VERSION "12.2.7"

NS_ :

BS_:

BU_: ACM ADAS_Body APM ASU_Gateway BCM BCM_BPM CCU_F CCU_R DUMMY_BCM_BPM ETG LDM_L LDM_R OCS_P PSM_D SRR_RR_M SHVU_F SHVU_R TRM USS_F USS_R XGW_Body

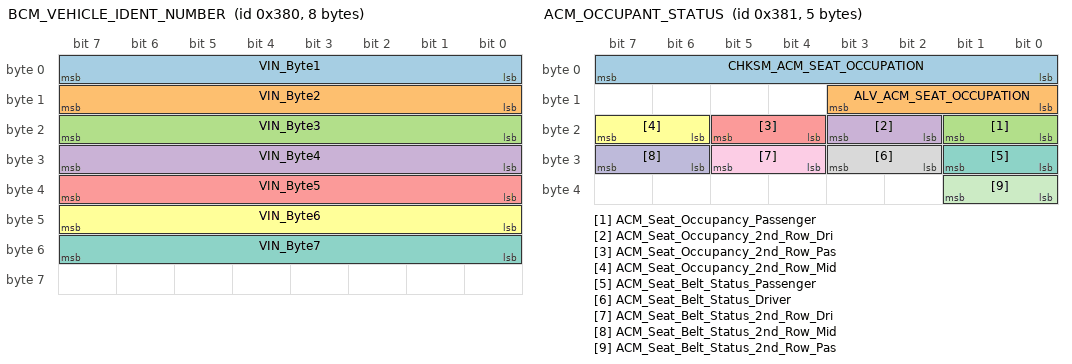
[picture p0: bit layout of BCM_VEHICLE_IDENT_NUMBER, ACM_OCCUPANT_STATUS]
BO_ 896 BCM_VEHICLE_IDENT_NUMBER: 8 BCM
 SG_ VIN_Byte1 : 7|8@0+ (1,0) [0|255] ""  ACM,APM,ASU_Gateway,BCM_BPM,CCU_F,CCU_R,ETG,LDM_L,LDM_R,OCS_P,PSM_D,SHVU_F,SHVU_R,TRM,XGW_Body
 SG_ VIN_Byte2 : 15|8@0+ (1,0) [0|255] ""  ACM,APM,ASU_Gateway,BCM_BPM,CCU_F,CCU_R,ETG,LDM_L,LDM_R,OCS_P,PSM_D,SHVU_F,SHVU_R,TRM,XGW_Body
 SG_ VIN_Byte3 : 23|8@0+ (1,0) [0|255] ""  ACM,APM,ASU_Gateway,BCM_BPM,CCU_F,CCU_R,ETG,LDM_L,LDM_R,OCS_P,PSM_D,SHVU_F,SHVU_R,TRM,XGW_Body
 SG_ VIN_Byte4 : 31|8@0+ (1,0) [0|255] ""  ACM,APM,ASU_Gateway,BCM_BPM,CCU_F,CCU_R,ETG,LDM_L,LDM_R,OCS_P,PSM_D,SHVU_F,SHVU_R,TRM,XGW_Body
 SG_ VIN_Byte5 : 39|8@0+ (1,0) [0|255] ""  ACM,APM,ASU_Gateway,BCM_BPM,CCU_F,CCU_R,ETG,LDM_L,LDM_R,OCS_P,PSM_D,SHVU_F,SHVU_R,TRM,XGW_Body
 SG_ VIN_Byte6 : 47|8@0+ (1,0) [0|255] ""  ACM,APM,ASU_Gateway,BCM_BPM,CCU_F,CCU_R,ETG,LDM_L,LDM_R,OCS_P,PSM_D,SHVU_F,SHVU_R,TRM,XGW_Body
 SG_ VIN_Byte7 : 55|8@0+ (1,0) [0|255] ""  ACM,APM,ASU_Gateway,BCM_BPM,CCU_F,CCU_R,ETG,LDM_L,LDM_R,OCS_P,PSM_D,SHVU_F,SHVU_R,TRM,XGW_Body

BO_ 897 ACM_OCCUPANT_STATUS: 5 ACM
 SG_ CHKSM_ACM_SEAT_OCCUPATION : 7|8@0+ (1,0) [0|255] ""  XGW_Body,CCU_F
 SG_ ALV_ACM_SEAT_OCCUPATION : 11|4@0+ (1,0) [0|14] ""  XGW_Body,CCU_F
 SG_ ACM_Seat_Occupancy_Passenger : 17|2@0+ (1,0) [0|3] ""  BCM,XGW_Body,CCU_F
 SG_ ACM_Seat_Occupancy_2nd_Row_Dri : 19|2@0+ (1,0) [0|3] ""  BCM,XGW_Body,CCU_F
 SG_ ACM_Seat_Occupancy_2nd_Row_Pas : 21|2@0+ (1,0) [0|3] "-"  BCM,XGW_Body,CCU_F
 SG_ ACM_Seat_Occupancy_2nd_Row_Mid : 23|2@0+ (1,0) [0|3] "-"  BCM,XGW_Body,CCU_F
 SG_ ACM_Seat_Belt_Status_Passenger : 25|2@0+ (1,0) [0|3] ""  XGW_Body,CCU_F
 SG_ ACM_Seat_Belt_Status_Driver : 27|2@0+ (1,0) [0|3] ""  BCM,XGW_Body,CCU_F
 SG_ ACM_Seat_Belt_Status_2nd_Row_Dri : 29|2@0+ (1,0) [0|3] "-"  XGW_Body,CCU_F
 SG_ ACM_Seat_Belt_Status_2nd_Row_Mid : 31|2@0+ (1,0) [0|3] ""  XGW_Body,CCU_F
 SG_ ACM_Seat_Belt_Status_2nd_Row_Pas : 33|2@0+ (1,0) [0|3] "-"  XGW_Body,CCU_F

BO_ 905 VCU_Sts3: 8 XGW_Body
 SG_ VCU_IMMO_Sts : 35|2@0+ (1,0) [0|3] ""  BCM
 SG_ SECCAN_VCU_IMMO_Sts : 63|8@0+ (1,0) [0|255] ""  BCM

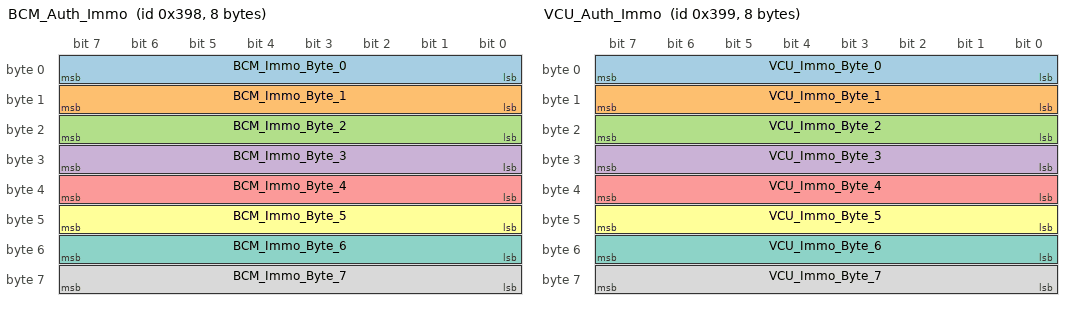
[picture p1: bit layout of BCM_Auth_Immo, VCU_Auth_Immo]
BO_ 920 BCM_Auth_Immo: 8 BCM
 SG_ BCM_Immo_Byte_0 : 7|8@0+ (1,0) [0|255] ""  XGW_Body
 SG_ BCM_Immo_Byte_1 : 15|8@0+ (1,0) [0|255] ""  XGW_Body
 SG_ BCM_Immo_Byte_2 : 23|8@0+ (1,0) [0|255] ""  XGW_Body
 SG_ BCM_Immo_Byte_3 : 31|8@0+ (1,0) [0|255] ""  XGW_Body
 SG_ BCM_Immo_Byte_4 : 39|8@0+ (1,0) [0|255] ""  XGW_Body
 SG_ BCM_Immo_Byte_5 : 47|8@0+ (1,0) [0|255] ""  XGW_Body
 SG_ BCM_Immo_Byte_6 : 55|8@0+ (1,0) [0|255] ""  XGW_Body
 SG_ BCM_Immo_Byte_7 : 63|8@0+ (1,0) [0|255] ""  XGW_Body

BO_ 921 VCU_Auth_Immo: 8 XGW_Body
 SG_ VCU_Immo_Byte_0 : 7|8@0+ (1,0) [0|255] ""  BCM
 SG_ VCU_Immo_Byte_1 : 15|8@0+ (1,0) [0|255] ""  BCM
 SG_ VCU_Immo_Byte_2 : 23|8@0+ (1,0) [0|255] ""  BCM
 SG_ VCU_Immo_Byte_3 : 31|8@0+ (1,0) [0|255] ""  BCM
 SG_ VCU_Immo_Byte_4 : 39|8@0+ (1,0) [0|255] ""  BCM
 SG_ VCU_Immo_Byte_5 : 47|8@0+ (1,0) [0|255] ""  BCM
 SG_ VCU_Immo_Byte_6 : 55|8@0+ (1,0) [0|255] ""  BCM
 SG_ VCU_Immo_Byte_7 : 63|8@0+ (1,0) [0|255] ""  BCM

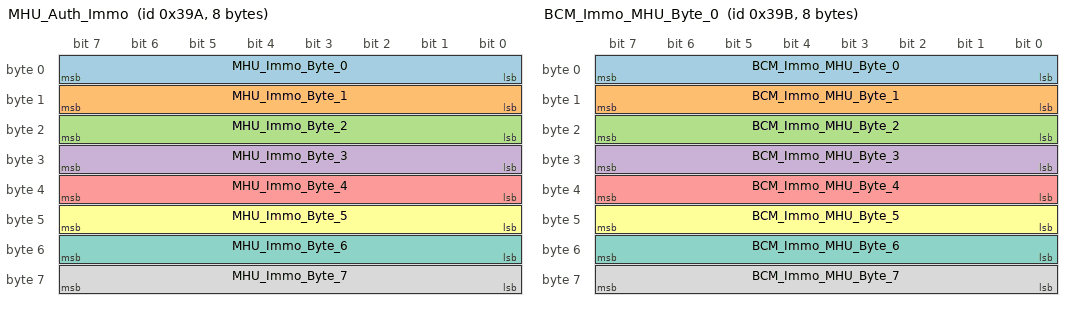
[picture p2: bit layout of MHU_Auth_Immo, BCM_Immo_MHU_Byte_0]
BO_ 922 MHU_Auth_Immo: 8 XGW_Body
 SG_ MHU_Immo_Byte_0 : 7|8@0+ (1,0) [0|255] "-"  BCM
 SG_ MHU_Immo_Byte_1 : 15|8@0+ (1,0) [0|255] "-"  BCM
 SG_ MHU_Immo_Byte_2 : 23|8@0+ (1,0) [0|255] ""  BCM
 SG_ MHU_Immo_Byte_3 : 31|8@0+ (1,0) [0|255] ""  BCM
 SG_ MHU_Immo_Byte_4 : 39|8@0+ (1,0) [0|255] ""  BCM
 SG_ MHU_Immo_Byte_5 : 47|8@0+ (1,0) [0|255] ""  BCM
 SG_ MHU_Immo_Byte_6 : 55|8@0+ (1,0) [0|255] ""  BCM
 SG_ MHU_Immo_Byte_7 : 63|8@0+ (1,0) [0|255] "-"  BCM

BO_ 923 BCM_Immo_MHU_Byte_0: 8 BCM
 SG_ BCM_Immo_MHU_Byte_0 : 7|8@0+ (1,0) [0|255] "-"  XGW_Body
 SG_ BCM_Immo_MHU_Byte_1 : 15|8@0+ (1,0) [0|255] "-"  XGW_Body
 SG_ BCM_Immo_MHU_Byte_2 : 23|8@0+ (1,0) [0|255] "-"  XGW_Body
 SG_ BCM_Immo_MHU_Byte_3 : 31|8@0+ (1,0) [0|255] "-"  XGW_Body
 SG_ BCM_Immo_MHU_Byte_4 : 39|8@0+ (1,0) [0|255] "-"  XGW_Body
 SG_ BCM_Immo_MHU_Byte_5 : 47|8@0+ (1,0) [0|255] ""  XGW_Body
 SG_ BCM_Immo_MHU_Byte_6 : 55|8@0+ (1,0) [0|255] "-"  XGW_Body
 SG_ BCM_Immo_MHU_Byte_7 : 63|8@0+ (1,0) [0|255] "-"  XGW_Body

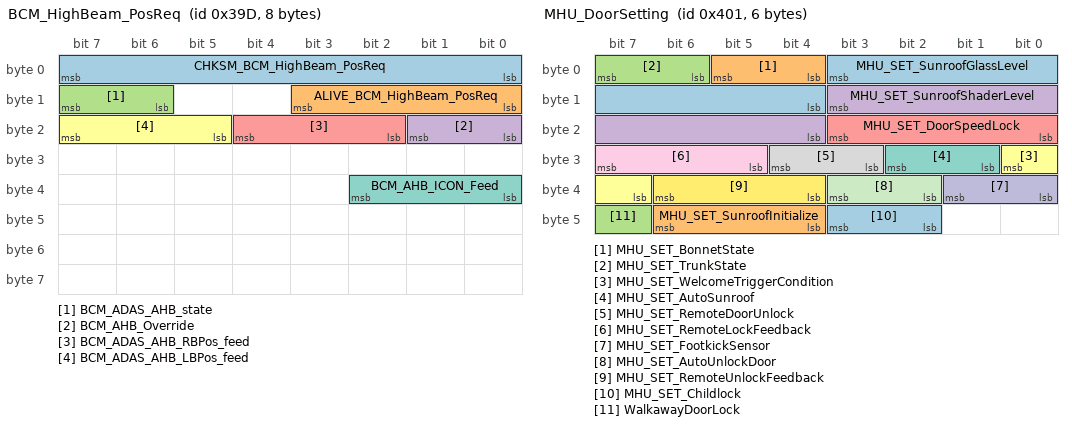
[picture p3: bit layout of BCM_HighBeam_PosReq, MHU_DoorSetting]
BO_ 925 BCM_HighBeam_PosReq: 8 BCM
 SG_ CHKSM_BCM_HighBeam_PosReq : 7|8@0+ (1,0) [0|255] ""  XGW_Body
 SG_ ALIVE_BCM_HighBeam_PosReq : 11|4@0+ (1,0) [0|14] ""  XGW_Body
 SG_ BCM_ADAS_AHB_state : 15|2@0+ (1,0) [0|3] ""  XGW_Body
 SG_ BCM_AHB_Override : 17|2@0+ (1,0) [0|3] ""  LDM_L,LDM_R,XGW_Body
 SG_ BCM_ADAS_AHB_RBPos_feed : 20|3@0+ (1,0) [0|7] ""  XGW_Body
 SG_ BCM_ADAS_AHB_LBPos_feed : 23|3@0+ (1,0) [0|7] ""  XGW_Body
 SG_ BCM_AHB_ICON_Feed : 34|3@0+ (1,0) [0|7] ""  XGW_Body

BO_ 993 VCU_HMI_Info: 8 XGW_Body
 SG_ CRC_VCU_HMI_Info : 7|8@0+ (1,0) [0|255] ""  ACM
 SG_ ALIV_VCU_HMI_Info : 11|4@0+ (1,0) [0|14] ""  ACM
 SG_ VCU_CruiseCtrlSts : 31|3@0+ (1,0) [0|7] ""  ACM

BO_ 1015 MFS_Control_Button: 8 XGW_Body
 SG_ CHSKM_MFS_Control_Button : 7|8@0+ (1,0) [0|255] ""  BCM
 SG_ ALV_MFS_Control_Button : 11|4@0+ (1,0) [0|14] ""  BCM
 SG_ MFS_VoiceRecognitionOn_Off : 15|3@0+ (1,0) [0|4] "Bit"  BCM
 SG_ MFS_ISAControl : 17|2@0+ (1,0) [0|3] "Bit"  BCM
 SG_ MFS_CruiseSpeedIncrease : 20|3@0+ (1,0) [0|4] "Bit"  BCM
 SG_ MFS_TelephoneCall_EndCall : 23|3@0+ (1,0) [0|4] "Bit"  BCM
 SG_ MFS_LKAControl : 25|2@0+ (1,0) [0|3] "Bit"  BCM
 SG_ MFS_CruiseGapIncrease : 28|3@0+ (1,0) [0|4] "Bit"  BCM
 SG_ MFS_CruiseOn_Off : 31|3@0+ (1,0) [0|4] "Bit"  BCM
 SG_ MFS_CruiseGapDecrease : 34|3@0+ (1,0) [0|4] "Bit"  BCM
 SG_ MFS_CAN_RESControl : 36|2@0+ (1,0) [0|3] "-"  BCM
 SG_ MFS_CruiseSpeedDecrease : 39|3@0+ (1,0) [0|4] "Bit"  BCM
 SG_ MFS_M2Control : 41|2@0+ (1,0) [0|3] "Bit"  BCM
 SG_ MFS_SourseControl : 44|3@0+ (1,0) [0|4] "Bit"  BCM
 SG_ MFS_UpControl : 47|3@0+ (1,0) [0|4] "Bit"  BCM
 SG_ MFS_DownControl : 52|3@0+ (1,0) [0|4] "Bit"  BCM
 SG_ MFS_LeftControl : 55|3@0+ (1,0) [0|4] "Bit"  BCM
 SG_ MFS_Failure : 57|1@0+ (1,0) [0|1] "Bit"  BCM
 SG_ MFS_RightControl : 60|3@0+ (1,0) [0|4] "Bit"  BCM
 SG_ MFS_OK_Control : 63|3@0+ (1,0) [0|4] "Bit"  BCM

BO_ 1025 MHU_DoorSetting: 6 XGW_Body
 SG_ MHU_SET_SunroofGlassLevel : 3|8@0+ (1,0) [0|255] "%"  BCM
 SG_ MHU_SET_BonnetState : 5|2@0+ (1,0) [0|3] "-"  BCM
 SG_ MHU_SET_TrunkState : 7|2@0+ (1,0) [0|3] "-"  BCM
 SG_ MHU_SET_SunroofShaderLevel : 11|8@0+ (1,0) [0|255] "%"  BCM
 SG_ MHU_SET_DoorSpeedLock : 19|4@0+ (1,0) [0|7] ""  BCM
 SG_ MHU_SET_WelcomeTriggerCondition : 24|2@0+ (1,0) [0|3] ""  BCM
 SG_ MHU_SET_AutoSunroof : 26|2@0+ (1,0) [0|3] ""  BCM
 SG_ MHU_SET_RemoteDoorUnlock : 28|2@0+ (1,0) [0|3] "-"  BCM
 SG_ MHU_SET_RemoteLockFeedback : 31|3@0+ (1,0) [0|7] "-"  BCM
 SG_ MHU_SET_FootkickSensor : 33|2@0+ (1,0) [0|3] "-"  BCM
 SG_ MHU_SET_AutoUnlockDoor : 35|2@0+ (1,0) [0|3] ""  BCM
 SG_ MHU_SET_RemoteUnlockFeedback : 38|3@0+ (1,0) [0|7] ""  BCM
 SG_ MHU_SET_Childlock : 43|2@0+ (1,0) [0|3] ""  BCM
 SG_ MHU_SET_SunroofInitialize : 46|3@0+ (1,0) [0|7] ""  BCM
 SG_ WalkawayDoorLock : 47|1@0+ (1,0) [0|1] "" BCM

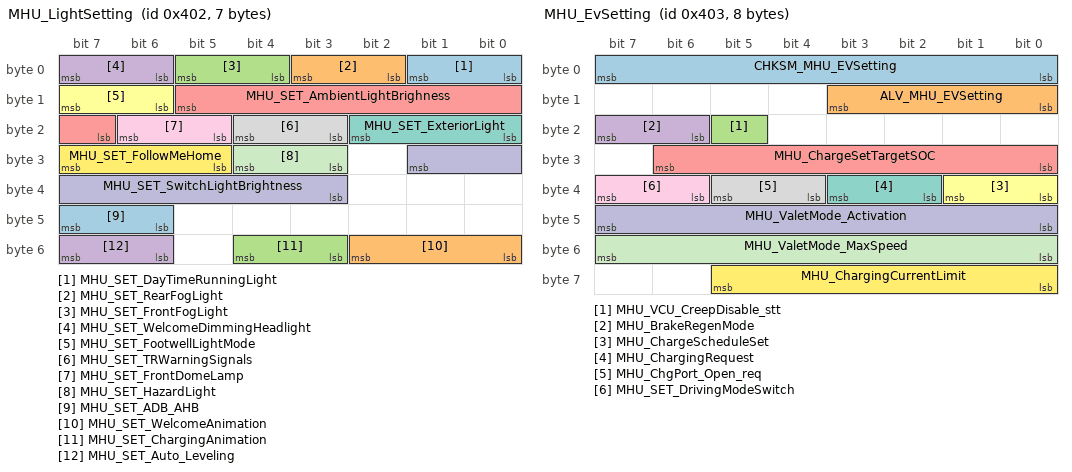
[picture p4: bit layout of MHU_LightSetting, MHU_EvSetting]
BO_ 1026 MHU_LightSetting: 7 XGW_Body
 SG_ MHU_SET_DayTimeRunningLight : 1|2@0+ (1,0) [0|3] "-"  BCM,LDM_L,LDM_R
 SG_ MHU_SET_RearFogLight : 3|2@0+ (1,0) [0|3] ""  BCM,LDM_L,LDM_R
 SG_ MHU_SET_FrontFogLight : 5|2@0+ (1,0) [0|3] ""  BCM,LDM_L,LDM_R
 SG_ MHU_SET_WelcomeDimmingHeadlight : 7|2@0+ (1,0) [0|3] ""  BCM,LDM_L,LDM_R
 SG_ MHU_SET_AmbientLightBrighness : 13|7@0+ (1,0) [0|100] "%"  BCM,LDM_L,LDM_R
 SG_ MHU_SET_FootwellLightMode : 15|2@0+ (1,0) [0|3] "-"  BCM,LDM_L,LDM_R
 SG_ MHU_SET_ExteriorLight : 18|3@0+ (1,0) [0|7] ""  BCM,LDM_L,LDM_R
 SG_ MHU_SET_TRWarningSignals : 20|2@0+ (1,0) [0|3] ""  BCM
 SG_ MHU_SET_FrontDomeLamp : 22|2@0+ (1,0) [0|3] ""  BCM,LDM_L,LDM_R
 SG_ MHU_SET_SwitchLightBrightness : 25|7@0+ (1,0) [0|100] "%"  BCM,LDM_L,LDM_R
 SG_ MHU_SET_HazardLight : 28|2@0+ (1,0) [0|3] ""  BCM
 SG_ MHU_SET_FollowMeHome : 31|3@0+ (1,0) [0|7] ""  BCM,LDM_L,LDM_R
 SG_ MHU_SET_ADB_AHB : 47|2@0+ (1,0) [0|3] ""  BCM,LDM_L
 SG_ MHU_SET_WelcomeAnimation : 50|3@0+ (1,0) [0|5] ""  BCM
 SG_ MHU_SET_ChargingAnimation : 52|2@0+ (1,0) [0|3] ""  BCM
 SG_ MHU_SET_Auto_Leveling : 55|2@0+ (1,0) [0|3] "-"  BCM,LDM_L

BO_ 1027 MHU_EvSetting: 8 XGW_Body
 SG_ CHKSM_MHU_EVSetting : 7|8@0+ (1,0) [0|255] ""  BCM
 SG_ ALV_MHU_EVSetting : 11|4@0+ (1,0) [0|14] ""  BCM
 SG_ MHU_VCU_CreepDisable_stt : 21|1@0+ (1,0) [0|1] ""  BCM
 SG_ MHU_BrakeRegenMode : 23|2@0+ (1,0) [0|3] "" Vector__XXX
 SG_ MHU_ChargeSetTargetSOC : 30|7@0+ (1,0) [10|100] "%" Vector__XXX
 SG_ MHU_ChargeScheduleSet : 33|2@0+ (1,0) [0|3] "" Vector__XXX
 SG_ MHU_ChargingRequest : 35|2@0+ (1,0) [0|3] "-"  BCM
 SG_ MHU_ChgPort_Open_req : 37|2@0+ (1,0) [0|3] "-"  BCM
 SG_ MHU_SET_DrivingModeSwitch : 39|2@0+ (1,0) [0|3] "-"  BCM
 SG_ MHU_ValetMode_Activation : 47|8@0+ (1,0) [0|255] "" Vector__XXX
 SG_ MHU_ValetMode_MaxSpeed : 55|8@0+ (1,0) [0|255] "km/h" Vector__XXX
 SG_ MHU_ChargingCurrentLimit : 61|6@0+ (1,0) [0|62] "A"  BCM

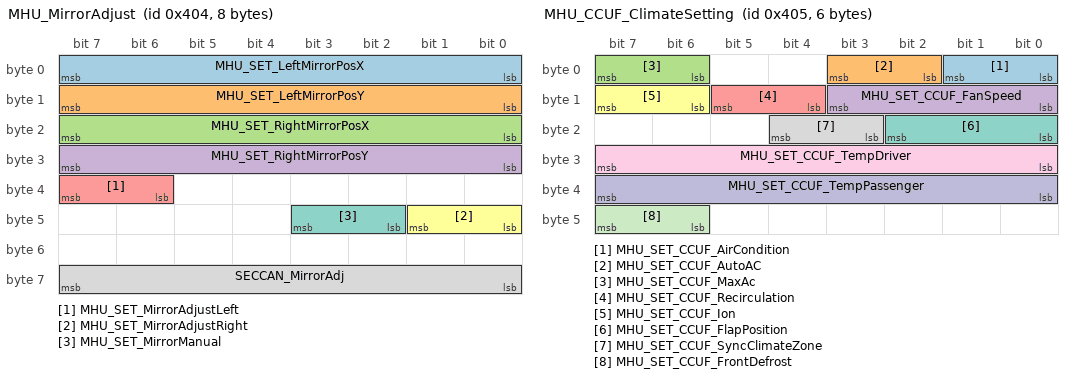
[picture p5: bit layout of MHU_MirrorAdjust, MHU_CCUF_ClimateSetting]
BO_ 1028 MHU_MirrorAdjust: 8 XGW_Body
 SG_ MHU_SET_LeftMirrorPosX : 7|8@0+ (1,-15) [-15|15] "deg"  BCM
 SG_ MHU_SET_LeftMirrorPosY : 15|8@0+ (1,-15) [-15|15] "deg"  BCM
 SG_ MHU_SET_RightMirrorPosX : 23|8@0+ (1,-15) [-15|15] "deg"  BCM
 SG_ MHU_SET_RightMirrorPosY : 31|8@0+ (1,-15) [-15|15] "deg"  BCM
 SG_ MHU_SET_MirrorAdjustLeft : 39|2@0+ (1,0) [0|3] "-"  BCM
 SG_ MHU_SET_MirrorAdjustRight : 41|2@0+ (1,0) [0|3] "-"  BCM
 SG_ MHU_SET_MirrorManual : 43|2@0+ (1,0) [0|3] ""  BCM
 SG_ SECCAN_MirrorAdj : 63|8@0+ (1,0) [0|255] ""  BCM

BO_ 1029 MHU_CCUF_ClimateSetting: 6 XGW_Body
 SG_ MHU_SET_CCUF_AirCondition : 1|2@0+ (1,0) [0|3] ""  CCU_F
 SG_ MHU_SET_CCUF_AutoAC : 3|2@0+ (1,0) [0|3] ""  CCU_F
 SG_ MHU_SET_CCUF_MaxAc : 7|2@0+ (1,0) [0|3] ""  CCU_F
 SG_ MHU_SET_CCUF_FanSpeed : 11|4@0+ (1,0) [0|7] "-"  CCU_F
 SG_ MHU_SET_CCUF_Recirculation : 13|2@0+ (1,0) [0|3] ""  CCU_F
 SG_ MHU_SET_CCUF_Ion : 15|2@0+ (1,0) [0|3] "-"  CCU_F
 SG_ MHU_SET_CCUF_FlapPosition : 18|3@0+ (1,0) [0|7] "-"  CCU_F
 SG_ MHU_SET_CCUF_SyncClimateZone : 20|2@0+ (1,0) [0|3] "-"  CCU_F
 SG_ MHU_SET_CCUF_TempDriver : 31|8@0+ (0.5,0) [16|32] "Degree C"  CCU_F
 SG_ MHU_SET_CCUF_TempPassenger : 39|8@0+ (0.5,0) [16|32] "Degree C"  CCU_F
 SG_ MHU_SET_CCUF_FrontDefrost : 47|2@0+ (1,0) [0|3] ""  CCU_F

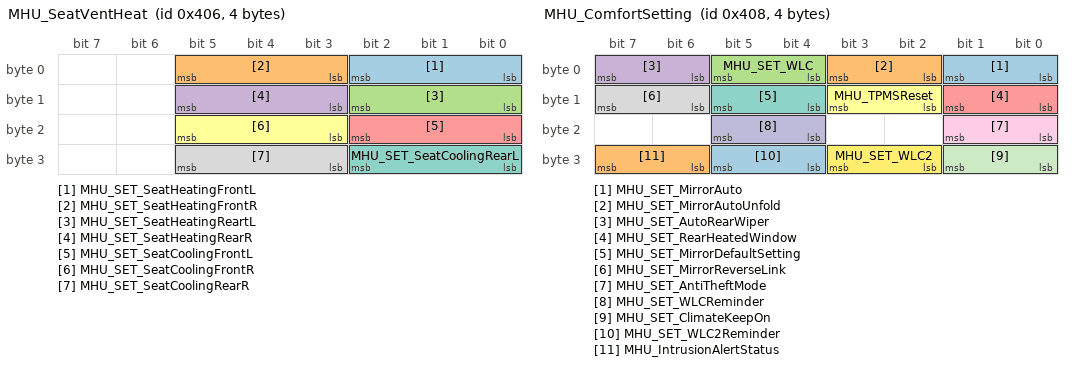
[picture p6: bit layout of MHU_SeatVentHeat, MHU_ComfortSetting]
BO_ 1030 MHU_SeatVentHeat: 4 XGW_Body
 SG_ MHU_SET_SeatHeatingFrontL : 2|3@0+ (1,0) [0|7] "-"  SHVU_F
 SG_ MHU_SET_SeatHeatingFrontR : 5|3@0+ (1,0) [0|7] "-"  SHVU_F
 SG_ MHU_SET_SeatHeatingReartL : 10|3@0+ (1,0) [0|7] "-"  SHVU_R
 SG_ MHU_SET_SeatHeatingRearR : 13|3@0+ (1,0) [0|7] "-"  SHVU_R
 SG_ MHU_SET_SeatCoolingFrontL : 18|3@0+ (1,0) [0|7] "-"  SHVU_F
 SG_ MHU_SET_SeatCoolingFrontR : 21|3@0+ (1,0) [0|7] ""  SHVU_F
 SG_ MHU_SET_SeatCoolingRearL : 26|3@0+ (1,0) [0|7] ""  SHVU_R
 SG_ MHU_SET_SeatCoolingRearR : 29|3@0+ (1,0) [0|7] "-"  SHVU_R

BO_ 1032 MHU_ComfortSetting: 4 XGW_Body
 SG_ MHU_SET_MirrorAuto : 1|2@0+ (1,0) [0|3] ""  BCM
 SG_ MHU_SET_MirrorAutoUnfold : 3|2@0+ (1,0) [0|3] ""  BCM
 SG_ MHU_SET_WLC : 5|2@0+ (1,0) [0|3] "-"  BCM
 SG_ MHU_SET_AutoRearWiper : 7|2@0+ (1,0) [0|3] "-"  BCM
 SG_ MHU_SET_RearHeatedWindow : 9|2@0+ (1,0) [0|3] ""  BCM
 SG_ MHU_TPMSReset : 11|2@0+ (1,0) [0|3] ""  BCM
 SG_ MHU_SET_MirrorDefaultSetting : 13|2@0+ (1,0) [0|3] ""  BCM
 SG_ MHU_SET_MirrorReverseLink : 15|2@0+ (1,0) [0|3] "-"  BCM
 SG_ MHU_SET_AntiTheftMode : 17|2@0+ (1,0) [0|3] ""  BCM
 SG_ MHU_SET_WLCReminder : 21|2@0+ (1,0) [0|3] ""  BCM
 SG_ MHU_SET_ClimateKeepOn : 25|2@0+ (1,0) [0|3] ""  BCM
 SG_ MHU_SET_WLC2 : 27|2@0+ (1,0) [0|3] "-"  BCM
 SG_ MHU_SET_WLC2Reminder : 29|2@0+ (1,0) [0|3] "-"  BCM
 SG_ MHU_IntrusionAlertStatus : 31|2@0+ (1,0) [0|3] "-"  BCM

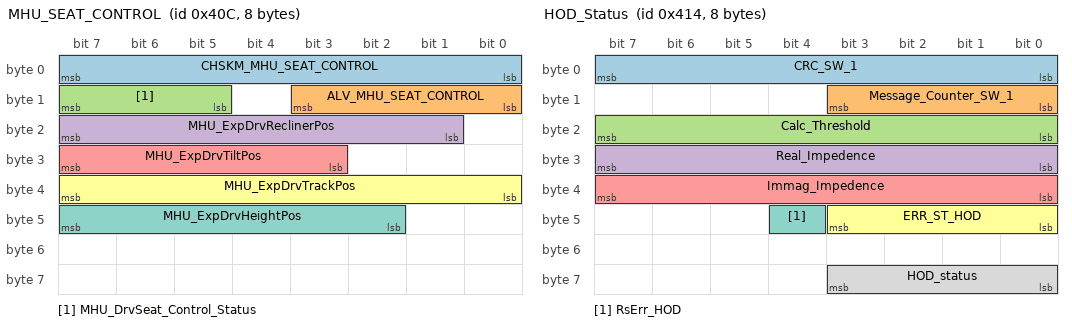
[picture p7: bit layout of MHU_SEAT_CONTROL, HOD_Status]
BO_ 1036 MHU_SEAT_CONTROL: 8 XGW_Body
 SG_ CHSKM_MHU_SEAT_CONTROL : 7|8@0+ (1,0) [0|255] ""  PSM_D
 SG_ ALV_MHU_SEAT_CONTROL : 11|4@0+ (1,0) [0|14] ""  PSM_D
 SG_ MHU_DrvSeat_Control_Status : 15|3@0+ (1,0) [0|7] "-"  PSM_D
 SG_ MHU_ExpDrvReclinerPos : 23|7@0+ (1,0) [0|127] "degree"  PSM_D
 SG_ MHU_ExpDrvTiltPos : 31|5@0+ (1,0) [0|31] "mm"  PSM_D
 SG_ MHU_ExpDrvTrackPos : 39|8@0+ (1,0) [0|255] "mm"  PSM_D
 SG_ MHU_ExpDrvHeightPos : 47|6@0+ (1,0) [0|63] "mm"  PSM_D

BO_ 1037 MHU_DIGIT_SPEED: 5 XGW_Body
 SG_ CHKSM_MHU_DIGIT_SPEED : 7|8@0+ (1,0) [0|255] ""  ACM
 SG_ ALV_MHU_DIGIT_SPEED : 11|4@0+ (1,0) [0|14] ""  ACM
 SG_ MHU_DigitSpeed : 23|9@0+ (1,0) [0|300] "km/h"  ACM

BO_ 1042 MHU_eCall_system_status: 8 XGW_Body
 SG_ eCall_state : 2|3@0+ (1,0) [0|7] ""  ACM

BO_ 1044 HOD_Status: 8 XGW_Body
 SG_ CRC_SW_1 : 7|8@0+ (1,0) [0|255] ""  Vector__XXX
 SG_ Message_Counter_SW_1 : 11|4@0+ (1,0) [0|14] ""  Vector__XXX
 SG_ Calc_Threshold : 23|8@0+ (1,0) [0|255] ""  Vector__XXX
 SG_ Real_Impedence : 31|8@0+ (1,0) [0|255] ""  Vector__XXX
 SG_ Immag_Impedence : 39|8@0+ (1,0) [0|255] ""  Vector__XXX
 SG_ ERR_ST_HOD : 43|4@0+ (1,0) [0|15] ""  Vector__XXX
 SG_ RsErr_HOD : 44|1@0+ (1,0) [0|1] ""  Vector__XXX
 SG_ HOD_status : 59|4@0+ (1,0) [0|15] ""  Vector__XXX

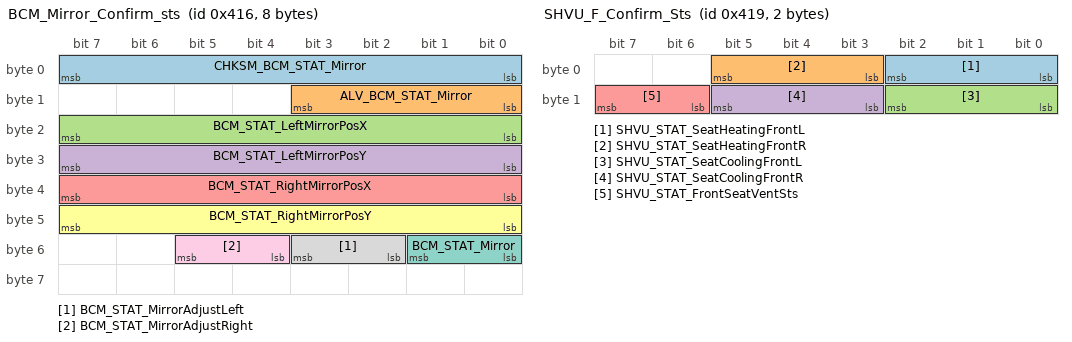
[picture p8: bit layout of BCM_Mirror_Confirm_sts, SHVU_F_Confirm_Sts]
BO_ 1046 BCM_Mirror_Confirm_sts: 8 BCM
 SG_ CHKSM_BCM_STAT_Mirror : 7|8@0+ (1,0) [0|255] ""  XGW_Body
 SG_ ALV_BCM_STAT_Mirror : 11|4@0+ (1,0) [0|14] ""  XGW_Body
 SG_ BCM_STAT_LeftMirrorPosX : 23|8@0+ (1,-15) [-15|15] "deg"  XGW_Body
 SG_ BCM_STAT_LeftMirrorPosY : 31|8@0+ (1,-15) [-15|15] "deg"  XGW_Body
 SG_ BCM_STAT_RightMirrorPosX : 39|8@0+ (1,-15) [-15|15] "deg"  XGW_Body
 SG_ BCM_STAT_RightMirrorPosY : 47|8@0+ (1,-15) [-15|15] "deg"  XGW_Body
 SG_ BCM_STAT_Mirror : 49|2@0+ (1,0) [0|3] ""  XGW_Body
 SG_ BCM_STAT_MirrorAdjustLeft : 51|2@0+ (1,0) [0|3] "-"  XGW_Body
 SG_ BCM_STAT_MirrorAdjustRight : 53|2@0+ (1,0) [0|3] ""  XGW_Body

BO_ 1049 SHVU_F_Confirm_Sts: 2 SHVU_F
 SG_ SHVU_STAT_SeatHeatingFrontL : 2|3@0+ (1,0) [0|7] "-"  XGW_Body
 SG_ SHVU_STAT_SeatHeatingFrontR : 5|3@0+ (1,0) [0|7] "-"  XGW_Body
 SG_ SHVU_STAT_SeatCoolingFrontL : 10|3@0+ (1,0) [0|7] "-"  XGW_Body
 SG_ SHVU_STAT_SeatCoolingFrontR : 13|3@0+ (1,0) [0|7] ""  XGW_Body
 SG_ SHVU_STAT_FrontSeatVentSts : 15|2@0+ (1,0) [0|3] ""  XGW_Body

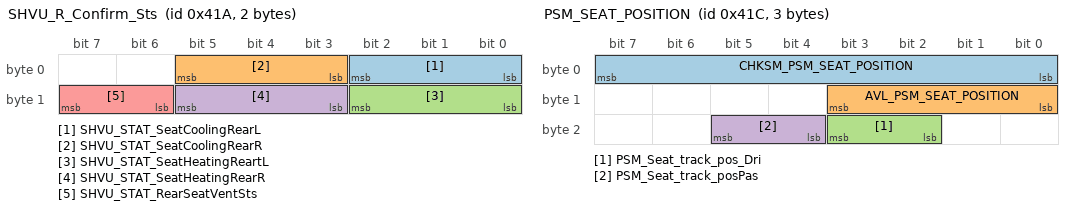
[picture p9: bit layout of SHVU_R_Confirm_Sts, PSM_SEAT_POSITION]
BO_ 1050 SHVU_R_Confirm_Sts: 2 SHVU_R
 SG_ SHVU_STAT_SeatCoolingRearL : 2|3@0+ (1,0) [0|7] "-"  XGW_Body
 SG_ SHVU_STAT_SeatCoolingRearR : 5|3@0+ (1,0) [0|7] ""  XGW_Body
 SG_ SHVU_STAT_SeatHeatingReartL : 10|3@0+ (1,0) [0|7] ""  XGW_Body
 SG_ SHVU_STAT_SeatHeatingRearR : 13|3@0+ (1,0) [0|7] ""  XGW_Body
 SG_ SHVU_STAT_RearSeatVentSts : 15|2@0+ (1,0) [0|3] ""  XGW_Body

BO_ 1052 PSM_SEAT_POSITION: 3 PSM_D
 SG_ CHKSM_PSM_SEAT_POSITION : 7|8@0+ (1,0) [0|255] ""  ACM,XGW_Body
 SG_ AVL_PSM_SEAT_POSITION : 11|4@0+ (1,0) [0|14] "-"  ACM,XGW_Body
 SG_ PSM_Seat_track_pos_Dri : 19|2@0+ (1,0) [0|3] ""  ACM,XGW_Body
 SG_ PSM_Seat_track_posPas : 21|2@0+ (1,0) [0|3] ""  ACM,XGW_Body

BO_ 1053 BCM_Comfort_Confirm_sts: 8 BCM
 SG_ BCM_STAT_AutoRearWiper : 1|2@0+ (1,0) [0|3] "-"  XGW_Body
 SG_ BCM_STAT_MirrorFoldSetting : 3|2@0+ (1,0) [0|3] ""  XGW_Body
 SG_ BCM_STAT_IMMO_KeyfobID2 : 7|3@0+ (1,0) [0|7] ""  XGW_Body
 SG_ BCM_STAT_MirrorAutoUnfold : 9|2@0+ (1,0) [0|3] "-"  XGW_Body
 SG_ BCM_STAT_MirrorReverseLink : 11|2@0+ (1,0) [0|3] ""  XGW_Body
 SG_ BCM_STAT_MirrorDefaultSTATting : 13|2@0+ (1,0) [0|3] "-"  XGW_Body
 SG_ BCM_STAT_WelcomeTriggerCondition : 15|2@0+ (1,0) [0|3] ""  XGW_Body
 SG_ BCM_STAT_FrontDomeLamp : 17|2@0+ (1,0) [0|3] "-"  XGW_Body
 SG_ BCM_STAT_FollowMeHome : 20|3@0+ (1,0) [0|7] "-"  XGW_Body
 SG_ BCM_STAT_ExteriorLight : 23|3@0+ (1,0) [0|7] "-"  XGW_Body
 SG_ BCM_STAT_RemoteLockFeedback : 26|3@0+ (1,0) [0|7] "-"  XGW_Body,SRR_RR_M
 SG_ BCM_STAT_RemoteDoorUnlock : 28|2@0+ (1,0) [0|3] ""  XGW_Body,SRR_RR_M
 SG_ BCM_STAT_AutoDoorUnlock : 30|2@0+ (1,0) [0|3] ""  XGW_Body,SRR_RR_M
 SG_ BCM_STAT_WalkawayDoorLock : 31|1@0+ (1,0) [0|1] "" XGW_Body
 SG_ BCM_STAT_AmbientLightBrighness : 39|7@0+ (1,0) [0|100] "%"  XGW_Body
 SG_ BCM_STAT_WiperServiceMode : 42|2@0+ (1,0) [0|3] ""  XGW_Body
 SG_ BCM_STAT_IMMO_KeyfobID : 45|2@0+ (1,0) [0|3] ""  XGW_Body
 SG_ BCM_STAT_RearHeatedWindowMirror : 47|2@0+ (1,0) [0|3] ""  XGW_Body
 SG_ BCM_STAT_AntiTheftMode : 50|3@0+ (1,0) [0|7] "-"  XGW_Body
 SG_ BCM_STAT_ClimateKeepOnSts : 53|2@0+ (1,0) [0|3] ""  XGW_Body,CCU_F,CCU_R
 SG_ BCM_STAT_FKSfeedback : 55|2@0+ (1,0) [0|3] ""  XGW_Body
 SG_ SECCAN_CmftCnfrm : 63|8@0+ (1,0) [0|255] ""  XGW_Body

BO_ 1055 OCS_PasSts: 3 OCS_P
 SG_ OCS_P_CHKSM : 7|8@0+ (1,0) [0|255] ""  ACM
 SG_ OCS_P_AVL : 11|4@0+ (1,0) [0|14] ""  ACM
 SG_ OCS_Passenger_class_stat : 17|2@0+ (1,0) [0|3] ""  ACM

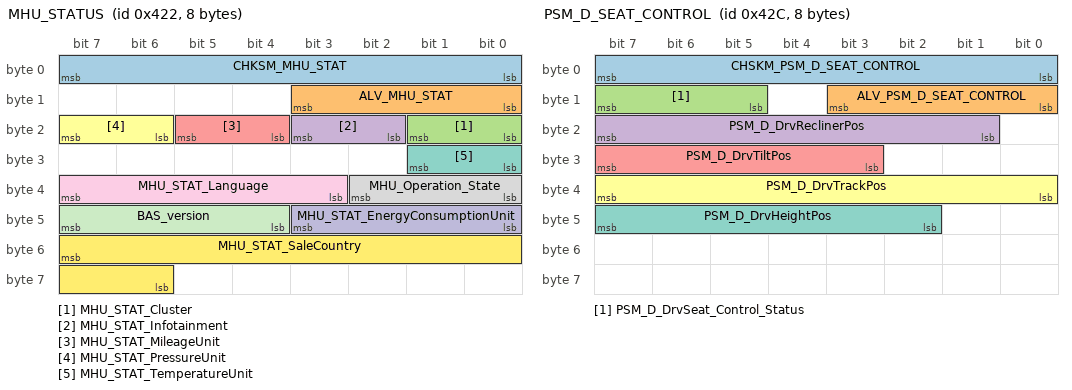
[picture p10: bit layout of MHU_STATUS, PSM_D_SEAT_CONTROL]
BO_ 1058 MHU_STATUS: 8 XGW_Body
 SG_ CHKSM_MHU_STAT : 7|8@0+ (1,0) [0|255] ""  CCU_F,PSM_D,SHVU_F,SHVU_R
 SG_ ALV_MHU_STAT : 11|4@0+ (1,0) [0|14] ""  CCU_F,PSM_D,SHVU_F,SHVU_R
 SG_ MHU_STAT_Cluster : 17|2@0+ (1,0) [0|3] "-"  CCU_F
 SG_ MHU_STAT_Infotainment : 19|2@0+ (1,0) [0|3] ""  CCU_F,PSM_D,SHVU_F,SHVU_R
 SG_ MHU_STAT_MileageUnit : 21|2@0+ (1,0) [0|3] ""  CCU_F,PSM_D,SHVU_F,SHVU_R
 SG_ MHU_STAT_PressureUnit : 23|2@0+ (1,0) [0|3] "-"  CCU_F,PSM_D,SHVU_F,SHVU_R
 SG_ MHU_STAT_TemperatureUnit : 25|2@0+ (1,0) [0|3] "-"  CCU_F,PSM_D,SHVU_F,SHVU_R
 SG_ MHU_Operation_State : 34|3@0+ (1,0) [0|7] ""  CCU_F,PSM_D,SHVU_F,SHVU_R
 SG_ MHU_STAT_Language : 39|5@0+ (1,0) [0|31] "-"  CCU_F,PSM_D,SHVU_F,SHVU_R
 SG_ MHU_STAT_EnergyConsumptionUnit : 43|4@0+ (1,0) [0|15] "-"  CCU_F,PSM_D,SHVU_F,SHVU_R
 SG_ BAS_version : 47|4@0+ (1,0) [0|15] "" Vector__XXX
 SG_ MHU_STAT_SaleCountry : 55|10@0+ (1,0) [0|1023] "-"  CCU_F,PSM_D,SHVU_F,SHVU_R

 BO_ 1064 XGW_CH_1: 1 XGW_Body
 SG_ TRMFitted : 2|2@0+ (1,0) [0|3] "" USS_F,USS_R

BO_ 1068 PSM_D_SEAT_CONTROL: 8 PSM_D
 SG_ CHSKM_PSM_D_SEAT_CONTROL : 7|8@0+ (1,0) [0|255] ""  XGW_Body
 SG_ ALV_PSM_D_SEAT_CONTROL : 11|4@0+ (1,0) [0|14] ""  XGW_Body
 SG_ PSM_D_DrvSeat_Control_Status : 15|3@0+ (1,0) [0|7] ""  XGW_Body
 SG_ PSM_D_DrvReclinerPos : 23|7@0+ (1,0) [0|127] "degree"  XGW_Body
 SG_ PSM_D_DrvTiltPos : 31|5@0+ (1,0) [0|31] "mm"  XGW_Body
 SG_ PSM_D_DrvTrackPos : 39|8@0+ (1,0) [0|255] "mm"  XGW_Body
 SG_ PSM_D_DrvHeightPos : 47|6@0+ (1,0) [0|63] "mm"  XGW_Body

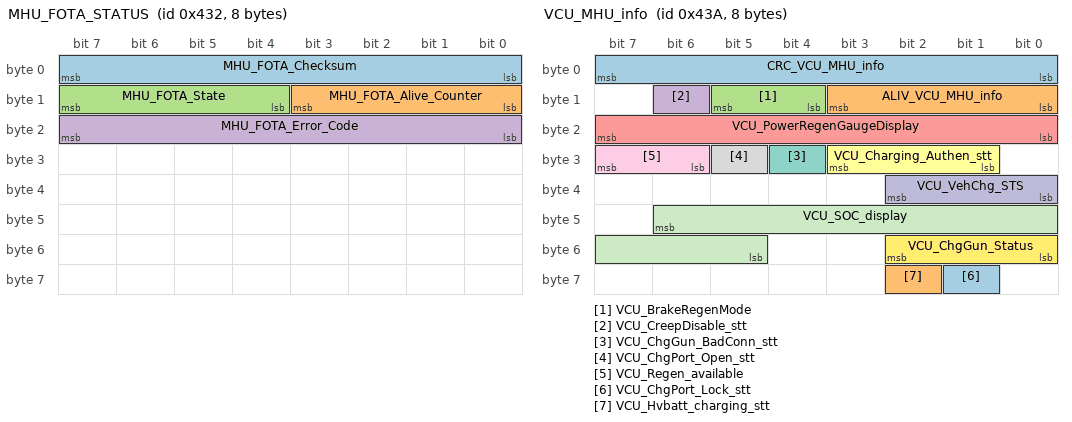
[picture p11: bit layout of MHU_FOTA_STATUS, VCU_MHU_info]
BO_ 1074 MHU_FOTA_STATUS: 8 XGW_Body
 SG_ MHU_FOTA_Checksum : 7|8@0+ (1,0) [0|255] ""  ACM,APM,ASU_Gateway,BCM,BCM_BPM,CCU_F,CCU_R,ETG,LDM_L,LDM_R,OCS_P,PSM_D,SRR_RR_M,TRM
 SG_ MHU_FOTA_Alive_Counter : 11|4@0+ (1,0) [0|14] ""  ACM,APM,ASU_Gateway,BCM,BCM_BPM,CCU_F,CCU_R,ETG,LDM_L,LDM_R,OCS_P,PSM_D,SRR_RR_M,TRM
 SG_ MHU_FOTA_State : 15|4@0+ (1,0) [0|14] "-"  ACM,APM,ASU_Gateway,BCM,BCM_BPM,CCU_F,CCU_R,ETG,LDM_L,LDM_R,OCS_P,PSM_D,SRR_RR_M,TRM
 SG_ MHU_FOTA_Error_Code : 23|8@0+ (1,0) [0|255] "-"  ACM,APM,ASU_Gateway,BCM,BCM_BPM,CCU_F,CCU_R,ETG,LDM_L,LDM_R,OCS_P,PSM_D,SRR_RR_M,TRM

BO_ 1077 BCM_SCM_LIN_Info: 1 BCM
 SG_ BCM_SCM_BC_Button : 1|2@0+ (1,0) [0|3] "-"  XGW_Body

BO_ 1082 VCU_MHU_info: 8 XGW_Body
 SG_ CRC_VCU_MHU_info : 7|8@0+ (1,0) [0|255] ""  BCM
 SG_ ALIV_VCU_MHU_info : 11|4@0+ (1,0) [0|14] ""  BCM
 SG_ VCU_BrakeRegenMode : 13|2@0+ (1,0) [0|3] "-"  BCM
 SG_ VCU_CreepDisable_stt : 14|1@0+ (1,0) [0|1] ""  BCM
 SG_ VCU_PowerRegenGaugeDisplay : 23|8@0+ (1,-100) [-100|100] "%"  BCM
 SG_ VCU_Charging_Authen_stt : 27|3@0+ (1,0) [0|7] "-"  BCM
 SG_ VCU_ChgGun_BadConn_stt : 28|1@0+ (1,0) [0|1] ""  BCM
 SG_ VCU_ChgPort_Open_stt : 29|1@0+ (1,0) [0|1] ""  BCM
 SG_ VCU_Regen_available : 31|2@0+ (1,0) [0|3] ""  BCM
 SG_ VCU_VehChg_STS : 34|3@0+ (1,0) [0|7] ""  BCM
 SG_ VCU_SOC_display : 46|10@0+ (0.1,0) [0|100] "%"  BCM
 SG_ VCU_ChgGun_Status : 50|3@0+ (1,0) [0|7] ""  BCM
 SG_ VCU_ChgPort_Lock_stt : 57|1@0+ (1,0) [0|1] ""  BCM
 SG_ VCU_Hvbatt_charging_stt : 58|1@0+ (1,0) [0|1] "-"  BCM

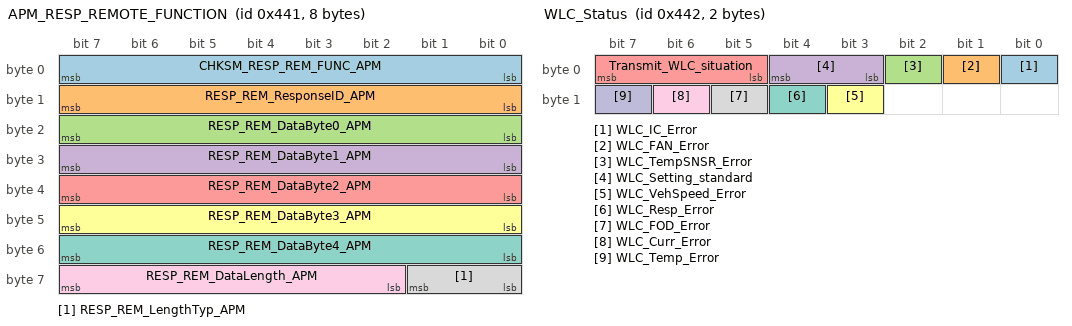
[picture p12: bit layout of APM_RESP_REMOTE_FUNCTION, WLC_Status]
BO_ 1089 APM_RESP_REMOTE_FUNCTION: 8 APM
 SG_ CHKSM_RESP_REM_FUNC_APM : 7|8@0+ (1,0) [0|255] ""  XGW_Body
 SG_ RESP_REM_ResponseID_APM : 15|8@0+ (1,0) [0|254] ""  XGW_Body
 SG_ RESP_REM_DataByte0_APM : 23|8@0+ (1,0) [0|254] ""  XGW_Body
 SG_ RESP_REM_DataByte1_APM : 31|8@0+ (1,0) [0|254] ""  XGW_Body
 SG_ RESP_REM_DataByte2_APM : 39|8@0+ (1,0) [0|254] ""  XGW_Body
 SG_ RESP_REM_DataByte3_APM : 47|8@0+ (1,0) [0|254] ""  XGW_Body
 SG_ RESP_REM_DataByte4_APM : 55|8@0+ (1,0) [0|254] ""  XGW_Body
 SG_ RESP_REM_LengthTyp_APM : 57|2@0+ (1,0) [0|3] ""  XGW_Body
 SG_ RESP_REM_DataLength_APM : 63|6@0+ (1,0) [0|63] ""  XGW_Body

BO_ 1090 WLC_Status: 2 BCM
 SG_ WLC_IC_Error : 0|1@0+ (1,0) [0|1] ""  XGW_Body
 SG_ WLC_FAN_Error : 1|1@0+ (1,0) [0|1] "-"  XGW_Body
 SG_ WLC_TempSNSR_Error : 2|1@0+ (1,0) [0|1] "-"  XGW_Body
 SG_ WLC_Setting_standard : 4|2@0+ (1,0) [0|3] "-"  XGW_Body
 SG_ Transmit_WLC_situation : 7|3@0+ (1,0) [0|7] ""  XGW_Body
 SG_ WLC_VehSpeed_Error : 11|1@0+ (1,0) [0|1] ""  XGW_Body
 SG_ WLC_Resp_Error : 12|1@0+ (1,0) [0|1] ""  XGW_Body
 SG_ WLC_FOD_Error : 13|1@0+ (1,0) [0|1] "-"  XGW_Body
 SG_ WLC_Curr_Error : 14|1@0+ (1,0) [0|1] "-"  XGW_Body
 SG_ WLC_Temp_Error : 15|1@0+ (1,0) [0|1] ""  XGW_Body

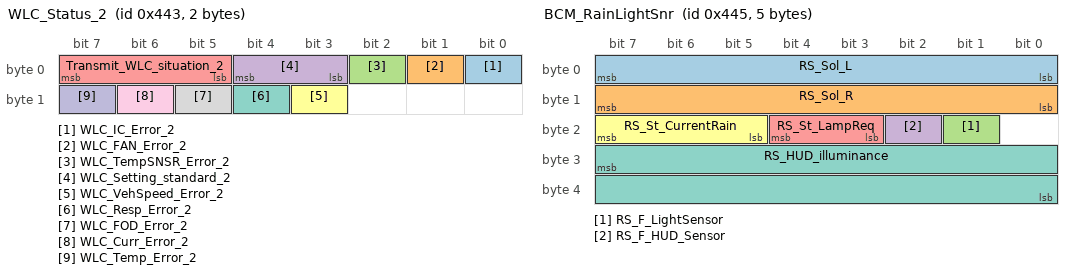
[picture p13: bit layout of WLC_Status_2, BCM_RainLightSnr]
BO_ 1091 WLC_Status_2: 2 BCM
 SG_ WLC_IC_Error_2 : 0|1@0+ (1,0) [0|1] "-"  XGW_Body
 SG_ WLC_FAN_Error_2 : 1|1@0+ (1,0) [0|1] ""  XGW_Body
 SG_ WLC_TempSNSR_Error_2 : 2|1@0+ (1,0) [0|1] "-"  XGW_Body
 SG_ WLC_Setting_standard_2 : 4|2@0+ (1,0) [0|3] ""  XGW_Body
 SG_ Transmit_WLC_situation_2 : 7|3@0+ (1,0) [0|7] ""  XGW_Body
 SG_ WLC_VehSpeed_Error_2 : 11|1@0+ (1,0) [0|1] ""  XGW_Body
 SG_ WLC_Resp_Error_2 : 12|1@0+ (1,0) [0|1] "-"  XGW_Body
 SG_ WLC_FOD_Error_2 : 13|1@0+ (1,0) [0|1] "-"  XGW_Body
 SG_ WLC_Curr_Error_2 : 14|1@0+ (1,0) [0|1] "-"  XGW_Body
 SG_ WLC_Temp_Error_2 : 15|1@0+ (1,0) [0|1] ""  XGW_Body

BO_ 1093 BCM_RainLightSnr: 5 BCM
 SG_ RS_Sol_L : 7|8@0+ (5,0) [0|1000] "W/m^2"  CCU_F,LDM_L,LDM_R,XGW_Body
 SG_ RS_Sol_R : 15|8@0+ (5,0) [0|1000] "W/m^2"  CCU_F,LDM_L,LDM_R,XGW_Body
 SG_ RS_F_LightSensor : 17|1@0+ (1,0) [0|1] ""  XGW_Body
 SG_ RS_F_HUD_Sensor : 18|1@0+ (1,0) [0|1] "cd/m2"  XGW_Body
 SG_ RS_St_LampReq : 20|2@0+ (1,0) [0|3] ""  CCU_F,LDM_L,LDM_R,XGW_Body
 SG_ RS_St_CurrentRain : 23|3@0+ (1,0) [0|7] ""  CCU_F,XGW_Body
 SG_ RS_HUD_illuminance : 31|16@0+ (1,0) [0|10000] "cd/m2"  XGW_Body

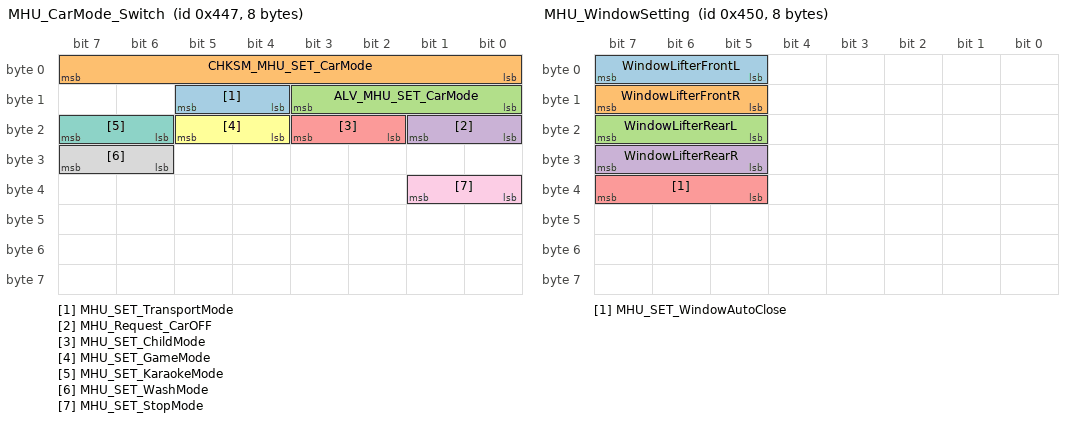
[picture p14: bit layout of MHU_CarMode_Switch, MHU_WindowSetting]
BO_ 1095 MHU_CarMode_Switch: 8 XGW_Body
 SG_ MHU_SET_TransportMode : 13|2@0+ (1,0) [0|3] ""  BCM
 SG_ CHKSM_MHU_SET_CarMode : 7|8@0+ (1,0) [0|255] ""  BCM,USS_F,USS_R
 SG_ ALV_MHU_SET_CarMode : 11|4@0+ (1,0) [0|14] ""  BCM,USS_F,USS_R
 SG_ MHU_Request_CarOFF : 17|2@0+ (1,0) [0|3] "-"  BCM
 SG_ MHU_SET_ChildMode : 19|2@0+ (1,0) [0|3] ""  BCM
 SG_ MHU_SET_GameMode : 21|2@0+ (1,0) [0|3] ""  BCM
 SG_ MHU_SET_KaraokeMode : 23|2@0+ (1,0) [0|3] ""  BCM
 SG_ MHU_SET_WashMode : 31|2@0+ (1,0) [0|3] ""  BCM,USS_F,USS_R
 SG_ MHU_SET_StopMode : 33|2@0+ (1,0) [0|3] ""  BCM

BO_ 1104 MHU_WindowSetting: 8 XGW_Body
 SG_ WindowLifterFrontL : 7|3@0+ (1,0) [0|7] ""  APM
 SG_ WindowLifterFrontR : 15|3@0+ (1,0) [0|7] ""  APM
 SG_ WindowLifterRearL : 23|3@0+ (1,0) [0|7] ""  APM
 SG_ WindowLifterRearR : 31|3@0+ (1,0) [0|7] ""  APM
 SG_ MHU_SET_WindowAutoClose : 39|3@0+ (1,0) [0|3] ""  APM

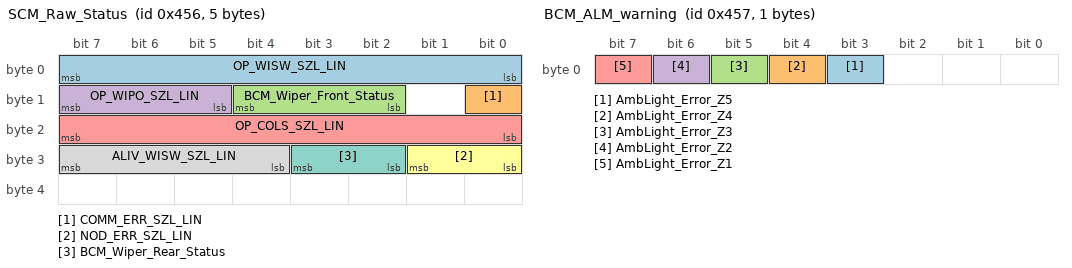
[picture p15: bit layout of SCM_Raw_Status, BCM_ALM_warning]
BO_ 1110 SCM_Raw_Status: 5 BCM
 SG_ OP_WISW_SZL_LIN : 7|8@0+ (1,0) [0|255] ""  XGW_Body
 SG_ COMM_ERR_SZL_LIN : 8|1@0+ (1,0) [0|1] ""  XGW_Body
 SG_ BCM_Wiper_Front_Status : 12|3@0+ (1,0) [0|7] ""  XGW_Body
 SG_ OP_WIPO_SZL_LIN : 15|3@0+ (1,0) [0|7] "-"  XGW_Body
 SG_ OP_COLS_SZL_LIN : 23|8@0+ (1,0) [0|255] "-"  XGW_Body
 SG_ NOD_ERR_SZL_LIN : 25|2@0+ (1,0) [0|3] ""  XGW_Body
 SG_ BCM_Wiper_Rear_Status : 27|2@0+ (1,0) [0|3] ""  XGW_Body
 SG_ ALIV_WISW_SZL_LIN : 31|4@0+ (1,0) [0|14] ""  XGW_Body

BO_ 1111 BCM_ALM_warning: 1 BCM
 SG_ AmbLight_Error_Z5 : 3|1@0+ (1,0) [0|1] "-"  XGW_Body
 SG_ AmbLight_Error_Z4 : 4|1@0+ (1,0) [0|1] ""  XGW_Body
 SG_ AmbLight_Error_Z3 : 5|1@0+ (1,0) [0|1] "-"  XGW_Body
 SG_ AmbLight_Error_Z2 : 6|1@0+ (1,0) [0|1] ""  XGW_Body
 SG_ AmbLight_Error_Z1 : 7|1@0+ (1,0) [0|1] ""  XGW_Body

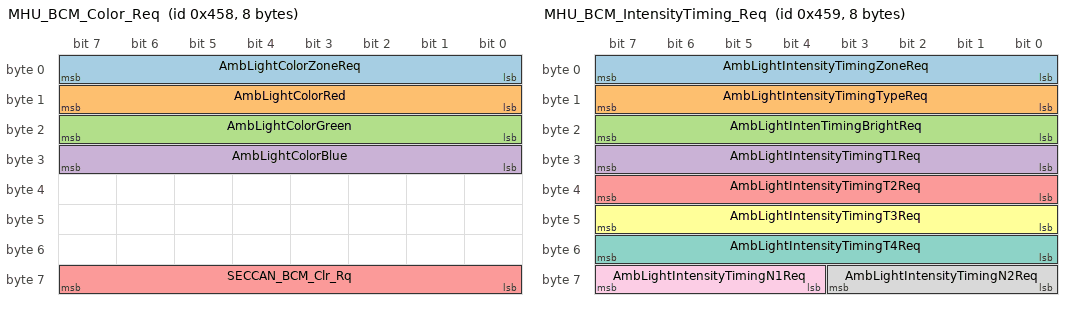
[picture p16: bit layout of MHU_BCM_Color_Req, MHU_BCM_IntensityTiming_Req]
BO_ 1112 MHU_BCM_Color_Req: 8 XGW_Body
 SG_ AmbLightColorZoneReq : 7|8@0+ (1,0) [0|31] "-"  BCM
 SG_ AmbLightColorRed : 15|8@0+ (1,0) [0|255] ""  BCM
 SG_ AmbLightColorGreen : 23|8@0+ (1,0) [0|255] "-"  BCM
 SG_ AmbLightColorBlue : 31|8@0+ (1,0) [0|255] "-"  BCM
 SG_ SECCAN_BCM_Clr_Rq : 63|8@0+ (1,0) [0|255] ""  BCM

BO_ 1113 MHU_BCM_IntensityTiming_Req: 8 XGW_Body
 SG_ AmbLightIntensityTimingZoneReq : 7|8@0+ (1,0) [0|31] ""  BCM
 SG_ AmbLightIntensityTimingTypeReq : 15|8@0+ (1,0) [0|5] ""  BCM
 SG_ AmbLightIntenTimingBrightReq : 23|8@0+ (1,0) [0|100] ""  BCM
 SG_ AmbLightIntensityTimingT1Req : 31|8@0+ (0.1,0) [0|25.5] "s"  BCM
 SG_ AmbLightIntensityTimingT2Req : 39|8@0+ (0.1,0) [0|25.5] "s"  BCM
 SG_ AmbLightIntensityTimingT3Req : 47|8@0+ (0.1,0) [0|25.5] "s"  BCM
 SG_ AmbLightIntensityTimingT4Req : 55|8@0+ (0.1,0) [0|25.5] "s"  BCM
 SG_ AmbLightIntensityTimingN2Req : 59|4@0+ (1,0) [0|15] "-"  BCM
 SG_ AmbLightIntensityTimingN1Req : 63|4@0+ (1,0) [0|15] ""  BCM

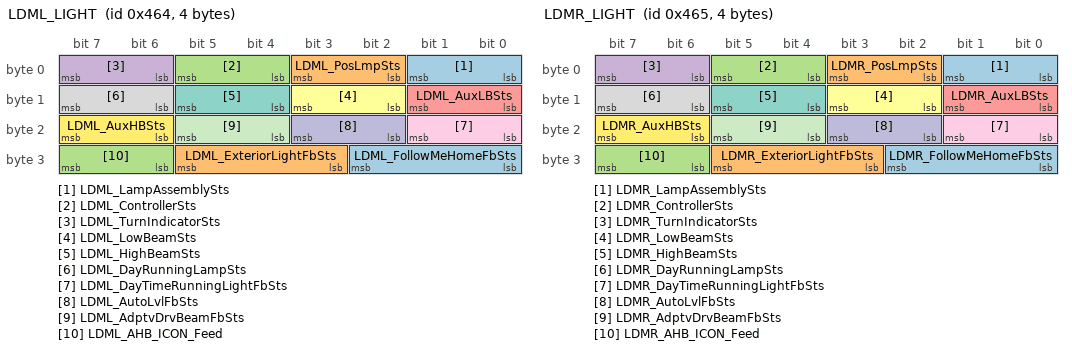
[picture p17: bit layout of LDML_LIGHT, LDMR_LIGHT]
BO_ 1124 LDML_LIGHT: 4 LDM_L
 SG_ LDML_LampAssemblySts : 1|2@0+ (1,0) [0|3] "-"  BCM,XGW_Body
 SG_ LDML_PosLmpSts : 3|2@0+ (1,0) [0|3] ""  BCM,XGW_Body
 SG_ LDML_ControllerSts : 5|2@0+ (1,0) [0|3] ""  BCM,XGW_Body
 SG_ LDML_TurnIndicatorSts : 7|2@0+ (1,0) [0|3] ""  BCM,XGW_Body
 SG_ LDML_AuxLBSts : 9|2@0+ (1,0) [0|3] "-"  BCM,XGW_Body
 SG_ LDML_LowBeamSts : 11|2@0+ (1,0) [0|3] "-"  BCM,XGW_Body
 SG_ LDML_HighBeamSts : 13|2@0+ (1,0) [0|3] ""  BCM,XGW_Body
 SG_ LDML_DayRunningLampSts : 15|2@0+ (1,0) [0|3] ""  BCM,XGW_Body
 SG_ LDML_DayTimeRunningLightFbSts : 17|2@0+ (1,0) [0|3] ""  BCM,XGW_Body
 SG_ LDML_AutoLvlFbSts : 19|2@0+ (1,0) [0|3] ""  BCM,XGW_Body
 SG_ LDML_AdptvDrvBeamFbSts : 21|2@0+ (1,0) [0|3] "-"  BCM,XGW_Body
 SG_ LDML_AuxHBSts : 23|2@0+ (1,0) [0|3] "-"  BCM,XGW_Body
 SG_ LDML_FollowMeHomeFbSts : 26|3@0+ (1,0) [0|5] "-"  BCM,XGW_Body
 SG_ LDML_ExteriorLightFbSts : 29|3@0+ (1,0) [0|4] "-"  BCM,XGW_Body
 SG_ LDML_AHB_ICON_Feed : 31|2@0+ (1,0) [0|3] ""  XGW_Body

BO_ 1125 LDMR_LIGHT: 4 LDM_R
 SG_ LDMR_LampAssemblySts : 1|2@0+ (1,0) [0|3] ""  BCM,XGW_Body
 SG_ LDMR_PosLmpSts : 3|2@0+ (1,0) [0|3] "-"  BCM,XGW_Body
 SG_ LDMR_ControllerSts : 5|2@0+ (1,0) [0|3] ""  BCM,XGW_Body
 SG_ LDMR_TurnIndicatorSts : 7|2@0+ (1,0) [0|3] "-"  BCM,XGW_Body
 SG_ LDMR_AuxLBSts : 9|2@0+ (1,0) [0|3] "-"  BCM,XGW_Body
 SG_ LDMR_LowBeamSts : 11|2@0+ (1,0) [0|3] "-"  BCM,XGW_Body
 SG_ LDMR_HighBeamSts : 13|2@0+ (1,0) [0|3] ""  BCM,XGW_Body
 SG_ LDMR_DayRunningLampSts : 15|2@0+ (1,0) [0|3] ""  BCM,XGW_Body
 SG_ LDMR_DayTimeRunningLightFbSts : 17|2@0+ (1,0) [0|3] "-"  BCM,XGW_Body
 SG_ LDMR_AutoLvlFbSts : 19|2@0+ (1,0) [0|3] "-"  BCM,XGW_Body
 SG_ LDMR_AdptvDrvBeamFbSts : 21|2@0+ (1,0) [0|3] ""  BCM,XGW_Body
 SG_ LDMR_AuxHBSts : 23|2@0+ (1,0) [0|3] "-"  BCM,XGW_Body
 SG_ LDMR_FollowMeHomeFbSts : 26|3@0+ (1,0) [0|5] ""  BCM,XGW_Body
 SG_ LDMR_ExteriorLightFbSts : 29|3@0+ (1,0) [0|4] "-"  BCM,XGW_Body
 SG_ LDMR_AHB_ICON_Feed : 31|2@0+ (1,0) [0|3] ""  XGW_Body

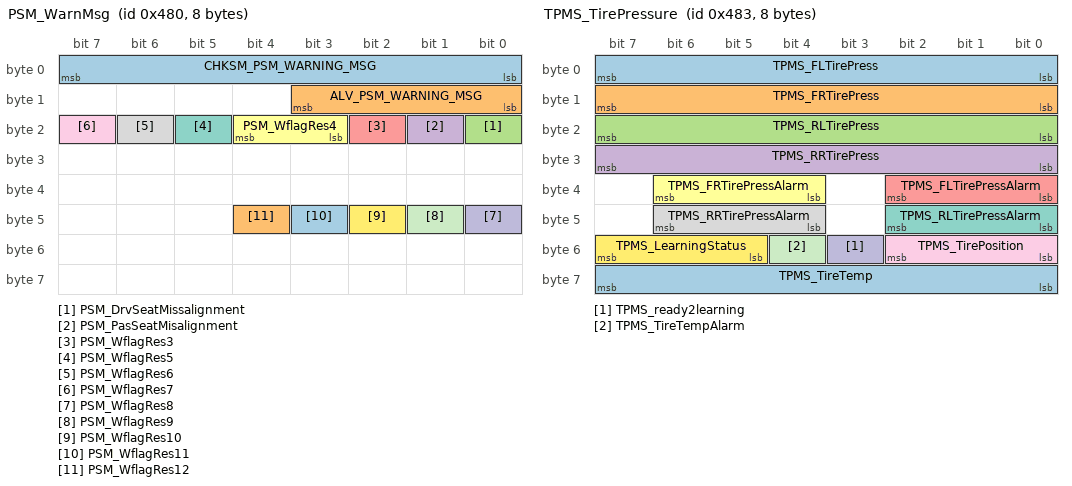
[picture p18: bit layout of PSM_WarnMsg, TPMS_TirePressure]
BO_ 1152 PSM_WarnMsg: 8 PSM_D
 SG_ CHKSM_PSM_WARNING_MSG : 7|8@0+ (1,0) [0|255] ""  XGW_Body
 SG_ ALV_PSM_WARNING_MSG : 11|4@0+ (1,0) [0|14] ""  XGW_Body
 SG_ PSM_DrvSeatMissalignment : 16|1@0+ (1,0) [0|1] ""  XGW_Body
 SG_ PSM_PasSeatMisalignment : 17|1@0+ (1,0) [0|1] "Bit"  XGW_Body
 SG_ PSM_WflagRes3 : 18|1@0+ (1,0) [0|1] "Bit"  XGW_Body
 SG_ PSM_WflagRes4 : 20|2@0+ (1,0) [0|3] "Bit"  XGW_Body
 SG_ PSM_WflagRes5 : 21|1@0+ (1,0) [0|1] "-"  XGW_Body
 SG_ PSM_WflagRes6 : 22|1@0+ (1,0) [0|1] "-"  XGW_Body
 SG_ PSM_WflagRes7 : 23|1@0+ (1,0) [0|1] "-"  XGW_Body
 SG_ PSM_WflagRes8 : 40|1@0+ (1,0) [0|1] ""  XGW_Body
 SG_ PSM_WflagRes9 : 41|1@0+ (1,0) [0|1] ""  XGW_Body
 SG_ PSM_WflagRes10 : 42|1@0+ (1,0) [0|1] "-"  XGW_Body
 SG_ PSM_WflagRes11 : 43|1@0+ (1,0) [0|1] "-"  XGW_Body
 SG_ PSM_WflagRes12 : 44|1@0+ (1,0) [0|1] "-"  XGW_Body

BO_ 1153 BCM_WarnMsg: 8 BCM
 SG_ CHSKM_BCM_WarnMsg : 7|8@0+ (1,0) [0|255] ""  XGW_Body
 SG_ ALV_BCM_WarnMsg : 11|4@0+ (1,0) [0|14] ""  XGW_Body
 SG_ BCM_NoValidKey_1 : 12|1@0+ (1,0) [0|1] ""  XGW_Body
 SG_ BCM_SSB_defect : 13|1@0+ (1,0) [0|1] ""  XGW_Body
 SG_ BCM_WrongGearPosToStart : 14|1@0+ (1,0) [0|1] ""  XGW_Body
 SG_ BCM_NoValidKey_2 : 15|1@0+ (1,0) [0|1] ""  XGW_Body
 SG_ BCM_PressBrakeToStart : 16|1@0+ (1,0) [0|1] ""  XGW_Body
 SG_ BCM_TurnOffPosLightRemindr : 17|1@0+ (1,0) [0|1] ""  XGW_Body
 SG_ BCM_KeyFob_LowBattery : 18|1@0+ (1,0) [0|1] ""  XGW_Body
 SG_ BCM_StopLightDefect : 19|1@0+ (1,0) [0|1] ""  XGW_Body
 SG_ BCM_LowBeamDefect : 20|1@0+ (1,0) [0|1] ""  XGW_Body
 SG_ BCM_HighBeamDefect : 21|1@0+ (1,0) [0|1] ""  XGW_Body
 SG_ BCM_PositionLightDefect : 22|1@0+ (1,0) [0|1] ""  XGW_Body
 SG_ BCM_CHMLS_Defect : 23|1@0+ (1,0) [0|1] ""  XGW_Body
 SG_ BCM_LicencePlateLight_Defect : 24|1@0+ (1,0) [0|1] ""  XGW_Body
 SG_ BCM_FrontFog_Defect : 25|1@0+ (1,0) [0|1] ""  XGW_Body
 SG_ BCM_RearFog_Defect : 26|1@0+ (1,0) [0|1] ""  XGW_Body
 SG_ BCM_ReverseLightDefect : 27|1@0+ (1,0) [0|1] ""  XGW_Body
 SG_ BCM_RLS_Malfunction : 28|1@0+ (1,0) [0|1] ""  XGW_Body
 SG_ BCM_12VBattery_LowLevel : 29|1@0+ (1,0) [0|1] ""  XGW_Body
 SG_ BCM_ForgetKeyFOBInCar : 30|1@0+ (1,0) [0|1] ""  XGW_Body
 SG_ BCM_12VBattery_Discharging : 31|1@0+ (1,0) [0|1] ""  XGW_Body
 SG_ BCM_TurnIndicatorDefect : 32|1@0+ (1,0) [0|1] ""  XGW_Body
 SG_ BCM_dTPMS_Malfunc : 33|1@0+ (1,0) [0|1] ""  XGW_Body
 SG_ BCM_dTPMS_Malfunc_LostSensor : 34|1@0+ (1,0) [0|1] ""  XGW_Body
 SG_ BCM_dTPMS_LowPressure : 35|1@0+ (1,0) [0|1] ""  XGW_Body
 SG_ BCM_dTPMS_RapidLeak : 36|1@0+ (1,0) [0|1] ""  XGW_Body
 SG_ BCM_dTPMS_HighTemperature : 37|1@0+ (1,0) [0|1] ""  XGW_Body
 SG_ BCM_dTPMS_HighPressure : 38|1@0+ (1,0) [0|1] ""  XGW_Body
 SG_ BCM_dTPMS_LowBattery : 39|1@0+ (1,0) [0|1] ""  XGW_Body
 SG_ BCM_Keyfob_Leftcar : 40|1@0+ (1,0) [0|1] ""  XGW_Body
 SG_ BCM_IDB_Brakelight_Malfunction : 41|1@0+ (1,0) [0|1] ""  XGW_Body
 SG_ BCM_VCU_Brakelight_Malfunction : 42|1@0+ (1,0) [0|1] ""  XGW_Body
 SG_ BCM_ADAS_Turnlight_Malfunction : 43|1@0+ (1,0) [0|1] ""  XGW_Body
 SG_ BCM_ADAS_Highbeam_Malfunction : 44|1@0+ (1,0) [0|1] ""  XGW_Body
 SG_ BCM_ADAS_LowBeam_Malfunction : 45|1@0+ (1,0) [0|1] ""  XGW_Body
 SG_ BCM_MHU_Malfunction : 46|1@0+ (1,0) [0|1] ""  XGW_Body
 SG_ BCM_BCM_Malfunction : 47|1@0+ (1,0) [0|1] ""  XGW_Body
 SG_ BCM_SCM_Malfunction : 48|1@0+ (1,0) [0|1] ""  XGW_Body
 SG_ BCM_CrashSignalDefect : 49|1@0+ (1,0) [0|1] ""  XGW_Body
 SG_ BCM_FrontWiperDefect : 51|1@0+ (1,0) [0|1] ""  XGW_Body
 SG_ BCM_Rear_RightDoorLockDefect : 52|1@0+ (1,0) [0|1] ""  XGW_Body
 SG_ BCM_RearLeftDoorLockDefect : 53|1@0+ (1,0) [0|1] ""  XGW_Body
 SG_ BCM_Front_RightDoorLockDefect : 54|1@0+ (1,0) [0|1] ""  XGW_Body
 SG_ BCM_FrontLeftDoorLockDefect : 55|1@0+ (1,0) [0|1] ""  XGW_Body
 SG_ BCM_LDML_Malfunction : 56|1@0+ (1,0) [0|1] ""  XGW_Body
 SG_ BCM_LDMR_Malfunction : 57|1@0+ (1,0) [0|1] ""  XGW_Body
 SG_ BCM_RLBL_Malfunction : 58|1@0+ (1,0) [0|1] ""  XGW_Body
 SG_ BCM_RLBR_Malfunction : 59|1@0+ (1,0) [0|1] ""  XGW_Body
 SG_ BCM_RLT_Malfunction : 60|1@0+ (1,0) [0|1] ""  XGW_Body
 SG_ BCM_BCM_POWER_Malfunction : 61|1@0+ (1,0) [0|1] ""  XGW_Body
 SG_ BCM_IDB_AutoHazardBlinking_Malf : 62|1@0+ (1,0) [0|1] ""  XGW_Body

BO_ 1155 TPMS_TirePressure: 8 BCM
 SG_ TPMS_FLTirePress : 7|8@0+ (1.373,0) [0|350] "kPa"  XGW_Body
 SG_ TPMS_FRTirePress : 15|8@0+ (1.373,0) [0|350] "kPa"  XGW_Body
 SG_ TPMS_RLTirePress : 23|8@0+ (1.373,0) [0|350] "kPa"  XGW_Body
 SG_ TPMS_RRTirePress : 31|8@0+ (1.373,0) [0|350] "kPa"  XGW_Body
 SG_ TPMS_FLTirePressAlarm : 34|3@0+ (1,0) [0|7] ""  XGW_Body,ACM
 SG_ TPMS_FRTirePressAlarm : 38|3@0+ (1,0) [0|7] "-"  XGW_Body,ACM
 SG_ TPMS_RLTirePressAlarm : 42|3@0+ (1,0) [0|7] ""  XGW_Body,ACM
 SG_ TPMS_RRTirePressAlarm : 46|3@0+ (1,0) [0|7] ""  XGW_Body,ACM
 SG_ TPMS_TirePosition : 50|3@0+ (1,0) [0|7] "-"  XGW_Body
 SG_ TPMS_ready2learning : 51|1@0+ (1,0) [0|1] "-"  XGW_Body
 SG_ TPMS_TireTempAlarm : 52|1@0+ (1,0) [0|1] "-"  XGW_Body
 SG_ TPMS_LearningStatus : 55|3@0+ (1,0) [0|7] "-"  XGW_Body
 SG_ TPMS_TireTemp : 63|8@0+ (1,-40) [-40|215] "Degree C"  XGW_Body

BO_ 1156 APA_FEEDBACK_MHU: 8 XGW_Body
 SG_ CHKSM_APA_FEEDBACK_MHU : 7|8@0+ (1,0) [0|255] "" ACM
 SG_ ALV_APA_FEEDBACK_MHU : 11|4@0+ (1,0) [0|14] "" ACM
 SG_ APA_MHU_Status : 59|3@0+ (1,0) [0|7] "-" ACM

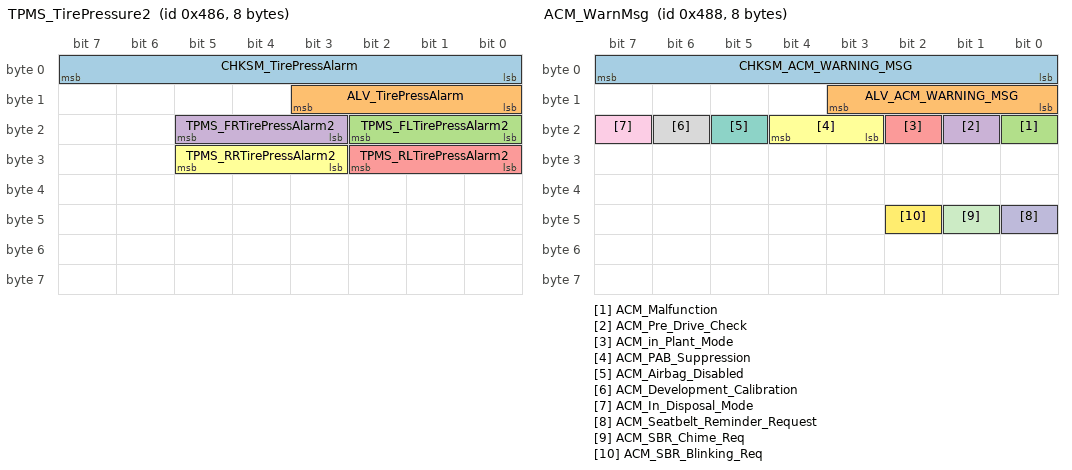
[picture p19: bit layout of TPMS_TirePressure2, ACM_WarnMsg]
BO_ 1158 TPMS_TirePressure2: 8 BCM
 SG_ CHKSM_TirePressAlarm : 7|8@0+ (1,0) [0|255] "" XGW_Body
 SG_ ALV_TirePressAlarm : 11|4@0+ (1,0) [0|14] "" XGW_Body
 SG_ TPMS_FLTirePressAlarm2 : 18|3@0+ (1,0) [0|7] "" XGW_Body
 SG_ TPMS_FRTirePressAlarm2 : 21|3@0+ (1,0) [0|7] "" XGW_Body
 SG_ TPMS_RLTirePressAlarm2 : 26|3@0+ (1,0) [0|7] "" XGW_Body
 SG_ TPMS_RRTirePressAlarm2 : 29|3@0+ (1,0) [0|7] "" XGW_Body

BO_ 1160 ACM_WarnMsg: 8 ACM
 SG_ CHKSM_ACM_WARNING_MSG : 7|8@0+ (1,0) [0|255] ""  XGW_Body
 SG_ ALV_ACM_WARNING_MSG : 11|4@0+ (1,0) [0|14] ""  XGW_Body
 SG_ ACM_Malfunction : 16|1@0+ (1,0) [0|1] ""  XGW_Body
 SG_ ACM_Pre_Drive_Check : 17|1@0+ (1,0) [0|1] "Bit"  XGW_Body
 SG_ ACM_in_Plant_Mode : 18|1@0+ (1,0) [0|1] "Bit"  XGW_Body
 SG_ ACM_PAB_Suppression : 20|2@0+ (1,0) [0|3] "Bit"  XGW_Body
 SG_ ACM_Airbag_Disabled : 21|1@0+ (1,0) [0|1] "-"  XGW_Body
 SG_ ACM_Development_Calibration : 22|1@0+ (1,0) [0|1] "-"  XGW_Body
 SG_ ACM_In_Disposal_Mode : 23|1@0+ (1,0) [0|1] ""  XGW_Body
 SG_ ACM_Seatbelt_Reminder_Request : 40|1@0+ (1,0) [0|1] "-"  XGW_Body
 SG_ ACM_SBR_Chime_Req : 41|1@0+ (1,0) [0|1] ""  XGW_Body
 SG_ ACM_SBR_Blinking_Req : 42|1@0+ (1,0) [0|1] ""  XGW_Body

CM_ BO_ 896 "BCM vehicle identifier number";
CM_ SG_ 896 VIN_Byte1 "This signal contains the seventh last digit of the chassis number. (The individual digits are encoded in ASCII characters.)
Bit 0: LSB, Bit 7: MSB";
CM_ SG_ 896 VIN_Byte2 "This signal contains the sixth last digit of the chassis number. (The individual digits are encoded in ASCII characters.)
Bit 0: LSB, Bit 7: MSB";
CM_ SG_ 896 VIN_Byte3 "This signal contains the fifth last digit of the chassis number. (The individual digits are encoded in ASCII characters.)
Bit 0: LSB, Bit 7: MSB";
CM_ SG_ 896 VIN_Byte4 "This signal contains the fourth last digit of the chassis number. (The individual digits are encoded in ASCII characters.)
Bit 0: LSB, Bit 7: MSB";
CM_ SG_ 896 VIN_Byte5 "This signal contains the third last digit of the chassis number. (The individual digits are encoded in ASCII characters.)
Bit 0: LSB, Bit 7: MSB";
CM_ SG_ 896 VIN_Byte6 "This signal contains the penultimate digit of the chassis number. (The individual digits are encoded in ASCII characters.)
Bit 0: LSB, Bit 7: MSB";
CM_ SG_ 896 VIN_Byte7 "This signal contains the last digit of the chassis number. (The individual digits are encoded in ASCII characters.)
Bit 0: LSB, Bit 7: MSB";
CM_ BO_ 897 "ACM seatbelt and buckle status for seatbelt reminder";
CM_ SG_ 897 CHKSM_ACM_SEAT_OCCUPATION "Checksum";
CM_ SG_ 897 ALV_ACM_SEAT_OCCUPATION "Alive Counter";
CM_ SG_ 897 ACM_Seat_Occupancy_Passenger "Signal to indicate status of occupancy";
CM_ SG_ 897 ACM_Seat_Occupancy_2nd_Row_Dri "Signal to indicate status of occupancy";
CM_ SG_ 897 ACM_Seat_Occupancy_2nd_Row_Pas "Signal to indicate status of occupancy";
CM_ SG_ 897 ACM_Seat_Occupancy_2nd_Row_Mid "Signal to indicate status of occupancy";
CM_ SG_ 897 ACM_Seat_Belt_Status_Passenger "Seatbelt status for seatbelt reminder function";
CM_ SG_ 897 ACM_Seat_Belt_Status_Driver "Seatbelt status for seatbelt reminder function";
CM_ SG_ 897 ACM_Seat_Belt_Status_2nd_Row_Dri "Seatbelt status for seatbelt reminder function";
CM_ SG_ 897 ACM_Seat_Belt_Status_2nd_Row_Mid "Seatbelt status for seatbelt reminder function";
CM_ SG_ 897 ACM_Seat_Belt_Status_2nd_Row_Pas "Seatbelt status for seatbelt reminder function";
CM_ BO_ 905 "VCU_status";
CM_ SG_ 905 VCU_IMMO_Sts "IMMO status";
CM_ SG_ 905 SECCAN_VCU_IMMO_Sts "Seed generated from Secure CAN algorithm
";
CM_ BO_ 920 "BCM Authentication message";
CM_ SG_ 920 BCM_Immo_Byte_0 "BCM Authentication signal byte 0";
CM_ SG_ 920 BCM_Immo_Byte_1 "BCM Authentication signal byte 1";
CM_ SG_ 920 BCM_Immo_Byte_2 "BCM Authentication signal byte 2";
CM_ SG_ 920 BCM_Immo_Byte_3 "BCM Authentication signal byte 3";
CM_ SG_ 920 BCM_Immo_Byte_4 "BCM Authentication signal byte 4";
CM_ SG_ 920 BCM_Immo_Byte_5 "BCM Authentication signal byte 5";
CM_ SG_ 920 BCM_Immo_Byte_6 "BCM Authentication signal byte 6";
CM_ SG_ 920 BCM_Immo_Byte_7 "BCM Authentication signal byte 7";
CM_ BO_ 921 "VCU Authentication message";
CM_ SG_ 921 VCU_Immo_Byte_0 "VCU Authentication signal byte 0";
CM_ SG_ 921 VCU_Immo_Byte_1 "VCU Authentication signal byte 1";
CM_ SG_ 921 VCU_Immo_Byte_2 "VCU Authentication signal byte 2";
CM_ SG_ 921 VCU_Immo_Byte_3 "VCU Authentication signal byte 3";
CM_ SG_ 921 VCU_Immo_Byte_4 "VCU Authentication signal byte 4";
CM_ SG_ 921 VCU_Immo_Byte_5 "VCU Authentication signal byte 5";
CM_ SG_ 921 VCU_Immo_Byte_6 "VCU Authentication signal byte 6";
CM_ SG_ 921 VCU_Immo_Byte_7 "VCU Authentication signal byte 7";
CM_ BO_ 922 "MHU_Authentication information";
CM_ SG_ 922 MHU_Immo_Byte_0 "MHU Authentication signal byte 0";
CM_ SG_ 922 MHU_Immo_Byte_1 "MHU Authentication signal byte 1";
CM_ SG_ 922 MHU_Immo_Byte_2 "MHU Authentication signal byte 2";
CM_ SG_ 922 MHU_Immo_Byte_3 "MHU Authentication signal byte 3";
CM_ SG_ 922 MHU_Immo_Byte_4 "MHU Authentication signal byte 4";
CM_ SG_ 922 MHU_Immo_Byte_5 "MHU Authentication signal byte 5";
CM_ SG_ 922 MHU_Immo_Byte_6 "MHU Authentication signal byte 6";
CM_ SG_ 922 MHU_Immo_Byte_7 "MHU Authentication signal byte 7";
CM_ BO_ 923 "GW_BCM_Immo_MHU_Byte";
CM_ SG_ 923 BCM_Immo_MHU_Byte_0 "BCM Authentication signal byte 0 with MHU";
CM_ SG_ 923 BCM_Immo_MHU_Byte_1 "BCM Authentication signal byte 1 with MHU";
CM_ SG_ 923 BCM_Immo_MHU_Byte_2 "BCM Authentication signal byte 2 with MHU";
CM_ SG_ 923 BCM_Immo_MHU_Byte_3 "BCM Authentication signal byte 3 with MHU";
CM_ SG_ 923 BCM_Immo_MHU_Byte_4 "BCM Authentication signal byte 4 with MHU";
CM_ SG_ 923 BCM_Immo_MHU_Byte_5 "BCM Authentication signal byte 5 with MHU";
CM_ SG_ 923 BCM_Immo_MHU_Byte_6 "BCM Authentication signal byte 6 with MHU";
CM_ SG_ 923 BCM_Immo_MHU_Byte_7 "BCM Authentication signal byte 7 with MHU";
CM_ BO_ 925 "BCM hight beam position request";
CM_ SG_ 925 CHKSM_BCM_HighBeam_PosReq "Checksum";
CM_ SG_ 925 ALIVE_BCM_HighBeam_PosReq "Alive counter";
CM_ SG_ 925 BCM_ADAS_AHB_state "AHB state";
CM_ SG_ 925 BCM_AHB_Override "Automatic High Beam Override by Driver using Stalk lever";
CM_ SG_ 925 BCM_ADAS_AHB_RBPos_feed "High Beam Position Request Signal(Right Ramp)";
CM_ SG_ 925 BCM_ADAS_AHB_LBPos_feed "High Beam Position Request Signal(Left Ramp)";
CM_ SG_ 925 BCM_AHB_ICON_Feed "AHB ICON Feedback";
CM_ BO_ 993 "VCU_HMI_Info.";
CM_ SG_ 993 CRC_VCU_HMI_Info "Checksum";
CM_ SG_ 993 ALIV_VCU_HMI_Info "Alive counter";
CM_ SG_ 993 VCU_CruiseCtrlSts "Cruise state";
CM_ BO_ 1015 "MFS Control Button";
CM_ SG_ 1015 CHSKM_MFS_Control_Button "Checksum";
CM_ SG_ 1015 ALV_MFS_Control_Button "Alive Counter";
CM_ SG_ 1015 MFS_VoiceRecognitionOn_Off "VoiceRecognition control";
CM_ SG_ 1015 MFS_ISAControl "ISA Control";
CM_ SG_ 1015 MFS_CruiseSpeedIncrease "Cruise Speed Increase";
CM_ SG_ 1015 MFS_TelephoneCall_EndCall "Telephone Call functionality control  ";
CM_ SG_ 1015 MFS_LKAControl "Line Keep Assistance/Line Departure warning Control";
CM_ SG_ 1015 MFS_CruiseGapIncrease "Cruise Gap Increase";
CM_ SG_ 1015 MFS_CruiseOn_Off "Cruise control On/Off";
CM_ SG_ 1015 MFS_CruiseGapDecrease "Cruise Gap Decrease";
CM_ SG_ 1015 MFS_CAN_RESControl "From standy, M1 and M2 to be cancelled
From being cancelled, M1 or M2 to be resume to it previous state
";
CM_ SG_ 1015 MFS_CruiseSpeedDecrease "Cruise Speed Decrease";
CM_ SG_ 1015 MFS_M2Control "Auto Steering and Speed Activation";
CM_ SG_ 1015 MFS_SourseControl "Resourse Control";
CM_ SG_ 1015 MFS_UpControl "Up Control";
CM_ SG_ 1015 MFS_DownControl "Down Control";
CM_ SG_ 1015 MFS_LeftControl "Left Control";
CM_ SG_ 1015 MFS_Failure "Multi-Funtion Switch Failure";
CM_ SG_ 1015 MFS_RightControl "Right Control";
CM_ SG_ 1015 MFS_OK_Control "OK Control";
CM_ BO_ 1025 "MHU Door Setting";
CM_ SG_ 1025 MHU_SET_SunroofGlassLevel "Adjust opening level of sunroof glass";
CM_ SG_ 1025 MHU_SET_BonnetState "Open Bonet latch";
CM_ SG_ 1025 MHU_SET_TrunkState "Open and close trunk tailgate";
CM_ SG_ 1025 MHU_SET_SunroofShaderLevel "Adjust opening level of sunroof shader";
CM_ SG_ 1025 MHU_SET_DoorSpeedLock "Setting Door speed lock mode";
CM_ SG_ 1025 MHU_SET_WelcomeTriggerCondition "Setting Welcome trigger condition";
CM_ SG_ 1025 MHU_SET_AutoSunroof "Setting Auto sunroof mode ON OFF follow Rain sensor";
CM_ SG_ 1025 MHU_SET_RemoteDoorUnlock "Setting which door will be unlocked when car unlock";
CM_ SG_ 1025 MHU_SET_RemoteLockFeedback "Setting remote car lock feedback mechanism";
CM_ SG_ 1025 MHU_SET_FootkickSensor "On Off Footkick sensor to open Trunk latch";
CM_ SG_ 1025 MHU_SET_AutoUnlockDoor "Setting auto unlock door mode Park Engine off Manual";
CM_ SG_ 1025 MHU_SET_RemoteUnlockFeedback "Setting remote car unlock feedback mechanism";
CM_ SG_ 1025 MHU_SET_Childlock "Softbutton for ON/OFF of childlock";
CM_ SG_ 1025 MHU_SET_SunroofInitialize "Initialise command to sunroof to manual open close when face antipinch";
CM_ SG_ 1025 WalkawayDoorLock "MHU set walk away door lock On/Off";
CM_ BO_ 1026 "MHU Light Setting";
CM_ SG_ 1026 MHU_SET_DayTimeRunningLight "On Off Day Time Running Light";
CM_ SG_ 1026 MHU_SET_RearFogLight "On/Off Rear Fog Light";
CM_ SG_ 1026 MHU_SET_FrontFogLight "On/Off Front Fog Light";
CM_ SG_ 1026 MHU_SET_WelcomeDimmingHeadlight "On/Off Welcome headlight dimming";
CM_ SG_ 1026 MHU_SET_AmbientLightBrighness "Change Ambient light brighness percent";
CM_ SG_ 1026 MHU_SET_FootwellLightMode "Change Footwell Light mode";
CM_ SG_ 1026 MHU_SET_ExteriorLight "Change Exterior light mode";
CM_ SG_ 1026 MHU_SET_TRWarningSignals "Turn on/off BCM Thermal runaway warning signals";
CM_ SG_ 1026 MHU_SET_FrontDomeLamp "Setting On/Off/Auto Front Dome Lamp";
CM_ SG_ 1026 MHU_SET_SwitchLightBrightness "Change Brighness level of Switch illumination";
CM_ SG_ 1026 MHU_SET_HazardLight "On/Off HazardLight function";
CM_ SG_ 1026 MHU_SET_FollowMeHome "Change follow me home headlamp mode and delay";
CM_ SG_ 1026 MHU_SET_ADB_AHB "On/off ADB/AHB function, ADB in ECE version, AHB in SAE version
";
CM_ SG_ 1026 MHU_SET_WelcomeAnimation "selection of different welcome/goodbye animations";
CM_ SG_ 1026 MHU_SET_ChargingAnimation "De-/Activation of charging animation";
CM_ SG_ 1026 MHU_SET_Auto_Leveling "On/Off Auto-Leveling function";
CM_ BO_ 1027 "MHU Driving Mode Setting";
CM_ SG_ 1027 CHKSM_MHU_EVSetting "Checksum for EV setting";
CM_ SG_ 1027 ALV_MHU_EVSetting "Alive Counter for EV Setting";
CM_ SG_ 1027 MHU_VCU_CreepDisable_stt "Request for VCU to disable creep function";
CM_ SG_ 1027 MHU_BrakeRegenMode "Brake Regen Style";
CM_ SG_ 1027 MHU_ChargeSetTargetSOC "Request for VCU to set target HV SOC";
CM_ SG_ 1027 MHU_ChargeScheduleSet "Request for VCU to enable/disable Charging Scheduling";
CM_ SG_ 1027 MHU_ChargingRequest "Request for VCU to ON/OFF Charging when schedule is reached";
CM_ SG_ 1027 MHU_ChgPort_Open_req "Request to open charging port(release latch)";
CM_ SG_ 1027 MHU_SET_DrivingModeSwitch "Change vehicle driving mode";
CM_ SG_ 1027 MHU_ValetMode_Activation "Activate Valet mode from MHU";
CM_ SG_ 1027 MHU_ValetMode_MaxSpeed "Setting of maximum allowable in valet mode";
CM_ SG_ 1027 MHU_ChargingCurrentLimit "Request VCU the max charging current at the rush hour - Apply for AC charging only at home";
CM_ BO_ 1028 "MHU Mirror Adjust";
CM_ SG_ 1028 MHU_SET_LeftMirrorPosX "Set left mirror left right position";
CM_ SG_ 1028 MHU_SET_LeftMirrorPosY "Set left mirror up down position";
CM_ SG_ 1028 MHU_SET_RightMirrorPosX "Set right mirror left/right position";
CM_ SG_ 1028 MHU_SET_RightMirrorPosY "Set right mirror up/down position";
CM_ SG_ 1028 MHU_SET_MirrorAdjustLeft "Enter setting Mirror position mode";
CM_ SG_ 1028 MHU_SET_MirrorAdjustRight "Enter setting Mirror position mode";
CM_ SG_ 1028 MHU_SET_MirrorManual "Manual Fold/Unfold";
CM_ SG_ 1028 SECCAN_MirrorAdj "Seed generated from Secure CAN algorithm";
CM_ BO_ 1029 "MHU Climate Setting";
CM_ SG_ 1029 MHU_SET_CCUF_AirCondition "On Off Air Condition";
CM_ SG_ 1029 MHU_SET_CCUF_AutoAC "On Off Auto Air Condition";
CM_ SG_ 1029 MHU_SET_CCUF_MaxAc "On Off Max Air Condition for 2 zone";
CM_ SG_ 1029 MHU_SET_CCUF_FanSpeed "Adjust Fan speed with 6 level";
CM_ SG_ 1029 MHU_SET_CCUF_Recirculation "Change recirculation mode inside, ouside, auto";
CM_ SG_ 1029 MHU_SET_CCUF_Ion "On Off Air ionizer";
CM_ SG_ 1029 MHU_SET_CCUF_FlapPosition "Change Flap position Face, Feet, Front defrost";
CM_ SG_ 1029 MHU_SET_CCUF_SyncClimateZone "On Off sync temperature between zone";
CM_ SG_ 1029 MHU_SET_CCUF_TempDriver "Change Driver zone temperature";
CM_ SG_ 1029 MHU_SET_CCUF_TempPassenger "Change Passenger zone temperature";
CM_ SG_ 1029 MHU_SET_CCUF_FrontDefrost "Change Flap poition to Front Defrost";
CM_ BO_ 1030 "MHU Seat Vent Heat";
CM_ SG_ 1030 MHU_SET_SeatHeatingFrontL "Change seat heating with 3 level";
CM_ SG_ 1030 MHU_SET_SeatHeatingFrontR "Change seat heating with 3 level";
CM_ SG_ 1030 MHU_SET_SeatHeatingReartL "Change seat heating with 3 level";
CM_ SG_ 1030 MHU_SET_SeatHeatingRearR "Change seat heating with 3 level";
CM_ SG_ 1030 MHU_SET_SeatCoolingFrontL "Change seat cooling with 3 level";
CM_ SG_ 1030 MHU_SET_SeatCoolingFrontR "Change seat cooling with 3 level";
CM_ SG_ 1030 MHU_SET_SeatCoolingRearL "Change seat cooling with 3 level";
CM_ SG_ 1030 MHU_SET_SeatCoolingRearR "Change seat cooling with 3 level";
CM_ BO_ 1032 "MHU Comfort Setting";
CM_ SG_ 1032 MHU_SET_MirrorAuto "Change mirror auto mode";
CM_ SG_ 1032 MHU_SET_MirrorAutoUnfold "setting Mirror Auto unfold mode";
CM_ SG_ 1032 MHU_SET_WLC "On Off wireless charger";
CM_ SG_ 1032 MHU_SET_AutoRearWiper "On Off Auto rear wiper";
CM_ SG_ 1032 MHU_SET_RearHeatedWindow "On Off Rear window heating";
CM_ SG_ 1032 MHU_TPMSReset "Request reset the TPMS";
CM_ SG_ 1032 MHU_SET_MirrorDefaultSetting "Trigger the default Mirror setting";
CM_ SG_ 1032 MHU_SET_MirrorReverseLink "Mirror Auto Tilt On Reverse Mode";
CM_ SG_ 1032 MHU_SET_AntiTheftMode "setting Anti-theft mode ";
CM_ SG_ 1032 MHU_SET_WLCReminder "On Off WLC reminder";
CM_ SG_ 1032 MHU_SET_ClimateKeepOn "Keep power for climate PET/CAMP mode";
CM_ SG_ 1032 MHU_SET_WLC2 "On Off wireless charger rear";
CM_ SG_ 1032 MHU_SET_WLC2Reminder "On Off WLC rear reminder";
CM_ SG_ 1032 MHU_IntrusionAlertStatus "Detection of Intrusion Alert in the MHU";
CM_ BO_ 1036 "MHU_SEAT_CONTROL";
CM_ SG_ 1036 CHSKM_MHU_SEAT_CONTROL "Checksum";
CM_ SG_ 1036 ALV_MHU_SEAT_CONTROL "Alive Counter";
CM_ SG_ 1036 MHU_DrvSeat_Control_Status "MHU driver seat control status";
CM_ SG_ 1036 MHU_ExpDrvReclinerPos "Expected recliner position of driver seat requested by MHU";
CM_ SG_ 1036 MHU_ExpDrvTiltPos "Expected tilt position of driver seat requested by MHU";
CM_ SG_ 1036 MHU_ExpDrvTrackPos "Expected track position of driver seat requested by MHU";
CM_ SG_ 1036 MHU_ExpDrvHeightPos "Expected height position of driver seat requested by MHU";
CM_ BO_ 1037 "Display Vehicle speed CAN Signal sent by MHU";
CM_ SG_ 1037 CHKSM_MHU_DIGIT_SPEED "Checksum";
CM_ SG_ 1037 ALV_MHU_DIGIT_SPEED "Alive Counter";
CM_ SG_ 1037 MHU_DigitSpeed "This signal represents the digital speed and is displayed; values between 301 and 511 are invalid.";
CM_ SG_ 1042 eCall_state "eCall Status.";
CM_ BO_ 1044 "HOD_status";
CM_ SG_ 1044 CRC_SW_1 "This signal includes a CRC checksum value which has for purpose of securing the communication path end to end (E2E).";
CM_ SG_ 1044 Message_Counter_SW_1 "This signal includes a counter value which has for purpose of securing the communication path end to end (E2E).";
CM_ SG_ 1044 Calc_Threshold "The signal represents the calculated threshold value for the hands-off detection.";
CM_ SG_ 1044 Real_Impedence "The signal represents the currently measured real part value";
CM_ SG_ 1044 Immag_Impedence "The signal represents the currently measured imaginary part value.";
CM_ SG_ 1044 ERR_ST_HOD "The signal includes the error information of the HOD.";
CM_ SG_ 1044 RsErr_HOD "The signal represents the standard communication error bit as specified in the LIN protocol.";
CM_ SG_ 1044 HOD_status "The signal includes the information, whether the driver touches the steering wheel or not.";
CM_ BO_ 1046 "BCM Mirror Confirm Sts";
CM_ SG_ 1046 CHKSM_BCM_STAT_Mirror "Checksum";
CM_ SG_ 1046 ALV_BCM_STAT_Mirror "Alive Counter";
CM_ SG_ 1046 BCM_STAT_LeftMirrorPosX "Set left mirror left right position";
CM_ SG_ 1046 BCM_STAT_LeftMirrorPosY "Set left mirror up/down position";
CM_ SG_ 1046 BCM_STAT_RightMirrorPosX "Set right mirror left right position";
CM_ SG_ 1046 BCM_STAT_RightMirrorPosY "Set right mirror up down position";
CM_ SG_ 1046 BCM_STAT_Mirror "Represent the status of Mirror Fold/Unfold
";
CM_ SG_ 1046 BCM_STAT_MirrorAdjustLeft "Enter setting Mirror position mode";
CM_ SG_ 1046 BCM_STAT_MirrorAdjustRight "Enter setting Mirror position mode";
CM_ BO_ 1049 "SHVU F Confirm Sts";
CM_ SG_ 1049 SHVU_STAT_SeatHeatingFrontL "Change Seat heating with 3 level";
CM_ SG_ 1049 SHVU_STAT_SeatHeatingFrontR "Change Seat heating with 3 level";
CM_ SG_ 1049 SHVU_STAT_SeatCoolingFrontL "Change Seat cooling with 3 level";
CM_ SG_ 1049 SHVU_STAT_SeatCoolingFrontR "Change Seat cooling with 3 level";
CM_ SG_ 1049 SHVU_STAT_FrontSeatVentSts "Indicate current status of front seat ventilation system";
CM_ BO_ 1050 "SHVU R Confirm Sts";
CM_ SG_ 1050 SHVU_STAT_SeatCoolingRearL "Change Seat cooling with 3 level";
CM_ SG_ 1050 SHVU_STAT_SeatCoolingRearR "Change Seat cooling with 3 level";
CM_ SG_ 1050 SHVU_STAT_SeatHeatingReartL "Change Seat heating with 3 level";
CM_ SG_ 1050 SHVU_STAT_SeatHeatingRearR "Change Seat heating with 3 level";
CM_ SG_ 1050 SHVU_STAT_RearSeatVentSts "Indicate current status of rear seat ventilation system";
CM_ BO_ 1052 "PSM seat position";
CM_ SG_ 1052 CHKSM_PSM_SEAT_POSITION "Checksum";
CM_ SG_ 1052 AVL_PSM_SEAT_POSITION "Alive Counter";
CM_ SG_ 1052 PSM_Seat_track_pos_Dri "PSM Seat track position driver";
CM_ SG_ 1052 PSM_Seat_track_posPas "PSM Seat track position front passenger";
CM_ BO_ 1053 "BCM Comfortable Confirm status";
CM_ SG_ 1053 BCM_STAT_AutoRearWiper "On/Off Auto rear wiper";
CM_ SG_ 1053 BCM_STAT_MirrorFoldSetting "Status MirrorFold Default value =  0x1 Auto Fold ON/Invalid value = 3";
CM_ SG_ 1053 BCM_STAT_IMMO_KeyfobID2 "console as per request of a MHU to link keyfob to a profile - improvement signal";
CM_ SG_ 1053 BCM_STAT_MirrorAutoUnfold "Change Mirror Auto unfold mode";
CM_ SG_ 1053 BCM_STAT_MirrorReverseLink "Mirror Auto Tilt On Reverse Feedback";
CM_ SG_ 1053 BCM_STAT_MirrorDefaultSTATting "Trigger the default Mirror setting";
CM_ SG_ 1053 BCM_STAT_WelcomeTriggerCondition "Confirm Welcome trigger condition";
CM_ SG_ 1053 BCM_STAT_FrontDomeLamp "Confirm setting On/Off/Auto Front Dome Lamp";
CM_ SG_ 1053 BCM_STAT_FollowMeHome "Change follow me home headlamp mode and delay";
CM_ SG_ 1053 BCM_STAT_ExteriorLight "Change Exterior light mode";
CM_ SG_ 1053 BCM_STAT_RemoteLockFeedback "Remote Lock dback: customer can choose light feedback when lock the door with remote key";
CM_ SG_ 1053 BCM_STAT_RemoteDoorUnlock "Settings for Door lock unlock conditions";
CM_ SG_ 1053 BCM_STAT_AutoDoorUnlock "Auto door unlock: When the car is stopped and the shift lever is in ?P? position, selected doors will be unlocked automatically";
CM_ SG_ 1053 BCM_STAT_AmbientLightBrighness "Change Ambient light brighness percent";
CM_ SG_ 1053 BCM_STAT_WalkawayDoorLock "Walk away lock State";
CM_ SG_ 1053 BCM_STAT_WiperServiceMode "console as per request of a MHU to link keybof to a";
CM_ SG_ 1053 BCM_STAT_IMMO_KeyfobID "console as per request of a MHU to link keybof to a";
CM_ SG_ 1053 BCM_STAT_RearHeatedWindowMirror "This signal is necessary for the activation or deactivation of the rear screen heating for the rear window and the mirrors.Invalid value = 3";
CM_ SG_ 1053 BCM_STAT_AntiTheftMode "Confirm of setting Anti-theft mode ";
CM_ SG_ 1053 BCM_STAT_ClimateKeepOnSts "Climate keep ON feedback status
";
CM_ SG_ 1053 BCM_STAT_FKSfeedback "BCM_STAT_FKSfeedback";
CM_ SG_ 1053 SECCAN_CmftCnfrm "Secret portion from Secure CAN algorithm";
CM_ BO_ 1055 "OCS passenger status";
CM_ SG_ 1055 OCS_P_CHKSM "Checksum";
CM_ SG_ 1055 OCS_P_AVL "Alive Counter";
CM_ SG_ 1055 OCS_Passenger_class_stat "Occupant classification sensor for passenger";
CM_ BO_ 1058 "MHU Status";
CM_ SG_ 1058 CHKSM_MHU_STAT "Checksum";
CM_ SG_ 1058 ALV_MHU_STAT "Alive Counter";
CM_ SG_ 1058 MHU_STAT_Cluster "State of Cluster screen for serving Fail-save mode";
CM_ SG_ 1058 MHU_STAT_Infotainment "State of Infotainment screen for serving Fail-save mode";
CM_ SG_ 1058 MHU_STAT_MileageUnit "Indicate current unit of mileage display in Screen (Km or Miles)";
CM_ SG_ 1058 MHU_STAT_PressureUnit "Indicate current unit of Pressure(psi, Bar, kPa)";
CM_ SG_ 1058 MHU_STAT_TemperatureUnit "Indicate current unit of Temperature (C, F)";
CM_ SG_ 1058 MHU_Operation_State "Operation state of MHU
";
CM_ SG_ 1058 MHU_STAT_Language "Indicate current Language";
CM_ SG_ 1058 MHU_STAT_EnergyConsumptionUnit "Indicate current unit of Enery Consumption (KWH per 100Km)";
CM_ SG_ 1058 BAS_version "BAS Version";
CM_ SG_ 1058 MHU_STAT_SaleCountry "Current Sale Country by Map engine - encode by ISO 3166-1 numeric";
CM_ BO_ 1064 "TRM fitted status and keyfob left the car warning";
CM_ SG_ 1064 TRMFitted "Signal indicating that TRM is fitted or not. Signal is copy of H16 parameter in the VOD setting withing XGW";
CM_ BO_ 1068 "PSM Control Status";
CM_ SG_ 1068 CHSKM_PSM_D_SEAT_CONTROL "Checksum";
CM_ SG_ 1068 ALV_PSM_D_SEAT_CONTROL "Alive Counter";
CM_ SG_ 1068 PSM_D_DrvSeat_Control_Status "PSM_D driver seat control status";
CM_ SG_ 1068 PSM_D_DrvReclinerPos "Current recliner position of driver seat";
CM_ SG_ 1068 PSM_D_DrvTiltPos "Current tilt position of driver seat";
CM_ SG_ 1068 PSM_D_DrvTrackPos "Current track position of driver seat";
CM_ SG_ 1068 PSM_D_DrvHeightPos "Current height position of driver seat";
CM_ BO_ 1074 "MHU_FOTA_STATUS";
CM_ SG_ 1074 MHU_FOTA_Checksum "FOTA global status message checksum";
CM_ SG_ 1074 MHU_FOTA_Alive_Counter "FOTA global status message alive counter";
CM_ SG_ 1074 MHU_FOTA_State "FOTA global status";
CM_ SG_ 1074 MHU_FOTA_Error_Code "FOTA Error Code";
CM_ BO_ 1077 "Information transmit from SCM to BCM to CAN Network";
CM_ SG_ 1077 BCM_SCM_BC_Button "Status of Board Computer buton";
CM_ BO_ 1082 "VCU MHU Information";
CM_ SG_ 1082 CRC_VCU_MHU_info "Checksum";
CM_ SG_ 1082 ALIV_VCU_MHU_info "Alive counter";
CM_ SG_ 1082 VCU_BrakeRegenMode "VCU Brake regenerative mode";
CM_ SG_ 1082 VCU_CreepDisable_stt "Feedback for Creep disable request";
CM_ SG_ 1082 VCU_PowerRegenGaugeDisplay "Power Regen gauge display, plus vaue is power level, minus value is regen level. ";
CM_ SG_ 1082 VCU_Charging_Authen_stt "Authentication status with chg. station ( for display only)";
CM_ SG_ 1082 VCU_ChgGun_BadConn_stt "Charging gun bad connection status";
CM_ SG_ 1082 VCU_ChgPort_Open_stt "Open status of charging port";
CM_ SG_ 1082 VCU_Regen_available "When braking / coasting regeneration system not available or regeneration system capability = 0 or regeneration system = failed.";
CM_ SG_ 1082 VCU_VehChg_STS "Vehicle Charging Status";
CM_ SG_ 1082 VCU_SOC_display "HV battery SOC for displaying only - for VCU strategy";
CM_ SG_ 1082 VCU_ChgGun_Status "Charging gun status";
CM_ SG_ 1082 VCU_ChgPort_Lock_stt "Lock status of chaging port";
CM_ SG_ 1082 VCU_Hvbatt_charging_stt "HV battery charging - not charging status,for displaying only ( for both regen/ charging )";
CM_ BO_ 1089 "RESP REMOTE FUNCTION APM";
CM_ SG_ 1089 CHKSM_RESP_REM_FUNC_APM "Checksum";
CM_ SG_ 1089 RESP_REM_ResponseID_APM "The Service Identifier contains the information which function is requested";
CM_ SG_ 1089 RESP_REM_DataByte0_APM "Data byte for the  remote function";
CM_ SG_ 1089 RESP_REM_DataByte1_APM "Data byte for the  remote function";
CM_ SG_ 1089 RESP_REM_DataByte2_APM "Data byte for the  remote function";
CM_ SG_ 1089 RESP_REM_DataByte3_APM "Data byte for the  remote function";
CM_ SG_ 1089 RESP_REM_DataByte4_APM "Adresse of transmitter for remote functions";
CM_ SG_ 1089 RESP_REM_LengthTyp_APM "Lenght bit identify how long are the response  data";
CM_ SG_ 1089 RESP_REM_DataLength_APM "Lenght of the used data for the remote function response";
CM_ BO_ 1090 "Wireless Charge Status";
CM_ SG_ 1090 WLC_IC_Error "Internal Error (Charging IC)";
CM_ SG_ 1090 WLC_FAN_Error "FAN fault";
CM_ SG_ 1090 WLC_TempSNSR_Error "Temperature sensor fault";
CM_ SG_ 1090 WLC_Setting_standard "Need to transmit information on WPC ON/OFF Setting standard or Set standard";
CM_ SG_ 1090 Transmit_WLC_situation "Need to transmit WPC situation signal ";
CM_ SG_ 1090 WLC_VehSpeed_Error "Maximum vehicle speed over error (> 300 km/h)";
CM_ SG_ 1090 WLC_Resp_Error "Any error from WLC side";
CM_ SG_ 1090 WLC_FOD_Error "FOD error, Foreign Object detection";
CM_ SG_ 1090 WLC_Curr_Error "Over current";
CM_ SG_ 1090 WLC_Temp_Error "Over temperature";
CM_ BO_ 1091 "Wireless Charge Status 2";
CM_ SG_ 1091 WLC_IC_Error_2 "Internal Error (Charging IC)";
CM_ SG_ 1091 WLC_FAN_Error_2 "FAN fault";
CM_ SG_ 1091 WLC_TempSNSR_Error_2 "Temperature sensor fault";
CM_ SG_ 1091 WLC_Setting_standard_2 "Need to transmit information on WPC ON/OFF Setting standard or Set standard";
CM_ SG_ 1091 Transmit_WLC_situation_2 "Need to transmit WPC situation signal ";
CM_ SG_ 1091 WLC_VehSpeed_Error_2 "Maximum vehicle speed over error (> 300 km/h)";
CM_ SG_ 1091 WLC_Resp_Error_2 "Any error from WLC side";
CM_ SG_ 1091 WLC_FOD_Error_2 "FOD error, Foreign Object detection";
CM_ SG_ 1091 WLC_Curr_Error_2 "Over current";
CM_ SG_ 1091 WLC_Temp_Error_2 "Over temperature";
CM_ BO_ 1093 "Rain light sensor";
CM_ SG_ 1093 RS_Sol_L "Left Solar sensor values for the CCU";
CM_ SG_ 1093 RS_Sol_R "Right Solar sensor values for the CCU";
CM_ SG_ 1093 RS_F_LightSensor "Light sensor HW error";
CM_ SG_ 1093 RS_F_HUD_Sensor "HUD HW error";
CM_ SG_ 1093 RS_St_LampReq "Rain light sensor lamp request";
CM_ SG_ 1093 RS_St_CurrentRain "Represents the intensity of rain from RLS";
CM_ SG_ 1093 RS_HUD_illuminance "HUD sensor input";
CM_ BO_ 1095 "MHU_CarMode_Switch";
CM_ SG_ 1095 MHU_SET_TransportMode "Enable/Disable Transport mode via MHU";
CM_ SG_ 1095 CHKSM_MHU_SET_CarMode "Checksum";
CM_ SG_ 1095 ALV_MHU_SET_CarMode "Alive counter";
CM_ SG_ 1095 MHU_Request_CarOFF "MHU request Car go to OFF state";
CM_ SG_ 1095 MHU_SET_ChildMode "Set Car in Child mode which keep climate control running and delay CPD (EU NCAP requirement)";
CM_ SG_ 1095 MHU_SET_GameMode "Set Car in Game mode";
CM_ SG_ 1095 MHU_SET_KaraokeMode "Set Car in Karaoket mode";
CM_ SG_ 1095 MHU_SET_WashMode "Set Car in Wash mode";
CM_ SG_ 1095 MHU_SET_StopMode "Set Car Stop mode";
CM_ BO_ 1104 "MHU Window Setting";
CM_ SG_ 1104 WindowLifterFrontL "Window lifter Front Driver";
CM_ SG_ 1104 WindowLifterFrontR "Window lifter Front Passenger";
CM_ SG_ 1104 WindowLifterRearL "Window lifter Rear Left";
CM_ SG_ 1104 WindowLifterRearR "Window lifter Rear Right";
CM_ SG_ 1104 MHU_SET_WindowAutoClose "Auto close windows when doors are locked";
CM_ BO_ 1110 "SCM_Raw_Status";
CM_ SG_ 1110 OP_WISW_SZL_LIN "Wiper Status Signal (Right Stalk)
Bit 0~1 : Switch status on Automatic wiping, Wiper step 1, Wiper step 2 switch status
Bit 2: Not used.(this bit is always 0.)
Bit 3: Front mist switch status
Bit 4: Front washer switch status
Bit 5: Not used.(this bit is always 0.)
Bit 6: Rear wiping switch status
Bit 7: Rear washing switch status
* 1111 1111: Signal Invalid
";
CM_ SG_ 1110 COMM_ERR_SZL_LIN "This signal showes if there is or was a communication error.";
CM_ SG_ 1110 BCM_Wiper_Front_Status "Front Wiper Motor Feedback of status";
CM_ SG_ 1110 OP_WIPO_SZL_LIN "Wiper Step (Right Stalk)
0x0: Step 1
0x1: Step 2
0x2: Step 3
0x4: Step 4
0x7: signal invalid
";
CM_ SG_ 1110 OP_COLS_SZL_LIN "Left Stalk Lever Signal (Light function)
*the status of each bit follows this: (0: Off, 1: ON)
Bit 0: Highway flashing right indicator status
Bit 1: Flashing right indicator status
Bit 2: Highway flashing left indicator status
Bit 3: Flashing left indicator status
Bit 4: High-beam light status
Bit 5: High-beam light flashing status
Bit 6: Reserved
Bit 7: Not used.(this value is always ?0?)
* 1111 1111: Signal Invalid";
CM_ SG_ 1110 NOD_ERR_SZL_LIN "If SCM detects any error (any error status occurred), SCM sends this signal as ?error active?.";
CM_ SG_ 1110 BCM_Wiper_Rear_Status "Rear wiper status check";
CM_ SG_ 1110 ALIV_WISW_SZL_LIN "Standard Alive-counter for validation of the transmission between SCM and Master ECU.";
CM_ BO_ 1111 "BCM_ALM_warning";
CM_ SG_ 1111 AmbLight_Error_Z5 "Status of Ambient Light ColorZone 5";
CM_ SG_ 1111 AmbLight_Error_Z4 "Status of Ambient Light ColorZone 4";
CM_ SG_ 1111 AmbLight_Error_Z3 "Status of Ambient Light ColorZone 3";
CM_ SG_ 1111 AmbLight_Error_Z2 "Status of Ambient Light ColorZone 2";
CM_ SG_ 1111 AmbLight_Error_Z1 "Status of Ambient Light ColorZone 1";
CM_ BO_ 1112 "MHU_BCM_Color_Req";
CM_ SG_ 1112 AmbLightColorZoneReq "Zone identifier for interior ambient lighting colour.
Allows smart LED module to take into account messages addressed to
their zone when colour value are received.";
CM_ SG_ 1112 AmbLightColorRed "Requested Ambient Lighting Red Intensity";
CM_ SG_ 1112 AmbLightColorGreen "Requested Ambient Lighting Green Intensity";
CM_ SG_ 1112 AmbLightColorBlue "Requested Ambient Lighting Blue Intensity";
CM_ SG_ 1112 SECCAN_BCM_Clr_Rq "Seed generated from Secure CAN algorithm";
CM_ BO_ 1113 "MHU_BCM_IntensityTiming_Req";
CM_ SG_ 1113 AmbLightIntensityTimingZoneReq "Zone identifier for interior ambient lighting intensity. Allows smart LED module to take into account messages addressed to their zone when intensity value are received.";
CM_ SG_ 1113 AmbLightIntensityTimingTypeReq "Zone identifier for interior ambient lighting intensity.
Allows smart LED module to take into account messages about Type of Timing to used.";
CM_ SG_ 1113 AmbLightIntenTimingBrightReq "Intensity (brightness) of interior ambient lighting.";
CM_ SG_ 1113 AmbLightIntensityTimingT1Req "Blinking: Ton; Wave: Tfade; Morse: Ton1; Fading: Tfade";
CM_ SG_ 1113 AmbLightIntensityTimingT2Req "Blinking: Toff; Wave: not used; Morse: Toff1, Fading: not used";
CM_ SG_ 1113 AmbLightIntensityTimingT3Req "Blinking: not used; Wave: not used; Morse: Ton2, Fading: not used";
CM_ SG_ 1113 AmbLightIntensityTimingT4Req "Blinking: not used; Wave: not used; Morse: Toff2, Fading: not used";
CM_ SG_ 1113 AmbLightIntensityTimingN2Req "Morse: number of repetitions for Ton2";
CM_ SG_ 1113 AmbLightIntensityTimingN1Req "Morse: number of repetitions for Ton1";
CM_ BO_ 1124 "LDM_L Light Status";
CM_ SG_ 1124 LDML_LampAssemblySts "Left Combined Lamp Module Failure Status";
CM_ SG_ 1124 LDML_PosLmpSts "Left Position light output Status";
CM_ SG_ 1124 LDML_ControllerSts "Left Light Driving Module Controller Failure Status";
CM_ SG_ 1124 LDML_TurnIndicatorSts "Left Turn light output  Status";
CM_ SG_ 1124 LDML_AuxLBSts "Left Auxiliary low beam output  Status";
CM_ SG_ 1124 LDML_LowBeamSts "Left Low beam output  Status";
CM_ SG_ 1124 LDML_HighBeamSts "Left High beam output Status";
CM_ SG_ 1124 LDML_DayRunningLampSts "Left DayRunning Lamp output Status";
CM_ SG_ 1124 LDML_DayTimeRunningLightFbSts "The Feedback Status of On/Off DayTime Running Light switch";
CM_ SG_ 1124 LDML_AutoLvlFbSts "The Feedback Status of On/Off Auto-leveling switch";
CM_ SG_ 1124 LDML_AdptvDrvBeamFbSts "The Feedback Status of On/Off Adaptive Driving Beam switch";
CM_ SG_ 1124 LDML_AuxHBSts "Left Auxiliary high beam output  Status";
CM_ SG_ 1124 LDML_FollowMeHomeFbSts "The Feedback Status of Follow Me Home mode switch";
CM_ SG_ 1124 LDML_ExteriorLightFbSts "The Feedback Status of Exterior Light mode switch";
CM_ BO_ 1125 "LDM_R Light Status";
CM_ SG_ 1125 LDMR_LampAssemblySts "Right Combined Lamp Module Failure Status";
CM_ SG_ 1125 LDMR_PosLmpSts "Right Position light output Status";
CM_ SG_ 1125 LDMR_ControllerSts "Right Light Driving Module Controller Failure Status";
CM_ SG_ 1125 LDMR_TurnIndicatorSts "Right Turn light output  Status";
CM_ SG_ 1125 LDMR_AuxLBSts "Right Auxiliary low beam output  Status";
CM_ SG_ 1125 LDMR_LowBeamSts "Right Low beam output  Status";
CM_ SG_ 1125 LDMR_HighBeamSts "Right High beam output Status";
CM_ SG_ 1125 LDMR_DayRunningLampSts "Right DayRunning Lamp output Status";
CM_ SG_ 1125 LDMR_DayTimeRunningLightFbSts "The Feedback Status of On/Off DayTime Running Light switch
";
CM_ SG_ 1125 LDMR_AutoLvlFbSts "The Feedback Status of On/Off Auto-leveling switch
";
CM_ SG_ 1125 LDMR_AdptvDrvBeamFbSts "The Feedback Status of On/Off Adaptive Driving Beam switch";
CM_ SG_ 1125 LDMR_AuxHBSts "Right Auxiliary high beam output  Status";
CM_ SG_ 1125 LDMR_FollowMeHomeFbSts "The Feedback Status of Follow Me Home mode switch";
CM_ SG_ 1125 LDMR_ExteriorLightFbSts "The Feedback Status of Exterior Light mode switch";
CM_ BO_ 1152 "PSM WarnMsg";
CM_ SG_ 1152 CHKSM_PSM_WARNING_MSG "Checksum for PSM warning message";
CM_ SG_ 1152 ALV_PSM_WARNING_MSG "Alive counter for PSM warning message";
CM_ SG_ 1152 PSM_DrvSeatMissalignment "Driver Seat Misalignment";
CM_ SG_ 1152 PSM_PasSeatMisalignment "Passenger Seat Misalignment";
CM_ SG_ 1152 PSM_WflagRes3 "Warning Flag Reserved Bit 3";
CM_ SG_ 1152 PSM_WflagRes4 "Warning Flag Reserved Bit 4";
CM_ SG_ 1152 PSM_WflagRes5 "Warning Flag Reserved Bit 5";
CM_ SG_ 1152 PSM_WflagRes6 "Warning Flag Reserved Bit 6";
CM_ SG_ 1152 PSM_WflagRes7 "Warning Flag Reserved Bit 7";
CM_ SG_ 1152 PSM_WflagRes8 "Warning Flag Reserved Bit 8";
CM_ SG_ 1152 PSM_WflagRes9 "Warning Flag Reserved Bit 9";
CM_ SG_ 1152 PSM_WflagRes10 "Warning Flag Reserved Bit 10";
CM_ SG_ 1152 PSM_WflagRes11 "Warning Flag Reserved Bit 11";
CM_ SG_ 1152 PSM_WflagRes12 "Warning Flag Reserved Bit 12";
CM_ BO_ 1153 "BCM Warn Msg";
CM_ SG_ 1153 CHSKM_BCM_WarnMsg "Checksum BCM Warning Message";
CM_ SG_ 1153 ALV_BCM_WarnMsg "Alive counter";
CM_ SG_ 1153 BCM_NoValidKey_1 "Illegal key in the car";
CM_ SG_ 1153 BCM_SSB_defect "SSB button defect";
CM_ SG_ 1153 BCM_WrongGearPosToStart "Gear position is not P/N, Gear in wrong position to start";
CM_ SG_ 1153 BCM_NoValidKey_2 "Key FOBs are not in the car";
CM_ SG_ 1153 BCM_PressBrakeToStart "Brake padel not pressed to start the car";
CM_ SG_ 1153 BCM_TurnOffPosLightRemindr "Driver forget to turn off Position Lights during leaving car";
CM_ SG_ 1153 BCM_KeyFob_LowBattery "Keyfob battery low";
CM_ SG_ 1153 BCM_StopLightDefect "Stop light defect";
CM_ SG_ 1153 BCM_LowBeamDefect "Low beam defect";
CM_ SG_ 1153 BCM_HighBeamDefect "High beam defect";
CM_ SG_ 1153 BCM_PositionLightDefect "Position light defect";
CM_ SG_ 1153 BCM_CHMLS_Defect "CHMSL defect";
CM_ SG_ 1153 BCM_LicencePlateLight_Defect "License plate light defect";
CM_ SG_ 1153 BCM_FrontFog_Defect "Front fog lamp defect";
CM_ SG_ 1153 BCM_RearFog_Defect "Rear fog lamp defect";
CM_ SG_ 1153 BCM_ReverseLightDefect "Reverse lamp defect";
CM_ SG_ 1153 BCM_RLS_Malfunction "Rain/Light sensor malfunction";
CM_ SG_ 1153 BCM_12VBattery_LowLevel "Low level 12V Battery";
CM_ SG_ 1153 BCM_ForgetKeyFOBInCar "Locking the car when the key in the car";
CM_ SG_ 1153 BCM_12VBattery_Discharging "12V battery discharging";
CM_ SG_ 1153 BCM_TurnIndicatorDefect "Turn indicator defect";
CM_ SG_ 1153 BCM_dTPMS_Malfunc "TPMS malfunction";
CM_ SG_ 1153 BCM_dTPMS_Malfunc_LostSensor "TPMS Malfunction, Lost sensor alarm";
CM_ SG_ 1153 BCM_dTPMS_LowPressure "Low tire pressure";
CM_ SG_ 1153 BCM_dTPMS_RapidLeak "Rapid air leak alarm";
CM_ SG_ 1153 BCM_dTPMS_HighTemperature "High tire temperature";
CM_ SG_ 1153 BCM_dTPMS_HighPressure "High tire pressure";
CM_ SG_ 1153 BCM_dTPMS_LowBattery "TPMS sensor Low battery";
CM_ SG_ 1153 BCM_Keyfob_Leftcar "Keyfob left the car warning";
CM_ SG_ 1153 BCM_SCM_Malfunction "SCM Malfunction";
CM_ SG_ 1153 BCM_CrashSignalDefect "Crash Unlcokxa0Signalxa0error";
CM_ SG_ 1153 BCM_FrontWiperDefect "Front wiper Fail";
CM_ SG_ 1153 BCM_Rear_RightDoorLockDefect "BCM RearDoor Fail";
CM_ SG_ 1153 BCM_RearLeftDoorLockDefect "BCM rearLeft door fail";
CM_ SG_ 1153 BCM_Front_RightDoorLockDefect "FrontRightDoorLock Fail";
CM_ SG_ 1153 BCM_FrontLeftDoorLockDefect "FrontLeftDoorLock Fail";
CM_ SG_ 1153 BCM_LDML_Malfunction "Front right ligth driver module Malfunction";
CM_ SG_ 1153 BCM_LDMR_Malfunction "Rear right ligth driver module Malfunction";
CM_ SG_ 1153 BCM_RLBL_Malfunction "Rear left ligth driver module Malfunction";
CM_ SG_ 1153 BCM_RLBR_Malfunction "Rear right ligth driver module Malfunction";
CM_ SG_ 1153 BCM_RLT_Malfunction "Tailgate ligth driver module Malfunction";
CM_ BO_ 1155 "TPMS TirePressure";
CM_ SG_ 1155 TPMS_FLTirePress "Front left tire pressure signal";
CM_ SG_ 1155 TPMS_FRTirePress "Front right tire pressure signal";
CM_ SG_ 1155 TPMS_RLTirePress "Rear left tire pressure signal";
CM_ SG_ 1155 TPMS_RRTirePress "Rear right tire pressure signal";
CM_ SG_ 1155 TPMS_FLTirePressAlarm "Front left tire pressure alarm  signal";
CM_ SG_ 1155 TPMS_FRTirePressAlarm "Front right tire pressure alarm signal";
CM_ SG_ 1155 TPMS_RLTirePressAlarm "Rear left tire pressure alarm signal";
CM_ SG_ 1155 TPMS_RRTirePressAlarm "Rear right tire pressure alarm signal";
CM_ SG_ 1155 TPMS_TirePosition "Tire position signal";
CM_ SG_ 1155 TPMS_ready2learning "BCM feedback signal ready to learning";
CM_ SG_ 1155 TPMS_TireTempAlarm "Tire temperature alarm signal";
CM_ SG_ 1155 TPMS_LearningStatus "BCM feedback signal for learning status";
CM_ SG_ 1155 TPMS_TireTemp "Tire temperature signal";
CM_ BO_ 1156 "APA FEEDBACK MHU ";
CM_ SG_ 1156 CHKSM_APA_FEEDBACK_MHU "Checksum";
CM_ SG_ 1156 ALV_APA_FEEDBACK_MHU "Alive Counter";
CM_ SG_ 1156 APA_MHU_Status "APA_Status";
CM_ BO_ 1158 "TPMS_TirePressure2";
CM_ SG_ 1158 CHKSM_TirePressAlarm "Checksum";
CM_ SG_ 1158 ALV_TirePressAlarm "Alive Counter";
CM_ SG_ 1158 TPMS_FLTirePressAlarm2 "Front left tire pressure alarm  signal";
CM_ SG_ 1158 TPMS_FRTirePressAlarm2 "Front right tire pressure alarm signal";
CM_ SG_ 1158 TPMS_RLTirePressAlarm2 "Rear left tire pressure alarm signal";
CM_ SG_ 1158 TPMS_RRTirePressAlarm2 "Rear right tire pressure alarm signal";
CM_ BO_ 1160 "ACM WarnMsg";
CM_ SG_ 1160 CHKSM_ACM_WARNING_MSG "Checksum for ACM warning message";
CM_ SG_ 1160 ALV_ACM_WARNING_MSG "Alive counter for ACM warning message";
CM_ SG_ 1160 ACM_Malfunction "ACM Malfunction (trigger airbag warning lamp)";
CM_ SG_ 1160 ACM_Pre_Drive_Check "ACM status after pre-drive check (trigger airbag warning lamp if any failure) ";
CM_ SG_ 1160 ACM_in_Plant_Mode "ACM plant mode status (trigger airbag warning lamp) ";
CM_ SG_ 1160 ACM_PAB_Suppression "ACM suppress passenger airbag (front AB 1st stage, front AB 2nd stage, knee AB). This is used to trigger PAB indicator in MHU's display. ";
CM_ SG_ 1160 ACM_Airbag_Disabled "ACM airbag disabled status due to Algo disabled or Firing disabled due to diagnostic or inert calibration file is flashed (trigger Airbag warning lamp when airbag is disabled)";
CM_ SG_ 1160 ACM_Development_Calibration "ACM calibration file status indicate whether ACM is flashed with calibration file for development purpose only (trigger Airbag warning lamp and chime when ACM is flashed with development calibration file)";
CM_ SG_ 1160 ACM_In_Disposal_Mode "ACM disposal mode status (trigger airbag warning lamp when ACM in disposal mode)";
CM_ SG_ 1160 ACM_Seatbelt_Reminder_Request "ACM request seatbelt reminder (1 signal for whole front and rear seats)";
CM_ SG_ 1160 ACM_SBR_Chime_Req "ACM request chime to MHU for seatbelt reminder front row";
CM_ SG_ 1160 ACM_SBR_Blinking_Req "ACM send blinking request to MHU (trigger blinking of seatbelt reminder lamp)";
BA_DEF_ BO_  "GenMsgSendType" ENUM  "Cyclic","NotUsed","NotUsed","NotUsed","NotUsed","NotUsed","NotUsed","IfActive","NoMsgSendType","NotUsed";
BA_DEF_ BO_  "GenMsgILSupport" ENUM  "No","Yes";
BA_DEF_ BO_  "DiagResponse" ENUM  "No","Yes";
BA_DEF_ BO_  "DiagRequest" ENUM  "No","Yes";
BA_DEF_ BO_  "NmAsrMessage" ENUM  "No","Yes";
BA_DEF_ BO_  "DiagState" ENUM  "No","Yes";
BA_DEF_ BO_  "DiagUudtResponse" ENUM  "False","True";
BA_DEF_ BO_  "GenMsgStartDelayTime" INT 0 65535;
BA_DEF_ BO_  "GenMsgDelayTime" INT 0 0;
BA_DEF_ BO_  "GenMsgNrOfRepetition" INT 0 0;
BA_DEF_ BO_  "GenMsgCycleTimeFast" INT 0 0;
BA_DEF_ BO_  "GenMsgCycleTime" INT 0 0;
BA_DEF_ SG_  "GenSigSendType" ENUM  "Cyclic","OnWrite","OnWriteWithRepetition","OnChange","OnChangeWithRepetition","IfActive","IfActiveWithRepetition","NoSigSendType","NotUsed","NotUsed","NotUsed","NotUsed","NotUsed";
BA_DEF_ SG_  "InvalidValue" STRING ;
BA_DEF_ SG_  "GenSigStartValue" INT 0 0;
BA_DEF_ SG_  "GenSigTimeoutTime_ALL" INT 0 65535;
BA_DEF_DEF_  "GenMsgSendType" "NoMsgSendType";
BA_DEF_DEF_  "GenMsgILSupport" "Yes";
BA_DEF_DEF_  "DiagResponse" "No";
BA_DEF_DEF_  "DiagRequest" "No";
BA_DEF_DEF_  "NmAsrMessage" "No";
BA_DEF_DEF_  "DiagState" "No";
BA_DEF_DEF_  "DiagUudtResponse" "False";
BA_DEF_DEF_  "GenMsgStartDelayTime" 0;
BA_DEF_DEF_  "GenMsgDelayTime" 0;
BA_DEF_DEF_  "GenMsgNrOfRepetition" 0;
BA_DEF_DEF_  "GenMsgCycleTimeFast" 0;
BA_DEF_DEF_  "GenMsgCycleTime" 0;
BA_DEF_DEF_  "GenSigSendType" "Cyclic";
BA_DEF_DEF_  "InvalidValue" "";
BA_DEF_DEF_  "GenSigStartValue" 0;
BA_DEF_DEF_  "GenSigTimeoutTime_ALL" 0;
BA_ "GenMsgCycleTime" BO_ 896 1000;
BA_ "GenMsgSendType" BO_ 896 0;
BA_ "GenMsgCycleTime" BO_ 897 200;
BA_ "GenMsgSendType" BO_ 897 0;
BA_ "GenMsgDelayTime" BO_ 905 10;
BA_ "GenMsgDelayTime" BO_ 920 10;
BA_ "GenMsgDelayTime" BO_ 921 10;
BA_ "GenMsgCycleTimeFast" BO_ 922 100;
BA_ "GenMsgNrOfRepetition" BO_ 922 3;
BA_ "GenMsgCycleTimeFast" BO_ 923 100;
BA_ "GenMsgNrOfRepetition" BO_ 923 3;
BA_ "GenMsgCycleTime" BO_ 925 50;
BA_ "GenMsgSendType" BO_ 925 0;
BA_ "GenMsgCycleTime" BO_ 993 100;
BA_ "GenMsgSendType" BO_ 993 0;
BA_ "GenMsgCycleTime" BO_ 1015 1000;
BA_ "GenMsgCycleTimeFast" BO_ 1015 50;
BA_ "GenMsgNrOfRepetition" BO_ 1015 3;
BA_ "GenMsgSendType" BO_ 1015 0;
BA_ "GenMsgCycleTimeFast" BO_ 1025 100;
BA_ "GenMsgNrOfRepetition" BO_ 1025 3;
BA_ "GenMsgCycleTime" BO_ 1026 100;
BA_ "GenMsgCycleTimeFast" BO_ 1026 100;
BA_ "GenMsgNrOfRepetition" BO_ 1026 3;
BA_ "GenMsgSendType" BO_ 1026 0;
BA_ "GenMsgCycleTime" BO_ 1027 100;
BA_ "GenMsgSendType" BO_ 1027 0;
BA_ "GenMsgCycleTimeFast" BO_ 1028 100;
BA_ "GenMsgNrOfRepetition" BO_ 1028 3;
BA_ "GenMsgCycleTimeFast" BO_ 1029 50;
BA_ "GenMsgNrOfRepetition" BO_ 1029 3;
BA_ "GenMsgCycleTimeFast" BO_ 1030 100;
BA_ "GenMsgNrOfRepetition" BO_ 1030 3;
BA_ "GenMsgCycleTimeFast" BO_ 1032 100;
BA_ "GenMsgNrOfRepetition" BO_ 1032 3;
BA_ "GenMsgCycleTime" BO_ 1036 200;
BA_ "GenMsgSendType" BO_ 1036 0;
BA_ "GenMsgCycleTime" BO_ 1037 120;
BA_ "GenMsgSendType" BO_ 1037 0;
BA_ "GenMsgSendType" BO_ 1042 0;
BA_ "GenMsgCycleTime" BO_ 1042 400;
BA_ "GenMsgCycleTime" BO_ 1044 500;
BA_ "GenMsgSendType" BO_ 1044 0;
BA_ "GenMsgCycleTime" BO_ 1046 100;
BA_ "GenMsgSendType" BO_ 1046 0;
BA_ "GenMsgCycleTime" BO_ 1052 1000;
BA_ "GenMsgSendType" BO_ 1052 0;
BA_ "GenMsgCycleTime" BO_ 1053 100;
BA_ "GenMsgSendType" BO_ 1053 0;
BA_ "GenMsgCycleTime" BO_ 1055 500;
BA_ "GenMsgSendType" BO_ 1055 0;
BA_ "GenMsgCycleTime" BO_ 1058 1000;
BA_ "GenMsgSendType" BO_ 1058 0;
BA_ "GenMsgCycleTime" BO_ 1064 200;
BA_ "GenMsgSendType" BO_ 1064 0;
BA_ "GenMsgCycleTime" BO_ 1068 200;
BA_ "GenMsgSendType" BO_ 1068 0;
BA_ "GenMsgCycleTime" BO_ 1074 500;
BA_ "GenMsgSendType" BO_ 1074 0;
BA_ "GenMsgCycleTimeFast" BO_ 1077 100;
BA_ "GenMsgNrOfRepetition" BO_ 1077 3;
BA_ "GenMsgCycleTime" BO_ 1082 100;
BA_ "GenMsgSendType" BO_ 1082 0;
BA_ "GenMsgCycleTimeFast" BO_ 1089 100;
BA_ "GenMsgNrOfRepetition" BO_ 1089 3;
BA_ "GenMsgCycleTime" BO_ 1090 500;
BA_ "GenMsgSendType" BO_ 1090 0;
BA_ "GenMsgCycleTime" BO_ 1091 500;
BA_ "GenMsgSendType" BO_ 1091 0;
BA_ "GenMsgCycleTime" BO_ 1093 100;
BA_ "GenMsgSendType" BO_ 1093 0;
BA_ "GenMsgCycleTime" BO_ 1095 200;
BA_ "GenMsgSendType" BO_ 1095 0;
BA_ "GenMsgCycleTimeFast" BO_ 1104 100;
BA_ "GenMsgNrOfRepetition" BO_ 1104 3;
BA_ "GenMsgCycleTimeFast" BO_ 1112 100;
BA_ "GenMsgNrOfRepetition" BO_ 1112 3;
BA_ "GenMsgCycleTimeFast" BO_ 1113 100;
BA_ "GenMsgNrOfRepetition" BO_ 1113 3;
BA_ "GenMsgCycleTime" BO_ 1124 50;
BA_ "GenMsgSendType" BO_ 1124 0;
BA_ "GenMsgCycleTime" BO_ 1125 50;
BA_ "GenMsgSendType" BO_ 1125 0;
BA_ "GenMsgCycleTime" BO_ 1152 1000;
BA_ "GenMsgCycleTimeFast" BO_ 1152 100;
BA_ "GenMsgNrOfRepetition" BO_ 1152 2;
BA_ "GenMsgSendType" BO_ 1152 0;
BA_ "GenMsgCycleTime" BO_ 1153 1000;
BA_ "GenMsgCycleTimeFast" BO_ 1153 100;
BA_ "GenMsgDelayTime" BO_ 1153 25;
BA_ "GenMsgNrOfRepetition" BO_ 1153 2;
BA_ "GenMsgSendType" BO_ 1153 0;
BA_ "GenMsgCycleTime" BO_ 1155 50;
BA_ "GenMsgSendType" BO_ 1155 0;
BA_ "GenMsgCycleTime" BO_ 1156 50;
BA_ "GenMsgSendType" BO_ 1156 0;
BA_ "GenMsgSendType" BO_ 1158 0;
BA_ "GenMsgCycleTime" BO_ 1158 50;
BA_ "GenMsgCycleTime" BO_ 1160 1000;
BA_ "GenMsgCycleTimeFast" BO_ 1160 100;
BA_ "GenMsgNrOfRepetition" BO_ 1160 2;
BA_ "GenMsgSendType" BO_ 1160 0;
BA_ "GenSigTimeoutTime_ALL" SG_ 896 VIN_Byte1 5000;
BA_ "InvalidValue" SG_ 896 VIN_Byte1 "null";
BA_ "GenSigTimeoutTime_ALL" SG_ 896 VIN_Byte2 5000;
BA_ "InvalidValue" SG_ 896 VIN_Byte2 "null";
BA_ "GenSigTimeoutTime_ALL" SG_ 896 VIN_Byte3 5000;
BA_ "InvalidValue" SG_ 896 VIN_Byte3 "null";
BA_ "GenSigTimeoutTime_ALL" SG_ 896 VIN_Byte4 5000;
BA_ "InvalidValue" SG_ 896 VIN_Byte4 "null";
BA_ "GenSigTimeoutTime_ALL" SG_ 896 VIN_Byte5 5000;
BA_ "InvalidValue" SG_ 896 VIN_Byte5 "null";
BA_ "GenSigTimeoutTime_ALL" SG_ 896 VIN_Byte6 5000;
BA_ "InvalidValue" SG_ 896 VIN_Byte6 "null";
BA_ "GenSigTimeoutTime_ALL" SG_ 896 VIN_Byte7 5000;
BA_ "InvalidValue" SG_ 896 VIN_Byte7 "null";
BA_ "GenSigTimeoutTime_ALL" SG_ 897 CHKSM_ACM_SEAT_OCCUPATION 1000;
BA_ "InvalidValue" SG_ 897 CHKSM_ACM_SEAT_OCCUPATION "null";
BA_ "GenSigTimeoutTime_ALL" SG_ 897 ALV_ACM_SEAT_OCCUPATION 1000;
BA_ "InvalidValue" SG_ 897 ALV_ACM_SEAT_OCCUPATION "Fh";
BA_ "GenSigTimeoutTime_ALL" SG_ 897 ACM_Seat_Occupancy_Passenger 1000;
BA_ "InvalidValue" SG_ 897 ACM_Seat_Occupancy_Passenger "null";
BA_ "GenSigTimeoutTime_ALL" SG_ 897 ACM_Seat_Occupancy_2nd_Row_Dri 1000;
BA_ "InvalidValue" SG_ 897 ACM_Seat_Occupancy_2nd_Row_Dri "null";
BA_ "GenSigTimeoutTime_ALL" SG_ 897 ACM_Seat_Occupancy_2nd_Row_Pas 1000;
BA_ "InvalidValue" SG_ 897 ACM_Seat_Occupancy_2nd_Row_Pas "null";
BA_ "GenSigTimeoutTime_ALL" SG_ 897 ACM_Seat_Occupancy_2nd_Row_Mid 1000;
BA_ "InvalidValue" SG_ 897 ACM_Seat_Occupancy_2nd_Row_Mid "null";
BA_ "GenSigTimeoutTime_ALL" SG_ 897 ACM_Seat_Belt_Status_Passenger 1000;
BA_ "InvalidValue" SG_ 897 ACM_Seat_Belt_Status_Passenger "null";
BA_ "GenSigTimeoutTime_ALL" SG_ 897 ACM_Seat_Belt_Status_Driver 1000;
BA_ "InvalidValue" SG_ 897 ACM_Seat_Belt_Status_Driver "null";
BA_ "GenSigTimeoutTime_ALL" SG_ 897 ACM_Seat_Belt_Status_2nd_Row_Dri 1000;
BA_ "InvalidValue" SG_ 897 ACM_Seat_Belt_Status_2nd_Row_Dri "null";
BA_ "GenSigTimeoutTime_ALL" SG_ 897 ACM_Seat_Belt_Status_2nd_Row_Mid 1000;
BA_ "InvalidValue" SG_ 897 ACM_Seat_Belt_Status_2nd_Row_Mid "null";
BA_ "GenSigTimeoutTime_ALL" SG_ 897 ACM_Seat_Belt_Status_2nd_Row_Pas 1000;
BA_ "InvalidValue" SG_ 897 ACM_Seat_Belt_Status_2nd_Row_Pas "null";
BA_ "GenSigSendType" SG_ 905 VCU_IMMO_Sts 1;
BA_ "InvalidValue" SG_ 905 VCU_IMMO_Sts "null";
BA_ "GenSigSendType" SG_ 905 SECCAN_VCU_IMMO_Sts 1;
BA_ "InvalidValue" SG_ 905 SECCAN_VCU_IMMO_Sts "null";
BA_ "GenSigSendType" SG_ 920 BCM_Immo_Byte_0 1;
BA_ "InvalidValue" SG_ 920 BCM_Immo_Byte_0 "null";
BA_ "GenSigSendType" SG_ 920 BCM_Immo_Byte_1 1;
BA_ "InvalidValue" SG_ 920 BCM_Immo_Byte_1 "null";
BA_ "GenSigSendType" SG_ 920 BCM_Immo_Byte_2 1;
BA_ "InvalidValue" SG_ 920 BCM_Immo_Byte_2 "null";
BA_ "GenSigSendType" SG_ 920 BCM_Immo_Byte_3 1;
BA_ "InvalidValue" SG_ 920 BCM_Immo_Byte_3 "null";
BA_ "GenSigSendType" SG_ 920 BCM_Immo_Byte_4 1;
BA_ "InvalidValue" SG_ 920 BCM_Immo_Byte_4 "null";
BA_ "GenSigSendType" SG_ 920 BCM_Immo_Byte_5 1;
BA_ "InvalidValue" SG_ 920 BCM_Immo_Byte_5 "null";
BA_ "GenSigSendType" SG_ 920 BCM_Immo_Byte_6 1;
BA_ "InvalidValue" SG_ 920 BCM_Immo_Byte_6 "null";
BA_ "GenSigSendType" SG_ 920 BCM_Immo_Byte_7 1;
BA_ "InvalidValue" SG_ 920 BCM_Immo_Byte_7 "null";
BA_ "GenSigSendType" SG_ 921 VCU_Immo_Byte_0 1;
BA_ "InvalidValue" SG_ 921 VCU_Immo_Byte_0 "null";
BA_ "GenSigSendType" SG_ 921 VCU_Immo_Byte_1 1;
BA_ "InvalidValue" SG_ 921 VCU_Immo_Byte_1 "null";
BA_ "GenSigSendType" SG_ 921 VCU_Immo_Byte_2 1;
BA_ "InvalidValue" SG_ 921 VCU_Immo_Byte_2 "null";
BA_ "GenSigSendType" SG_ 921 VCU_Immo_Byte_3 1;
BA_ "InvalidValue" SG_ 921 VCU_Immo_Byte_3 "null";
BA_ "GenSigSendType" SG_ 921 VCU_Immo_Byte_4 1;
BA_ "InvalidValue" SG_ 921 VCU_Immo_Byte_4 "null";
BA_ "GenSigSendType" SG_ 921 VCU_Immo_Byte_5 1;
BA_ "InvalidValue" SG_ 921 VCU_Immo_Byte_5 "null";
BA_ "GenSigSendType" SG_ 921 VCU_Immo_Byte_6 1;
BA_ "InvalidValue" SG_ 921 VCU_Immo_Byte_6 "null";
BA_ "GenSigSendType" SG_ 921 VCU_Immo_Byte_7 1;
BA_ "InvalidValue" SG_ 921 VCU_Immo_Byte_7 "null";
BA_ "GenSigSendType" SG_ 922 MHU_Immo_Byte_0 2;
BA_ "InvalidValue" SG_ 922 MHU_Immo_Byte_0 "null";
BA_ "GenSigSendType" SG_ 922 MHU_Immo_Byte_1 2;
BA_ "InvalidValue" SG_ 922 MHU_Immo_Byte_1 "null";
BA_ "GenSigSendType" SG_ 922 MHU_Immo_Byte_2 2;
BA_ "InvalidValue" SG_ 922 MHU_Immo_Byte_2 "null";
BA_ "GenSigSendType" SG_ 922 MHU_Immo_Byte_3 2;
BA_ "InvalidValue" SG_ 922 MHU_Immo_Byte_3 "null";
BA_ "GenSigSendType" SG_ 922 MHU_Immo_Byte_4 2;
BA_ "InvalidValue" SG_ 922 MHU_Immo_Byte_4 "null";
BA_ "GenSigSendType" SG_ 922 MHU_Immo_Byte_5 2;
BA_ "InvalidValue" SG_ 922 MHU_Immo_Byte_5 "null";
BA_ "GenSigSendType" SG_ 922 MHU_Immo_Byte_6 2;
BA_ "InvalidValue" SG_ 922 MHU_Immo_Byte_6 "null";
BA_ "GenSigSendType" SG_ 922 MHU_Immo_Byte_7 2;
BA_ "InvalidValue" SG_ 922 MHU_Immo_Byte_7 "null";
BA_ "GenSigSendType" SG_ 923 BCM_Immo_MHU_Byte_0 2;
BA_ "InvalidValue" SG_ 923 BCM_Immo_MHU_Byte_0 "null";
BA_ "GenSigSendType" SG_ 923 BCM_Immo_MHU_Byte_1 2;
BA_ "InvalidValue" SG_ 923 BCM_Immo_MHU_Byte_1 "null";
BA_ "GenSigSendType" SG_ 923 BCM_Immo_MHU_Byte_2 2;
BA_ "InvalidValue" SG_ 923 BCM_Immo_MHU_Byte_2 "null";
BA_ "GenSigSendType" SG_ 923 BCM_Immo_MHU_Byte_3 2;
BA_ "InvalidValue" SG_ 923 BCM_Immo_MHU_Byte_3 "null";
BA_ "GenSigSendType" SG_ 923 BCM_Immo_MHU_Byte_4 2;
BA_ "InvalidValue" SG_ 923 BCM_Immo_MHU_Byte_4 "null";
BA_ "GenSigSendType" SG_ 923 BCM_Immo_MHU_Byte_5 2;
BA_ "InvalidValue" SG_ 923 BCM_Immo_MHU_Byte_5 "null";
BA_ "GenSigSendType" SG_ 923 BCM_Immo_MHU_Byte_6 2;
BA_ "InvalidValue" SG_ 923 BCM_Immo_MHU_Byte_6 "null";
BA_ "GenSigSendType" SG_ 923 BCM_Immo_MHU_Byte_7 2;
BA_ "InvalidValue" SG_ 923 BCM_Immo_MHU_Byte_7 "null";
BA_ "GenSigTimeoutTime_ALL" SG_ 925 CHKSM_BCM_HighBeam_PosReq 500;
BA_ "InvalidValue" SG_ 925 ALIVE_BCM_HighBeam_PosReq "Fh";
BA_ "GenSigTimeoutTime_ALL" SG_ 925 ALIVE_BCM_HighBeam_PosReq 500;
BA_ "InvalidValue" SG_ 925 BCM_ADAS_AHB_state "3h";
BA_ "GenSigTimeoutTime_ALL" SG_ 925 BCM_ADAS_AHB_state 500;
BA_ "GenSigTimeoutTime_ALL" SG_ 925 BCM_AHB_Override 500;
BA_ "InvalidValue" SG_ 925 BCM_AHB_Override "3h";
BA_ "GenSigTimeoutTime_ALL" SG_ 925 BCM_ADAS_AHB_RBPos_feed 500;
BA_ "InvalidValue" SG_ 925 BCM_ADAS_AHB_RBPos_feed "null";
BA_ "GenSigTimeoutTime_ALL" SG_ 925 BCM_ADAS_AHB_LBPos_feed 500;
BA_ "InvalidValue" SG_ 925 BCM_ADAS_AHB_LBPos_feed "null";
BA_ "InvalidValue" SG_ 925 BCM_AHB_ICON_Feed "7h";
BA_ "GenSigTimeoutTime_ALL" SG_ 925 BCM_AHB_ICON_Feed 500;
BA_ "GenSigTimeoutTime_ALL" SG_ 993 CRC_VCU_HMI_Info 500;
BA_ "GenSigTimeoutTime_ALL" SG_ 993 ALIV_VCU_HMI_Info 500;
BA_ "InvalidValue" SG_ 993 ALIV_VCU_HMI_Info "Fh";
BA_ "GenSigTimeoutTime_ALL" SG_ 993 VCU_CruiseCtrlSts 500;
BA_ "GenSigSendType" SG_ 1015 CHSKM_MFS_Control_Button 4;
BA_ "GenSigTimeoutTime_ALL" SG_ 1015 CHSKM_MFS_Control_Button 5000;
BA_ "InvalidValue" SG_ 1015 CHSKM_MFS_Control_Button "null";
BA_ "GenSigSendType" SG_ 1015 ALV_MFS_Control_Button 4;
BA_ "GenSigTimeoutTime_ALL" SG_ 1015 ALV_MFS_Control_Button 5000;
BA_ "InvalidValue" SG_ 1015 ALV_MFS_Control_Button "Fh";
BA_ "GenSigSendType" SG_ 1015 MFS_VoiceRecognitionOn_Off 4;
BA_ "GenSigTimeoutTime_ALL" SG_ 1015 MFS_VoiceRecognitionOn_Off 5000;
BA_ "InvalidValue" SG_ 1015 MFS_VoiceRecognitionOn_Off "4h";
BA_ "GenSigSendType" SG_ 1015 MFS_ISAControl 4;
BA_ "GenSigTimeoutTime_ALL" SG_ 1015 MFS_ISAControl 5000;
BA_ "InvalidValue" SG_ 1015 MFS_ISAControl "3h";
BA_ "GenSigSendType" SG_ 1015 MFS_CruiseSpeedIncrease 4;
BA_ "GenSigTimeoutTime_ALL" SG_ 1015 MFS_CruiseSpeedIncrease 5000;
BA_ "InvalidValue" SG_ 1015 MFS_CruiseSpeedIncrease "4h";
BA_ "GenSigSendType" SG_ 1015 MFS_TelephoneCall_EndCall 4;
BA_ "GenSigTimeoutTime_ALL" SG_ 1015 MFS_TelephoneCall_EndCall 5000;
BA_ "InvalidValue" SG_ 1015 MFS_TelephoneCall_EndCall "4h";
BA_ "GenSigSendType" SG_ 1015 MFS_LKAControl 4;
BA_ "GenSigTimeoutTime_ALL" SG_ 1015 MFS_LKAControl 5000;
BA_ "InvalidValue" SG_ 1015 MFS_LKAControl "3h";
BA_ "GenSigSendType" SG_ 1015 MFS_CruiseGapIncrease 4;
BA_ "GenSigTimeoutTime_ALL" SG_ 1015 MFS_CruiseGapIncrease 5000;
BA_ "InvalidValue" SG_ 1015 MFS_CruiseGapIncrease "4h";
BA_ "GenSigSendType" SG_ 1015 MFS_CruiseOn_Off 4;
BA_ "GenSigTimeoutTime_ALL" SG_ 1015 MFS_CruiseOn_Off 5000;
BA_ "InvalidValue" SG_ 1015 MFS_CruiseOn_Off "4h";
BA_ "GenSigSendType" SG_ 1015 MFS_CruiseGapDecrease 4;
BA_ "GenSigTimeoutTime_ALL" SG_ 1015 MFS_CruiseGapDecrease 5000;
BA_ "InvalidValue" SG_ 1015 MFS_CruiseGapDecrease "4h";
BA_ "GenSigSendType" SG_ 1015 MFS_CAN_RESControl 4;
BA_ "GenSigTimeoutTime_ALL" SG_ 1015 MFS_CAN_RESControl 5000;
BA_ "InvalidValue" SG_ 1015 MFS_CAN_RESControl "3h";
BA_ "GenSigSendType" SG_ 1015 MFS_CruiseSpeedDecrease 4;
BA_ "GenSigTimeoutTime_ALL" SG_ 1015 MFS_CruiseSpeedDecrease 5000;
BA_ "InvalidValue" SG_ 1015 MFS_CruiseSpeedDecrease "4h";
BA_ "GenSigSendType" SG_ 1015 MFS_M2Control 4;
BA_ "GenSigTimeoutTime_ALL" SG_ 1015 MFS_M2Control 5000;
BA_ "InvalidValue" SG_ 1015 MFS_M2Control "3h";
BA_ "GenSigSendType" SG_ 1015 MFS_SourseControl 4;
BA_ "GenSigTimeoutTime_ALL" SG_ 1015 MFS_SourseControl 5000;
BA_ "InvalidValue" SG_ 1015 MFS_SourseControl "4h";
BA_ "GenSigSendType" SG_ 1015 MFS_UpControl 4;
BA_ "GenSigTimeoutTime_ALL" SG_ 1015 MFS_UpControl 5000;
BA_ "InvalidValue" SG_ 1015 MFS_UpControl "4h";
BA_ "GenSigSendType" SG_ 1015 MFS_DownControl 4;
BA_ "GenSigTimeoutTime_ALL" SG_ 1015 MFS_DownControl 5000;
BA_ "InvalidValue" SG_ 1015 MFS_DownControl "4h";
BA_ "GenSigSendType" SG_ 1015 MFS_LeftControl 4;
BA_ "GenSigTimeoutTime_ALL" SG_ 1015 MFS_LeftControl 5000;
BA_ "InvalidValue" SG_ 1015 MFS_LeftControl "4h";
BA_ "GenSigSendType" SG_ 1015 MFS_Failure 4;
BA_ "GenSigTimeoutTime_ALL" SG_ 1015 MFS_Failure 5000;
BA_ "InvalidValue" SG_ 1015 MFS_Failure "null";
BA_ "GenSigSendType" SG_ 1015 MFS_RightControl 4;
BA_ "GenSigTimeoutTime_ALL" SG_ 1015 MFS_RightControl 5000;
BA_ "InvalidValue" SG_ 1015 MFS_RightControl "4h";
BA_ "GenSigSendType" SG_ 1015 MFS_OK_Control 4;
BA_ "GenSigTimeoutTime_ALL" SG_ 1015 MFS_OK_Control 5000;
BA_ "InvalidValue" SG_ 1015 MFS_OK_Control "4h";
BA_ "GenSigSendType" SG_ 1025 MHU_SET_SunroofGlassLevel 2;
BA_ "GenSigStartValue" SG_ 1025 MHU_SET_SunroofGlassLevel 255;
BA_ "InvalidValue" SG_ 1025 MHU_SET_SunroofGlassLevel "7Fh";
BA_ "GenSigSendType" SG_ 1025 MHU_SET_BonnetState 2;
BA_ "InvalidValue" SG_ 1025 MHU_SET_BonnetState "3h";
BA_ "GenSigSendType" SG_ 1025 MHU_SET_TrunkState 2;
BA_ "InvalidValue" SG_ 1025 MHU_SET_TrunkState "3h";
BA_ "GenSigSendType" SG_ 1025 MHU_SET_SunroofShaderLevel 2;
BA_ "GenSigStartValue" SG_ 1025 MHU_SET_SunroofShaderLevel 255;
BA_ "InvalidValue" SG_ 1025 MHU_SET_SunroofShaderLevel "7Fh";
BA_ "GenSigSendType" SG_ 1025 MHU_SET_DoorSpeedLock 2;
BA_ "GenSigStartValue" SG_ 1025 MHU_SET_DoorSpeedLock 6;
BA_ "InvalidValue" SG_ 1025 MHU_SET_DoorSpeedLock "6h";
BA_ "GenSigSendType" SG_ 1025 MHU_SET_WelcomeTriggerCondition 2;
BA_ "GenSigStartValue" SG_ 1025 MHU_SET_WelcomeTriggerCondition 3;
BA_ "InvalidValue" SG_ 1025 MHU_SET_WelcomeTriggerCondition "3h";
BA_ "GenSigSendType" SG_ 1025 MHU_SET_AutoSunroof 2;
BA_ "GenSigStartValue" SG_ 1025 MHU_SET_AutoSunroof 3;
BA_ "InvalidValue" SG_ 1025 MHU_SET_AutoSunroof "3h";
BA_ "GenSigSendType" SG_ 1025 MHU_SET_RemoteDoorUnlock 2;
BA_ "GenSigStartValue" SG_ 1025 MHU_SET_RemoteDoorUnlock 3;
BA_ "InvalidValue" SG_ 1025 MHU_SET_RemoteDoorUnlock "3h";
BA_ "GenSigSendType" SG_ 1025 MHU_SET_RemoteLockFeedback 2;
BA_ "GenSigStartValue" SG_ 1025 MHU_SET_RemoteLockFeedback 4;
BA_ "InvalidValue" SG_ 1025 MHU_SET_RemoteLockFeedback "4h";
BA_ "GenSigSendType" SG_ 1025 MHU_SET_FootkickSensor 2;
BA_ "GenSigStartValue" SG_ 1025 MHU_SET_FootkickSensor 3;
BA_ "InvalidValue" SG_ 1025 MHU_SET_FootkickSensor "3h";
BA_ "GenSigSendType" SG_ 1025 MHU_SET_AutoUnlockDoor 2;
BA_ "GenSigStartValue" SG_ 1025 MHU_SET_AutoUnlockDoor 3;
BA_ "InvalidValue" SG_ 1025 MHU_SET_AutoUnlockDoor "3h";
BA_ "GenSigSendType" SG_ 1025 MHU_SET_RemoteUnlockFeedback 2;
BA_ "GenSigStartValue" SG_ 1025 MHU_SET_RemoteUnlockFeedback 4;
BA_ "InvalidValue" SG_ 1025 MHU_SET_RemoteUnlockFeedback "4h";
BA_ "GenSigSendType" SG_ 1025 MHU_SET_Childlock 2;
BA_ "InvalidValue" SG_ 1025 MHU_SET_Childlock "null";
BA_ "GenSigSendType" SG_ 1025 MHU_SET_SunroofInitialize 2;
BA_ "InvalidValue" SG_ 1025 MHU_SET_SunroofInitialize "7h";
BA_ "GenSigSendType" SG_ 1025 WalkawayDoorLock 2;
BA_ "GenSigSendType" SG_ 1026 MHU_SET_DayTimeRunningLight 2;
BA_ "GenSigStartValue" SG_ 1026 MHU_SET_DayTimeRunningLight 1;
BA_ "InvalidValue" SG_ 1026 MHU_SET_DayTimeRunningLight "3h";
BA_ "GenSigSendType" SG_ 1026 MHU_SET_RearFogLight 2;
BA_ "GenSigStartValue" SG_ 1026 MHU_SET_RearFogLight 3;
BA_ "InvalidValue" SG_ 1026 MHU_SET_RearFogLight "3h";
BA_ "GenSigSendType" SG_ 1026 MHU_SET_FrontFogLight 2;
BA_ "GenSigStartValue" SG_ 1026 MHU_SET_FrontFogLight 3;
BA_ "InvalidValue" SG_ 1026 MHU_SET_FrontFogLight "3h";
BA_ "GenSigSendType" SG_ 1026 MHU_SET_WelcomeDimmingHeadlight 2;
BA_ "GenSigStartValue" SG_ 1026 MHU_SET_WelcomeDimmingHeadlight 3;
BA_ "InvalidValue" SG_ 1026 MHU_SET_WelcomeDimmingHeadlight "3h";
BA_ "GenSigSendType" SG_ 1026 MHU_SET_AmbientLightBrighness 2;
BA_ "InvalidValue" SG_ 1026 MHU_SET_AmbientLightBrighness "7Fh";
BA_ "GenSigSendType" SG_ 1026 MHU_SET_FootwellLightMode 2;
BA_ "GenSigStartValue" SG_ 1026 MHU_SET_FootwellLightMode 2;
BA_ "InvalidValue" SG_ 1026 MHU_SET_FootwellLightMode "3h";
BA_ "GenSigSendType" SG_ 1026 MHU_SET_ExteriorLight 2;
BA_ "GenSigStartValue" SG_ 1026 MHU_SET_ExteriorLight 4;
BA_ "InvalidValue" SG_ 1026 MHU_SET_ExteriorLight "4h";
BA_ "GenSigSendType" SG_ 1026 MHU_SET_TRWarningSignals 2;
BA_ "GenSigStartValue" SG_ 1026 MHU_SET_TRWarningSignals 3;
BA_ "InvalidValue" SG_ 1026 MHU_SET_TRWarningSignals "3h";
BA_ "GenSigSendType" SG_ 1026 MHU_SET_FrontDomeLamp 2;
BA_ "GenSigStartValue" SG_ 1026 MHU_SET_FrontDomeLamp 3;
BA_ "InvalidValue" SG_ 1026 MHU_SET_FrontDomeLamp "3h";
BA_ "GenSigSendType" SG_ 1026 MHU_SET_SwitchLightBrightness 2;
BA_ "GenSigStartValue" SG_ 1026 MHU_SET_SwitchLightBrightness 80;
BA_ "InvalidValue" SG_ 1026 MHU_SET_SwitchLightBrightness "4h";
BA_ "GenSigSendType" SG_ 1026 MHU_SET_HazardLight 2;
BA_ "InvalidValue" SG_ 1026 MHU_SET_HazardLight "3h";
BA_ "GenSigTimeoutTime_ALL" SG_ 1026 MHU_SET_HazardLight 500;
BA_ "GenSigSendType" SG_ 1026 MHU_SET_FollowMeHome 2;
BA_ "InvalidValue" SG_ 1026 MHU_SET_FollowMeHome "5h";
BA_ "GenSigSendType" SG_ 1026 MHU_SET_ADB_AHB 2;
BA_ "InvalidValue" SG_ 1026 MHU_SET_ADB_AHB "3h";
BA_ "GenSigSendType" SG_ 1026 MHU_SET_WelcomeAnimation 2;
BA_ "InvalidValue" SG_ 1026 MHU_SET_WelcomeAnimation "null";
BA_ "GenSigSendType" SG_ 1026 MHU_SET_ChargingAnimation 2;
BA_ "GenSigStartValue" SG_ 1026 MHU_SET_ChargingAnimation 1;
BA_ "InvalidValue" SG_ 1026 MHU_SET_ChargingAnimation "3h";
BA_ "GenSigSendType" SG_ 1026 MHU_SET_Auto_Leveling 2;
BA_ "GenSigStartValue" SG_ 1026 MHU_SET_Auto_Leveling 1;
BA_ "InvalidValue" SG_ 1026 MHU_SET_Auto_Leveling "3h";
BA_ "GenSigTimeoutTime_ALL" SG_ 1027 CHKSM_MHU_EVSetting 500;
BA_ "InvalidValue" SG_ 1027 CHKSM_MHU_EVSetting "null";
BA_ "GenSigTimeoutTime_ALL" SG_ 1027 ALV_MHU_EVSetting 500;
BA_ "InvalidValue" SG_ 1027 ALV_MHU_EVSetting "Fh";
BA_ "GenSigTimeoutTime_ALL" SG_ 1027 MHU_VCU_CreepDisable_stt 500;
BA_ "InvalidValue" SG_ 1027 MHU_VCU_CreepDisable_stt "null";
BA_ "GenSigTimeoutTime_ALL" SG_ 1027 MHU_BrakeRegenMode 500;
BA_ "GenSigStartValue" SG_ 1027 MHU_ChargeSetTargetSOC 80;
BA_ "GenSigTimeoutTime_ALL" SG_ 1027 MHU_ChargeSetTargetSOC 500;
BA_ "InvalidValue" SG_ 1027 MHU_ChargeSetTargetSOC "7Fh";
BA_ "GenSigStartValue" SG_ 1027 MHU_ChargeScheduleSet 2;
BA_ "GenSigTimeoutTime_ALL" SG_ 1027 MHU_ChargeScheduleSet 500;
BA_ "InvalidValue" SG_ 1027 MHU_ChargeScheduleSet "3h";
BA_ "GenSigStartValue" SG_ 1027 MHU_ChargingRequest 3;
BA_ "GenSigTimeoutTime_ALL" SG_ 1027 MHU_ChargingRequest 500;
BA_ "InvalidValue" SG_ 1027 MHU_ChargingRequest "null";
BA_ "GenSigTimeoutTime_ALL" SG_ 1027 MHU_ChgPort_Open_req 500;
BA_ "InvalidValue" SG_ 1027 MHU_ChgPort_Open_req "3h";
BA_ "GenSigStartValue" SG_ 1027 MHU_SET_DrivingModeSwitch 3;
BA_ "GenSigTimeoutTime_ALL" SG_ 1027 MHU_SET_DrivingModeSwitch 500;
BA_ "InvalidValue" SG_ 1027 MHU_SET_DrivingModeSwitch "3h";
BA_ "GenSigStartValue" SG_ 1027 MHU_ValetMode_Activation 2;
BA_ "GenSigTimeoutTime_ALL" SG_ 1027 MHU_ValetMode_Activation 500;
BA_ "InvalidValue" SG_ 1027 MHU_ValetMode_Activation "FFh";
BA_ "GenSigStartValue" SG_ 1027 MHU_ValetMode_MaxSpeed 255;
BA_ "GenSigTimeoutTime_ALL" SG_ 1027 MHU_ValetMode_MaxSpeed 500;
BA_ "InvalidValue" SG_ 1027 MHU_ValetMode_MaxSpeed "FFh";
BA_ "GenSigStartValue" SG_ 1027 MHU_ChargingCurrentLimit 6;
BA_ "GenSigTimeoutTime_ALL" SG_ 1027 MHU_ChargingCurrentLimit 500;
BA_ "InvalidValue" SG_ 1027 MHU_ChargingCurrentLimit "3Fh";
BA_ "GenSigSendType" SG_ 1028 MHU_SET_LeftMirrorPosX 2;
BA_ "GenSigStartValue" SG_ 1028 MHU_SET_LeftMirrorPosX 15;
BA_ "InvalidValue" SG_ 1028 MHU_SET_LeftMirrorPosX "FFh";
BA_ "GenSigSendType" SG_ 1028 MHU_SET_LeftMirrorPosY 2;
BA_ "GenSigStartValue" SG_ 1028 MHU_SET_LeftMirrorPosY 15;
BA_ "InvalidValue" SG_ 1028 MHU_SET_LeftMirrorPosY "FFh";
BA_ "GenSigSendType" SG_ 1028 MHU_SET_RightMirrorPosX 2;
BA_ "GenSigStartValue" SG_ 1028 MHU_SET_RightMirrorPosX 15;
BA_ "InvalidValue" SG_ 1028 MHU_SET_RightMirrorPosX "FFh";
BA_ "GenSigSendType" SG_ 1028 MHU_SET_RightMirrorPosY 2;
BA_ "GenSigStartValue" SG_ 1028 MHU_SET_RightMirrorPosY 15;
BA_ "InvalidValue" SG_ 1028 MHU_SET_RightMirrorPosY "FFh";
BA_ "GenSigSendType" SG_ 1028 MHU_SET_MirrorAdjustLeft 2;
BA_ "InvalidValue" SG_ 1028 MHU_SET_MirrorAdjustLeft "3h";
BA_ "GenSigSendType" SG_ 1028 MHU_SET_MirrorAdjustRight 2;
BA_ "InvalidValue" SG_ 1028 MHU_SET_MirrorAdjustRight "3h";
BA_ "GenSigSendType" SG_ 1028 MHU_SET_MirrorManual 2;
BA_ "GenSigStartValue" SG_ 1028 MHU_SET_MirrorManual 3;
BA_ "InvalidValue" SG_ 1028 MHU_SET_MirrorManual "3h";
BA_ "GenSigSendType" SG_ 1028 SECCAN_MirrorAdj 2;
BA_ "InvalidValue" SG_ 1028 SECCAN_MirrorAdj "null";
BA_ "GenSigSendType" SG_ 1029 MHU_SET_CCUF_AirCondition 2;
BA_ "InvalidValue" SG_ 1029 MHU_SET_CCUF_AirCondition "3h";
BA_ "GenSigSendType" SG_ 1029 MHU_SET_CCUF_AutoAC 2;
BA_ "InvalidValue" SG_ 1029 MHU_SET_CCUF_AutoAC "3h";
BA_ "GenSigSendType" SG_ 1029 MHU_SET_CCUF_MaxAc 2;
BA_ "InvalidValue" SG_ 1029 MHU_SET_CCUF_MaxAc "3h";
BA_ "GenSigSendType" SG_ 1029 MHU_SET_CCUF_FanSpeed 2;
BA_ "GenSigStartValue" SG_ 1029 MHU_SET_CCUF_FanSpeed 3;
BA_ "InvalidValue" SG_ 1029 MHU_SET_CCUF_FanSpeed "7h";
BA_ "GenSigSendType" SG_ 1029 MHU_SET_CCUF_Recirculation 2;
BA_ "GenSigStartValue" SG_ 1029 MHU_SET_CCUF_Recirculation 1;
BA_ "InvalidValue" SG_ 1029 MHU_SET_CCUF_Recirculation "3h";
BA_ "GenSigSendType" SG_ 1029 MHU_SET_CCUF_Ion 2;
BA_ "InvalidValue" SG_ 1029 MHU_SET_CCUF_Ion "3h";
BA_ "GenSigSendType" SG_ 1029 MHU_SET_CCUF_FlapPosition 2;
BA_ "InvalidValue" SG_ 1029 MHU_SET_CCUF_FlapPosition "4h";
BA_ "GenSigSendType" SG_ 1029 MHU_SET_CCUF_SyncClimateZone 2;
BA_ "InvalidValue" SG_ 1029 MHU_SET_CCUF_SyncClimateZone "3h";
BA_ "GenSigSendType" SG_ 1029 MHU_SET_CCUF_TempDriver 2;
BA_ "GenSigStartValue" SG_ 1029 MHU_SET_CCUF_TempDriver 40;
BA_ "InvalidValue" SG_ 1029 MHU_SET_CCUF_TempDriver "FFh";
BA_ "GenSigSendType" SG_ 1029 MHU_SET_CCUF_TempPassenger 2;
BA_ "GenSigStartValue" SG_ 1029 MHU_SET_CCUF_TempPassenger 40;
BA_ "InvalidValue" SG_ 1029 MHU_SET_CCUF_TempPassenger "FFh";
BA_ "GenSigSendType" SG_ 1029 MHU_SET_CCUF_FrontDefrost 2;
BA_ "InvalidValue" SG_ 1029 MHU_SET_CCUF_FrontDefrost "3h";
BA_ "GenSigSendType" SG_ 1030 MHU_SET_SeatHeatingFrontL 2;
BA_ "InvalidValue" SG_ 1030 MHU_SET_SeatHeatingFrontL "4h";
BA_ "GenSigSendType" SG_ 1030 MHU_SET_SeatHeatingFrontR 2;
BA_ "InvalidValue" SG_ 1030 MHU_SET_SeatHeatingFrontR "4h";
BA_ "GenSigSendType" SG_ 1030 MHU_SET_SeatHeatingReartL 2;
BA_ "InvalidValue" SG_ 1030 MHU_SET_SeatHeatingReartL "4h";
BA_ "GenSigSendType" SG_ 1030 MHU_SET_SeatHeatingRearR 2;
BA_ "InvalidValue" SG_ 1030 MHU_SET_SeatHeatingRearR "4h";
BA_ "GenSigSendType" SG_ 1030 MHU_SET_SeatCoolingFrontL 2;
BA_ "InvalidValue" SG_ 1030 MHU_SET_SeatCoolingFrontL "4h";
BA_ "GenSigSendType" SG_ 1030 MHU_SET_SeatCoolingFrontR 2;
BA_ "InvalidValue" SG_ 1030 MHU_SET_SeatCoolingFrontR "4h";
BA_ "GenSigSendType" SG_ 1030 MHU_SET_SeatCoolingRearL 2;
BA_ "InvalidValue" SG_ 1030 MHU_SET_SeatCoolingRearL "4h";
BA_ "GenSigSendType" SG_ 1030 MHU_SET_SeatCoolingRearR 2;
BA_ "InvalidValue" SG_ 1030 MHU_SET_SeatCoolingRearR "4h";
BA_ "GenSigSendType" SG_ 1032 MHU_SET_MirrorAuto 2;
BA_ "GenSigStartValue" SG_ 1032 MHU_SET_MirrorAuto 3;
BA_ "InvalidValue" SG_ 1032 MHU_SET_MirrorAuto "3h";
BA_ "GenSigSendType" SG_ 1032 MHU_SET_MirrorAutoUnfold 2;
BA_ "GenSigStartValue" SG_ 1032 MHU_SET_MirrorAutoUnfold 3;
BA_ "InvalidValue" SG_ 1032 MHU_SET_MirrorAutoUnfold "3h";
BA_ "GenSigSendType" SG_ 1032 MHU_SET_WLC 2;
BA_ "GenSigStartValue" SG_ 1032 MHU_SET_WLC 3;
BA_ "InvalidValue" SG_ 1032 MHU_SET_WLC "3h";
BA_ "GenSigSendType" SG_ 1032 MHU_SET_AutoRearWiper 2;
BA_ "GenSigStartValue" SG_ 1032 MHU_SET_AutoRearWiper 3;
BA_ "InvalidValue" SG_ 1032 MHU_SET_AutoRearWiper "3h";
BA_ "GenSigSendType" SG_ 1032 MHU_SET_RearHeatedWindow 2;
BA_ "InvalidValue" SG_ 1032 MHU_SET_RearHeatedWindow "3h";
BA_ "GenSigSendType" SG_ 1032 MHU_TPMSReset 2;
BA_ "InvalidValue" SG_ 1032 MHU_TPMSReset "3h";
BA_ "GenSigSendType" SG_ 1032 MHU_SET_MirrorDefaultSetting 2;
BA_ "GenSigStartValue" SG_ 1032 MHU_SET_MirrorDefaultSetting 3;
BA_ "InvalidValue" SG_ 1032 MHU_SET_MirrorDefaultSetting "3h";
BA_ "GenSigSendType" SG_ 1032 MHU_SET_MirrorReverseLink 2;
BA_ "GenSigSendType" SG_ 1032 MHU_SET_AntiTheftMode 2;
BA_ "GenSigStartValue" SG_ 1032 MHU_SET_AntiTheftMode 3;
BA_ "InvalidValue" SG_ 1032 MHU_SET_AntiTheftMode "3h";
BA_ "GenSigSendType" SG_ 1032 MHU_SET_WLCReminder 2;
BA_ "GenSigStartValue" SG_ 1032 MHU_SET_WLCReminder 1;
BA_ "InvalidValue" SG_ 1032 MHU_SET_WLCReminder "3h";
BA_ "GenSigSendType" SG_ 1032 MHU_SET_ClimateKeepOn 2;
BA_ "InvalidValue" SG_ 1032 MHU_SET_ClimateKeepOn "null";
BA_ "GenSigSendType" SG_ 1032 MHU_SET_WLC2 2;
BA_ "GenSigStartValue" SG_ 1032 MHU_SET_WLC2 1;
BA_ "InvalidValue" SG_ 1032 MHU_SET_WLC2 "3h";
BA_ "GenSigSendType" SG_ 1032 MHU_SET_WLC2Reminder 2;
BA_ "GenSigStartValue" SG_ 1032 MHU_SET_WLC2Reminder 1;
BA_ "InvalidValue" SG_ 1032 MHU_SET_WLC2Reminder "3h";
BA_ "GenSigSendType" SG_ 1032 MHU_IntrusionAlertStatus 2;
BA_ "GenSigStartValue" SG_ 1032 MHU_IntrusionAlertStatus 3;
BA_ "InvalidValue" SG_ 1032 MHU_IntrusionAlertStatus "3h";
BA_ "GenSigTimeoutTime_ALL" SG_ 1036 CHSKM_MHU_SEAT_CONTROL 1000;
BA_ "InvalidValue" SG_ 1036 CHSKM_MHU_SEAT_CONTROL "null";
BA_ "GenSigTimeoutTime_ALL" SG_ 1036 ALV_MHU_SEAT_CONTROL 1000;
BA_ "InvalidValue" SG_ 1036 ALV_MHU_SEAT_CONTROL "Fh";
BA_ "GenSigTimeoutTime_ALL" SG_ 1036 MHU_DrvSeat_Control_Status 1000;
BA_ "InvalidValue" SG_ 1036 MHU_DrvSeat_Control_Status "7h";
BA_ "GenSigTimeoutTime_ALL" SG_ 1036 MHU_ExpDrvReclinerPos 1000;
BA_ "InvalidValue" SG_ 1036 MHU_ExpDrvReclinerPos "7Fh";
BA_ "GenSigTimeoutTime_ALL" SG_ 1036 MHU_ExpDrvTiltPos 1000;
BA_ "InvalidValue" SG_ 1036 MHU_ExpDrvTiltPos "1Fh";
BA_ "GenSigTimeoutTime_ALL" SG_ 1036 MHU_ExpDrvTrackPos 1000;
BA_ "InvalidValue" SG_ 1036 MHU_ExpDrvTrackPos "FFh";
BA_ "GenSigTimeoutTime_ALL" SG_ 1036 MHU_ExpDrvHeightPos 1000;
BA_ "InvalidValue" SG_ 1036 MHU_ExpDrvHeightPos "3Fh";
BA_ "GenSigTimeoutTime_ALL" SG_ 1037 CHKSM_MHU_DIGIT_SPEED 1500;
BA_ "GenSigTimeoutTime_ALL" SG_ 1037 ALV_MHU_DIGIT_SPEED 1500;
BA_ "InvalidValue" SG_ 1037 ALV_MHU_DIGIT_SPEED "Fh";
BA_ "GenSigTimeoutTime_ALL" SG_ 1037 MHU_DigitSpeed 1500;
BA_ "InvalidValue" SG_ 1037 MHU_DigitSpeed "1FFh";
BA_ "GenSigTimeoutTime_ALL" SG_ 1042 eCall_state 2000;
BA_ "GenSigTimeoutTime_ALL" SG_ 1044 CRC_SW_1 2500;
BA_ "GenSigTimeoutTime_ALL" SG_ 1044 Message_Counter_SW_1 2500;
BA_ "InvalidValue" SG_ 1044 Message_Counter_SW_1 "Fh";
BA_ "GenSigTimeoutTime_ALL" SG_ 1044 Calc_Threshold 2500;
BA_ "GenSigTimeoutTime_ALL" SG_ 1044 Real_Impedence 2500;
BA_ "GenSigTimeoutTime_ALL" SG_ 1044 Immag_Impedence 2500;
BA_ "GenSigTimeoutTime_ALL" SG_ 1044 ERR_ST_HOD 2500;
BA_ "GenSigTimeoutTime_ALL" SG_ 1044 RsErr_HOD 2500;
BA_ "GenSigTimeoutTime_ALL" SG_ 1044 HOD_status 2500;
BA_ "InvalidValue" SG_ 1044 HOD_status "Fh";
BA_ "GenSigStartValue" SG_ 1046 BCM_STAT_LeftMirrorPosX 15;
BA_ "GenSigTimeoutTime_ALL" SG_ 1046 BCM_STAT_LeftMirrorPosX 500;
BA_ "InvalidValue" SG_ 1046 BCM_STAT_LeftMirrorPosX "FFh";
BA_ "GenSigStartValue" SG_ 1046 BCM_STAT_LeftMirrorPosY 15;
BA_ "GenSigTimeoutTime_ALL" SG_ 1046 BCM_STAT_LeftMirrorPosY 500;
BA_ "InvalidValue" SG_ 1046 BCM_STAT_LeftMirrorPosY "FFh";
BA_ "GenSigStartValue" SG_ 1046 BCM_STAT_RightMirrorPosX 15;
BA_ "GenSigTimeoutTime_ALL" SG_ 1046 BCM_STAT_RightMirrorPosX 500;
BA_ "InvalidValue" SG_ 1046 BCM_STAT_RightMirrorPosX "FFh";
BA_ "GenSigStartValue" SG_ 1046 BCM_STAT_RightMirrorPosY 15;
BA_ "GenSigTimeoutTime_ALL" SG_ 1046 BCM_STAT_RightMirrorPosY 500;
BA_ "InvalidValue" SG_ 1046 BCM_STAT_RightMirrorPosY "FFh";
BA_ "GenSigTimeoutTime_ALL" SG_ 1046 BCM_STAT_Mirror 500;
BA_ "InvalidValue" SG_ 1046 BCM_STAT_Mirror "3h";
BA_ "GenSigTimeoutTime_ALL" SG_ 1046 BCM_STAT_MirrorAdjustLeft 500;
BA_ "InvalidValue" SG_ 1046 BCM_STAT_MirrorAdjustLeft "3h";
BA_ "GenSigTimeoutTime_ALL" SG_ 1046 BCM_STAT_MirrorAdjustRight 500;
BA_ "InvalidValue" SG_ 1046 BCM_STAT_MirrorAdjustRight "3h";
BA_ "GenSigSendType" SG_ 1049 SHVU_STAT_SeatHeatingFrontL 3;
BA_ "InvalidValue" SG_ 1049 SHVU_STAT_SeatHeatingFrontL "4h";
BA_ "GenSigSendType" SG_ 1049 SHVU_STAT_SeatHeatingFrontR 3;
BA_ "InvalidValue" SG_ 1049 SHVU_STAT_SeatHeatingFrontR "4h";
BA_ "GenSigSendType" SG_ 1049 SHVU_STAT_SeatCoolingFrontL 3;
BA_ "InvalidValue" SG_ 1049 SHVU_STAT_SeatCoolingFrontL "4h";
BA_ "GenSigSendType" SG_ 1049 SHVU_STAT_SeatCoolingFrontR 3;
BA_ "InvalidValue" SG_ 1049 SHVU_STAT_SeatCoolingFrontR "4h";
BA_ "GenSigSendType" SG_ 1049 SHVU_STAT_FrontSeatVentSts 3;
BA_ "InvalidValue" SG_ 1049 SHVU_STAT_FrontSeatVentSts "3h";
BA_ "GenSigSendType" SG_ 1050 SHVU_STAT_SeatCoolingRearL 3;
BA_ "InvalidValue" SG_ 1050 SHVU_STAT_SeatCoolingRearL "4h";
BA_ "GenSigSendType" SG_ 1050 SHVU_STAT_SeatCoolingRearR 3;
BA_ "InvalidValue" SG_ 1050 SHVU_STAT_SeatCoolingRearR "4h";
BA_ "GenSigSendType" SG_ 1050 SHVU_STAT_SeatHeatingReartL 3;
BA_ "InvalidValue" SG_ 1050 SHVU_STAT_SeatHeatingReartL "4h";
BA_ "GenSigSendType" SG_ 1050 SHVU_STAT_SeatHeatingRearR 3;
BA_ "InvalidValue" SG_ 1050 SHVU_STAT_SeatHeatingRearR "4h";
BA_ "GenSigSendType" SG_ 1050 SHVU_STAT_RearSeatVentSts 3;
BA_ "InvalidValue" SG_ 1050 SHVU_STAT_RearSeatVentSts "3h";
BA_ "GenSigTimeoutTime_ALL" SG_ 1052 CHKSM_PSM_SEAT_POSITION 5000;
BA_ "GenSigTimeoutTime_ALL" SG_ 1052 AVL_PSM_SEAT_POSITION 5000;
BA_ "InvalidValue" SG_ 1052 AVL_PSM_SEAT_POSITION "Fh";
BA_ "GenSigTimeoutTime_ALL" SG_ 1052 PSM_Seat_track_pos_Dri 5000;
BA_ "InvalidValue" SG_ 1052 PSM_Seat_track_pos_Dri "3h";
BA_ "GenSigTimeoutTime_ALL" SG_ 1052 PSM_Seat_track_posPas 5000;
BA_ "InvalidValue" SG_ 1052 PSM_Seat_track_posPas "3h";
BA_ "GenSigStartValue" SG_ 1053 BCM_STAT_AutoRearWiper 1;
BA_ "GenSigTimeoutTime_ALL" SG_ 1053 BCM_STAT_AutoRearWiper 500;
BA_ "InvalidValue" SG_ 1053 BCM_STAT_AutoRearWiper "3h";
BA_ "GenSigStartValue" SG_ 1053 BCM_STAT_MirrorFoldSetting 3;
BA_ "GenSigTimeoutTime_ALL" SG_ 1053 BCM_STAT_MirrorFoldSetting 500;
BA_ "InvalidValue" SG_ 1053 BCM_STAT_MirrorFoldSetting "3h";
BA_ "GenSigTimeoutTime_ALL" SG_ 1053 BCM_STAT_IMMO_KeyfobID2 500;
BA_ "GenSigTimeoutTime_ALL" SG_ 1053 BCM_STAT_MirrorAutoUnfold 500;
BA_ "InvalidValue" SG_ 1053 BCM_STAT_MirrorAutoUnfold "3h";
BA_ "GenSigTimeoutTime_ALL" SG_ 1053 BCM_STAT_MirrorReverseLink 500;
BA_ "GenSigTimeoutTime_ALL" SG_ 1053 BCM_STAT_MirrorDefaultSTATting 500;
BA_ "InvalidValue" SG_ 1053 BCM_STAT_MirrorDefaultSTATting "3h";
BA_ "GenSigTimeoutTime_ALL" SG_ 1053 BCM_STAT_WelcomeTriggerCondition 500;
BA_ "InvalidValue" SG_ 1053 BCM_STAT_WelcomeTriggerCondition "3h";
BA_ "GenSigStartValue" SG_ 1053 BCM_STAT_FrontDomeLamp 1;
BA_ "GenSigTimeoutTime_ALL" SG_ 1053 BCM_STAT_FrontDomeLamp 500;
BA_ "InvalidValue" SG_ 1053 BCM_STAT_FrontDomeLamp "3h";
BA_ "GenSigTimeoutTime_ALL" SG_ 1053 BCM_STAT_FollowMeHome 500;
BA_ "InvalidValue" SG_ 1053 BCM_STAT_FollowMeHome "5h";
BA_ "GenSigTimeoutTime_ALL" SG_ 1053 BCM_STAT_ExteriorLight 500;
BA_ "InvalidValue" SG_ 1053 BCM_STAT_ExteriorLight "4h";
BA_ "GenSigStartValue" SG_ 1053 BCM_STAT_RemoteLockFeedback 7;
BA_ "GenSigTimeoutTime_ALL" SG_ 1053 BCM_STAT_RemoteLockFeedback 500;
BA_ "InvalidValue" SG_ 1053 BCM_STAT_RemoteLockFeedback "7h";
BA_ "GenSigStartValue" SG_ 1053 BCM_STAT_RemoteDoorUnlock 3;
BA_ "GenSigTimeoutTime_ALL" SG_ 1053 BCM_STAT_RemoteDoorUnlock 500;
BA_ "InvalidValue" SG_ 1053 BCM_STAT_RemoteDoorUnlock "3h";
BA_ "GenSigStartValue" SG_ 1053 BCM_STAT_AutoDoorUnlock 3;
BA_ "GenSigTimeoutTime_ALL" SG_ 1053 BCM_STAT_AutoDoorUnlock 500;
BA_ "InvalidValue" SG_ 1053 BCM_STAT_AutoDoorUnlock "3h";
BA_ "GenSigTimeoutTime_ALL" SG_ 1053 BCM_STAT_WalkawayDoorLock 500;
BA_ "GenSigSendType" SG_ 1053 BCM_STAT_WalkawayDoorLock 2;
BA_ "GenSigStartValue" SG_ 1053 BCM_STAT_AmbientLightBrighness 80;
BA_ "GenSigTimeoutTime_ALL" SG_ 1053 BCM_STAT_AmbientLightBrighness 500;
BA_ "InvalidValue" SG_ 1053 BCM_STAT_AmbientLightBrighness "7Fh";
BA_ "GenSigStartValue" SG_ 1053 BCM_STAT_WiperServiceMode 3;
BA_ "GenSigTimeoutTime_ALL" SG_ 1053 BCM_STAT_WiperServiceMode 500;
BA_ "InvalidValue" SG_ 1053 BCM_STAT_WiperServiceMode "3h";
BA_ "GenSigStartValue" SG_ 1053 BCM_STAT_IMMO_KeyfobID 3;
BA_ "GenSigTimeoutTime_ALL" SG_ 1053 BCM_STAT_IMMO_KeyfobID 500;
BA_ "InvalidValue" SG_ 1053 BCM_STAT_IMMO_KeyfobID "3h";
BA_ "GenSigTimeoutTime_ALL" SG_ 1053 BCM_STAT_RearHeatedWindowMirror 500;
BA_ "InvalidValue" SG_ 1053 BCM_STAT_RearHeatedWindowMirror "3h";
BA_ "GenSigStartValue" SG_ 1053 BCM_STAT_AntiTheftMode 3;
BA_ "GenSigTimeoutTime_ALL" SG_ 1053 BCM_STAT_AntiTheftMode 500;
BA_ "InvalidValue" SG_ 1053 BCM_STAT_AntiTheftMode "4h";
BA_ "GenSigTimeoutTime_ALL" SG_ 1053 BCM_STAT_ClimateKeepOnSts 500;
BA_ "InvalidValue" SG_ 1053 BCM_STAT_ClimateKeepOnSts "null";
BA_ "GenSigTimeoutTime_ALL" SG_ 1053 BCM_STAT_FKSfeedback 500;
BA_ "InvalidValue" SG_ 1053 BCM_STAT_FKSfeedback "3h";
BA_ "GenSigTimeoutTime_ALL" SG_ 1053 SECCAN_CmftCnfrm 500;
BA_ "InvalidValue" SG_ 1053 SECCAN_CmftCnfrm "null";
BA_ "GenSigTimeoutTime_ALL" SG_ 1055 OCS_P_CHKSM 2500;
BA_ "GenSigTimeoutTime_ALL" SG_ 1055 OCS_P_AVL 2500;
BA_ "InvalidValue" SG_ 1055 OCS_P_AVL "Fh";
BA_ "GenSigStartValue" SG_ 1055 OCS_Passenger_class_stat 1;
BA_ "GenSigTimeoutTime_ALL" SG_ 1055 OCS_Passenger_class_stat 2500;
BA_ "InvalidValue" SG_ 1055 OCS_Passenger_class_stat "3h";
BA_ "GenSigTimeoutTime_ALL" SG_ 1058 CHKSM_MHU_STAT 5000;
BA_ "InvalidValue" SG_ 1058 CHKSM_MHU_STAT "null";
BA_ "GenSigTimeoutTime_ALL" SG_ 1058 ALV_MHU_STAT 5000;
BA_ "InvalidValue" SG_ 1058 ALV_MHU_STAT "Fh";
BA_ "GenSigTimeoutTime_ALL" SG_ 1058 MHU_STAT_Cluster 5000;
BA_ "InvalidValue" SG_ 1058 MHU_STAT_Cluster "3h";
BA_ "GenSigTimeoutTime_ALL" SG_ 1058 MHU_STAT_Infotainment 5000;
BA_ "InvalidValue" SG_ 1058 MHU_STAT_Infotainment "3h";
BA_ "GenSigStartValue" SG_ 1058 MHU_STAT_MileageUnit 3;
BA_ "GenSigTimeoutTime_ALL" SG_ 1058 MHU_STAT_MileageUnit 5000;
BA_ "InvalidValue" SG_ 1058 MHU_STAT_MileageUnit "3h";
BA_ "GenSigStartValue" SG_ 1058 MHU_STAT_PressureUnit 3;
BA_ "GenSigTimeoutTime_ALL" SG_ 1058 MHU_STAT_PressureUnit 5000;
BA_ "InvalidValue" SG_ 1058 MHU_STAT_PressureUnit "3h";
BA_ "GenSigStartValue" SG_ 1058 MHU_STAT_TemperatureUnit 3;
BA_ "GenSigTimeoutTime_ALL" SG_ 1058 MHU_STAT_TemperatureUnit 5000;
BA_ "InvalidValue" SG_ 1058 MHU_STAT_TemperatureUnit "3h";
BA_ "GenSigTimeoutTime_ALL" SG_ 1058 MHU_Operation_State 5000;
BA_ "InvalidValue" SG_ 1058 MHU_Operation_State "7h";
BA_ "GenSigStartValue" SG_ 1058 MHU_STAT_Language 31;
BA_ "GenSigTimeoutTime_ALL" SG_ 1058 MHU_STAT_Language 5000;
BA_ "InvalidValue" SG_ 1058 MHU_STAT_Language "1Fh";
BA_ "GenSigStartValue" SG_ 1058 MHU_STAT_EnergyConsumptionUnit 7;
BA_ "GenSigTimeoutTime_ALL" SG_ 1058 MHU_STAT_EnergyConsumptionUnit 5000;
BA_ "InvalidValue" SG_ 1058 MHU_STAT_EnergyConsumptionUnit "Fh";
BA_ "GenSigStartValue" SG_ 1058 BAS_version 7;
BA_ "GenSigTimeoutTime_ALL" SG_ 1058 BAS_version 5000;
BA_ "GenSigStartValue" SG_ 1058 MHU_STAT_SaleCountry 1023;
BA_ "GenSigTimeoutTime_ALL" SG_ 1058 MHU_STAT_SaleCountry 5000;
BA_ "InvalidValue" SG_ 1058 MHU_STAT_SaleCountry "3FFh";
BA_ "InvalidValue" SG_ 1064 TRMFitted "3";
BA_ "GenSigTimeoutTime_ALL" SG_ 1064 TRMFitted 1000;
BA_ "GenSigStartValue" SG_ 1064 TRMFitted 2;
BA_ "GenSigTimeoutTime_ALL" SG_ 1068 CHSKM_PSM_D_SEAT_CONTROL 1000;
BA_ "InvalidValue" SG_ 1068 CHSKM_PSM_D_SEAT_CONTROL "null";
BA_ "GenSigTimeoutTime_ALL" SG_ 1068 ALV_PSM_D_SEAT_CONTROL 1000;
BA_ "InvalidValue" SG_ 1068 ALV_PSM_D_SEAT_CONTROL "Fh";
BA_ "GenSigTimeoutTime_ALL" SG_ 1068 PSM_D_DrvSeat_Control_Status 1000;
BA_ "InvalidValue" SG_ 1068 PSM_D_DrvSeat_Control_Status "7h";
BA_ "GenSigTimeoutTime_ALL" SG_ 1068 PSM_D_DrvReclinerPos 1000;
BA_ "InvalidValue" SG_ 1068 PSM_D_DrvReclinerPos "7Fh";
BA_ "GenSigTimeoutTime_ALL" SG_ 1068 PSM_D_DrvTiltPos 1000;
BA_ "InvalidValue" SG_ 1068 PSM_D_DrvTiltPos "1Fh";
BA_ "GenSigTimeoutTime_ALL" SG_ 1068 PSM_D_DrvTrackPos 1000;
BA_ "InvalidValue" SG_ 1068 PSM_D_DrvTrackPos "FFh";
BA_ "GenSigTimeoutTime_ALL" SG_ 1068 PSM_D_DrvHeightPos 1000;
BA_ "InvalidValue" SG_ 1068 PSM_D_DrvHeightPos "3Fh";
BA_ "GenSigTimeoutTime_ALL" SG_ 1074 MHU_FOTA_Checksum 2500;
BA_ "InvalidValue" SG_ 1074 MHU_FOTA_Checksum "null";
BA_ "GenSigTimeoutTime_ALL" SG_ 1074 MHU_FOTA_Alive_Counter 2500;
BA_ "InvalidValue" SG_ 1074 MHU_FOTA_Alive_Counter "Fh";
BA_ "GenSigTimeoutTime_ALL" SG_ 1074 MHU_FOTA_State 2500;
BA_ "InvalidValue" SG_ 1074 MHU_FOTA_State "7h";
BA_ "GenSigTimeoutTime_ALL" SG_ 1074 MHU_FOTA_Error_Code 2500;
BA_ "InvalidValue" SG_ 1074 MHU_FOTA_Error_Code "null";
BA_ "GenSigSendType" SG_ 1077 BCM_SCM_BC_Button 4;
BA_ "InvalidValue" SG_ 1077 BCM_SCM_BC_Button "3h";
BA_ "GenSigTimeoutTime_ALL" SG_ 1082 CRC_VCU_MHU_info 1000;
BA_ "InvalidValue" SG_ 1082 CRC_VCU_MHU_info "null";
BA_ "GenSigTimeoutTime_ALL" SG_ 1082 ALIV_VCU_MHU_info 500;
BA_ "InvalidValue" SG_ 1082 ALIV_VCU_MHU_info "Fh";
BA_ "GenSigTimeoutTime_ALL" SG_ 1082 VCU_BrakeRegenMode 1000;
BA_ "GenSigTimeoutTime_ALL" SG_ 1082 VCU_CreepDisable_stt 1000;
BA_ "InvalidValue" SG_ 1082 VCU_CreepDisable_stt "null";
BA_ "GenSigStartValue" SG_ 1082 VCU_PowerRegenGaugeDisplay 100;
BA_ "GenSigTimeoutTime_ALL" SG_ 1082 VCU_PowerRegenGaugeDisplay 1000;
BA_ "InvalidValue" SG_ 1082 VCU_PowerRegenGaugeDisplay "FFh";
BA_ "GenSigTimeoutTime_ALL" SG_ 1082 VCU_Charging_Authen_stt 500;
BA_ "InvalidValue" SG_ 1082 VCU_Charging_Authen_stt "null";
BA_ "GenSigTimeoutTime_ALL" SG_ 1082 VCU_ChgGun_BadConn_stt 500;
BA_ "InvalidValue" SG_ 1082 VCU_ChgGun_BadConn_stt "null";
BA_ "GenSigTimeoutTime_ALL" SG_ 1082 VCU_ChgPort_Open_stt 1000;
BA_ "InvalidValue" SG_ 1082 VCU_ChgPort_Open_stt "null";
BA_ "GenSigStartValue" SG_ 1082 VCU_Regen_available 1;
BA_ "GenSigTimeoutTime_ALL" SG_ 1082 VCU_Regen_available 500;
BA_ "InvalidValue" SG_ 1082 VCU_Regen_available "null";
BA_ "GenSigTimeoutTime_ALL" SG_ 1082 VCU_VehChg_STS 1000;
BA_ "InvalidValue" SG_ 1082 VCU_VehChg_STS "null";
BA_ "GenSigTimeoutTime_ALL" SG_ 1082 VCU_SOC_display 500;
BA_ "InvalidValue" SG_ 1082 VCU_SOC_display "null";
BA_ "GenSigStartValue" SG_ 1082 VCU_ChgGun_Status 7;
BA_ "GenSigTimeoutTime_ALL" SG_ 1082 VCU_ChgGun_Status 500;
BA_ "InvalidValue" SG_ 1082 VCU_ChgGun_Status "7h";
BA_ "GenSigTimeoutTime_ALL" SG_ 1082 VCU_ChgPort_Lock_stt 1000;
BA_ "InvalidValue" SG_ 1082 VCU_ChgPort_Lock_stt "null";
BA_ "GenSigTimeoutTime_ALL" SG_ 1082 VCU_Hvbatt_charging_stt 1000;
BA_ "InvalidValue" SG_ 1082 VCU_Hvbatt_charging_stt "null";
BA_ "GenSigSendType" SG_ 1089 CHKSM_RESP_REM_FUNC_APM 2;
BA_ "InvalidValue" SG_ 1089 CHKSM_RESP_REM_FUNC_APM "null";
BA_ "GenSigSendType" SG_ 1089 RESP_REM_ResponseID_APM 2;
BA_ "InvalidValue" SG_ 1089 RESP_REM_ResponseID_APM "FFh";
BA_ "GenSigSendType" SG_ 1089 RESP_REM_DataByte0_APM 2;
BA_ "InvalidValue" SG_ 1089 RESP_REM_DataByte0_APM "FFh";
BA_ "GenSigSendType" SG_ 1089 RESP_REM_DataByte1_APM 2;
BA_ "InvalidValue" SG_ 1089 RESP_REM_DataByte1_APM "FFh";
BA_ "GenSigSendType" SG_ 1089 RESP_REM_DataByte2_APM 2;
BA_ "InvalidValue" SG_ 1089 RESP_REM_DataByte2_APM "FFh";
BA_ "GenSigSendType" SG_ 1089 RESP_REM_DataByte3_APM 2;
BA_ "InvalidValue" SG_ 1089 RESP_REM_DataByte3_APM "FFh";
BA_ "GenSigSendType" SG_ 1089 RESP_REM_DataByte4_APM 2;
BA_ "InvalidValue" SG_ 1089 RESP_REM_DataByte4_APM "FFh";
BA_ "GenSigSendType" SG_ 1089 RESP_REM_LengthTyp_APM 2;
BA_ "InvalidValue" SG_ 1089 RESP_REM_LengthTyp_APM "3h";
BA_ "GenSigSendType" SG_ 1089 RESP_REM_DataLength_APM 2;
BA_ "InvalidValue" SG_ 1089 RESP_REM_DataLength_APM "3Fh";
BA_ "GenSigTimeoutTime_ALL" SG_ 1090 WLC_IC_Error 2500;
BA_ "InvalidValue" SG_ 1090 WLC_IC_Error "null";
BA_ "GenSigTimeoutTime_ALL" SG_ 1090 WLC_FAN_Error 2500;
BA_ "InvalidValue" SG_ 1090 WLC_FAN_Error "null";
BA_ "GenSigTimeoutTime_ALL" SG_ 1090 WLC_TempSNSR_Error 2500;
BA_ "InvalidValue" SG_ 1090 WLC_TempSNSR_Error "null";
BA_ "GenSigStartValue" SG_ 1090 WLC_Setting_standard 2;
BA_ "GenSigTimeoutTime_ALL" SG_ 1090 WLC_Setting_standard 2500;
BA_ "InvalidValue" SG_ 1090 WLC_Setting_standard "null";
BA_ "GenSigTimeoutTime_ALL" SG_ 1090 Transmit_WLC_situation 2500;
BA_ "InvalidValue" SG_ 1090 Transmit_WLC_situation "null";
BA_ "GenSigTimeoutTime_ALL" SG_ 1090 WLC_VehSpeed_Error 2500;
BA_ "InvalidValue" SG_ 1090 WLC_VehSpeed_Error "null";
BA_ "GenSigTimeoutTime_ALL" SG_ 1090 WLC_Resp_Error 2500;
BA_ "InvalidValue" SG_ 1090 WLC_Resp_Error "null";
BA_ "GenSigTimeoutTime_ALL" SG_ 1090 WLC_FOD_Error 2500;
BA_ "InvalidValue" SG_ 1090 WLC_FOD_Error "null";
BA_ "GenSigTimeoutTime_ALL" SG_ 1090 WLC_Curr_Error 2500;
BA_ "InvalidValue" SG_ 1090 WLC_Curr_Error "null";
BA_ "GenSigTimeoutTime_ALL" SG_ 1090 WLC_Temp_Error 2500;
BA_ "InvalidValue" SG_ 1090 WLC_Temp_Error "null";
BA_ "GenSigTimeoutTime_ALL" SG_ 1091 WLC_IC_Error_2 2500;
BA_ "InvalidValue" SG_ 1091 WLC_IC_Error_2 "null";
BA_ "GenSigTimeoutTime_ALL" SG_ 1091 WLC_FAN_Error_2 2500;
BA_ "InvalidValue" SG_ 1091 WLC_FAN_Error_2 "null";
BA_ "GenSigTimeoutTime_ALL" SG_ 1091 WLC_TempSNSR_Error_2 2500;
BA_ "InvalidValue" SG_ 1091 WLC_TempSNSR_Error_2 "null";
BA_ "GenSigStartValue" SG_ 1091 WLC_Setting_standard_2 2;
BA_ "GenSigTimeoutTime_ALL" SG_ 1091 WLC_Setting_standard_2 2500;
BA_ "InvalidValue" SG_ 1091 WLC_Setting_standard_2 "null";
BA_ "GenSigTimeoutTime_ALL" SG_ 1091 Transmit_WLC_situation_2 2500;
BA_ "InvalidValue" SG_ 1091 Transmit_WLC_situation_2 "null";
BA_ "GenSigTimeoutTime_ALL" SG_ 1091 WLC_VehSpeed_Error_2 2500;
BA_ "InvalidValue" SG_ 1091 WLC_VehSpeed_Error_2 "null";
BA_ "GenSigTimeoutTime_ALL" SG_ 1091 WLC_Resp_Error_2 2500;
BA_ "InvalidValue" SG_ 1091 WLC_Resp_Error_2 "null";
BA_ "GenSigTimeoutTime_ALL" SG_ 1091 WLC_FOD_Error_2 2500;
BA_ "InvalidValue" SG_ 1091 WLC_FOD_Error_2 "null";
BA_ "GenSigTimeoutTime_ALL" SG_ 1091 WLC_Curr_Error_2 2500;
BA_ "InvalidValue" SG_ 1091 WLC_Curr_Error_2 "null";
BA_ "GenSigTimeoutTime_ALL" SG_ 1091 WLC_Temp_Error_2 2500;
BA_ "InvalidValue" SG_ 1091 WLC_Temp_Error_2 "null";
BA_ "GenSigTimeoutTime_ALL" SG_ 1093 RS_Sol_L 500;
BA_ "InvalidValue" SG_ 1093 RS_Sol_L "FFh";
BA_ "GenSigTimeoutTime_ALL" SG_ 1093 RS_Sol_R 500;
BA_ "InvalidValue" SG_ 1093 RS_Sol_R "FFh";
BA_ "GenSigTimeoutTime_ALL" SG_ 1093 RS_F_LightSensor 500;
BA_ "GenSigTimeoutTime_ALL" SG_ 1093 RS_F_HUD_Sensor 500;
BA_ "InvalidValue" SG_ 1093 RS_F_HUD_Sensor "null";
BA_ "GenSigTimeoutTime_ALL" SG_ 1093 RS_St_LampReq 500;
BA_ "InvalidValue" SG_ 1093 RS_St_LampReq "3h";
BA_ "GenSigTimeoutTime_ALL" SG_ 1093 RS_St_CurrentRain 500;
BA_ "InvalidValue" SG_ 1093 RS_St_CurrentRain "7h";
BA_ "GenSigTimeoutTime_ALL" SG_ 1093 RS_HUD_illuminance 500;
BA_ "InvalidValue" SG_ 1093 RS_HUD_illuminance "FFFFh";
BA_ "GenSigTimeoutTime_ALL" SG_ 1095 MHU_SET_TransportMode 1000;
BA_ "InvalidValue" SG_ 1095 MHU_SET_TransportMode "3h";
BA_ "GenSigTimeoutTime_ALL" SG_ 1095 CHKSM_MHU_SET_CarMode 1000;
BA_ "InvalidValue" SG_ 1095 CHKSM_MHU_SET_CarMode "null";
BA_ "GenSigTimeoutTime_ALL" SG_ 1095 ALV_MHU_SET_CarMode 1000;
BA_ "InvalidValue" SG_ 1095 ALV_MHU_SET_CarMode "Fh";
BA_ "GenSigTimeoutTime_ALL" SG_ 1095 MHU_Request_CarOFF 1000;
BA_ "InvalidValue" SG_ 1095 MHU_Request_CarOFF "3h";
BA_ "GenSigTimeoutTime_ALL" SG_ 1095 MHU_SET_ChildMode 1000;
BA_ "InvalidValue" SG_ 1095 MHU_SET_ChildMode "3h";
BA_ "GenSigTimeoutTime_ALL" SG_ 1095 MHU_SET_GameMode 1000;
BA_ "InvalidValue" SG_ 1095 MHU_SET_GameMode "3h";
BA_ "GenSigTimeoutTime_ALL" SG_ 1095 MHU_SET_KaraokeMode 1000;
BA_ "InvalidValue" SG_ 1095 MHU_SET_KaraokeMode "3h";
BA_ "GenSigTimeoutTime_ALL" SG_ 1095 MHU_SET_WashMode 1000;
BA_ "InvalidValue" SG_ 1095 MHU_SET_WashMode "3h";
BA_ "GenSigTimeoutTime_ALL" SG_ 1095 MHU_SET_StopMode 1000;
BA_ "InvalidValue" SG_ 1095 MHU_SET_StopMode "3h";
BA_ "GenSigSendType" SG_ 1104 WindowLifterFrontL 2;
BA_ "InvalidValue" SG_ 1104 WindowLifterFrontL "7h";
BA_ "GenSigSendType" SG_ 1104 WindowLifterFrontR 2;
BA_ "InvalidValue" SG_ 1104 WindowLifterFrontR "7h";
BA_ "GenSigSendType" SG_ 1104 WindowLifterRearL 2;
BA_ "InvalidValue" SG_ 1104 WindowLifterRearL "7h";
BA_ "GenSigSendType" SG_ 1104 WindowLifterRearR 2;
BA_ "InvalidValue" SG_ 1104 WindowLifterRearR "7h";
BA_ "GenSigSendType" SG_ 1104 MHU_SET_WindowAutoClose 2;
BA_ "InvalidValue" SG_ 1104 MHU_SET_WindowAutoClose "3h";
BA_ "GenSigSendType" SG_ 1110 OP_WISW_SZL_LIN 3;
BA_ "InvalidValue" SG_ 1110 OP_WISW_SZL_LIN "null";
BA_ "GenSigSendType" SG_ 1110 COMM_ERR_SZL_LIN 3;
BA_ "InvalidValue" SG_ 1110 COMM_ERR_SZL_LIN "null";
BA_ "GenSigSendType" SG_ 1110 BCM_Wiper_Front_Status 3;
BA_ "InvalidValue" SG_ 1110 BCM_Wiper_Front_Status "null";
BA_ "GenSigSendType" SG_ 1110 OP_WIPO_SZL_LIN 3;
BA_ "InvalidValue" SG_ 1110 OP_WIPO_SZL_LIN "null";
BA_ "GenSigSendType" SG_ 1110 OP_COLS_SZL_LIN 3;
BA_ "InvalidValue" SG_ 1110 OP_COLS_SZL_LIN "null";
BA_ "GenSigSendType" SG_ 1110 NOD_ERR_SZL_LIN 3;
BA_ "InvalidValue" SG_ 1110 NOD_ERR_SZL_LIN "null";
BA_ "GenSigSendType" SG_ 1110 BCM_Wiper_Rear_Status 3;
BA_ "InvalidValue" SG_ 1110 BCM_Wiper_Rear_Status "3h";
BA_ "GenSigSendType" SG_ 1110 ALIV_WISW_SZL_LIN 3;
BA_ "InvalidValue" SG_ 1110 ALIV_WISW_SZL_LIN "Fh";
BA_ "GenSigSendType" SG_ 1111 AmbLight_Error_Z5 3;
BA_ "InvalidValue" SG_ 1111 AmbLight_Error_Z5 "null";
BA_ "GenSigSendType" SG_ 1111 AmbLight_Error_Z4 3;
BA_ "InvalidValue" SG_ 1111 AmbLight_Error_Z4 "null";
BA_ "GenSigSendType" SG_ 1111 AmbLight_Error_Z3 3;
BA_ "InvalidValue" SG_ 1111 AmbLight_Error_Z3 "null";
BA_ "GenSigSendType" SG_ 1111 AmbLight_Error_Z2 3;
BA_ "InvalidValue" SG_ 1111 AmbLight_Error_Z2 "null";
BA_ "GenSigSendType" SG_ 1111 AmbLight_Error_Z1 3;
BA_ "InvalidValue" SG_ 1111 AmbLight_Error_Z1 "null";
BA_ "GenSigSendType" SG_ 1112 AmbLightColorZoneReq 2;
BA_ "InvalidValue" SG_ 1112 AmbLightColorZoneReq "null";
BA_ "GenSigSendType" SG_ 1112 AmbLightColorRed 2;
BA_ "InvalidValue" SG_ 1112 AmbLightColorRed "null";
BA_ "GenSigSendType" SG_ 1112 AmbLightColorGreen 2;
BA_ "InvalidValue" SG_ 1112 AmbLightColorGreen "null";
BA_ "GenSigSendType" SG_ 1112 AmbLightColorBlue 2;
BA_ "InvalidValue" SG_ 1112 AmbLightColorBlue "null";
BA_ "GenSigSendType" SG_ 1112 SECCAN_BCM_Clr_Rq 2;
BA_ "InvalidValue" SG_ 1112 SECCAN_BCM_Clr_Rq "null";
BA_ "GenSigSendType" SG_ 1113 AmbLightIntensityTimingZoneReq 2;
BA_ "InvalidValue" SG_ 1113 AmbLightIntensityTimingZoneReq "null";
BA_ "GenSigSendType" SG_ 1113 AmbLightIntensityTimingTypeReq 2;
BA_ "InvalidValue" SG_ 1113 AmbLightIntensityTimingTypeReq "null";
BA_ "GenSigSendType" SG_ 1113 AmbLightIntenTimingBrightReq 2;
BA_ "InvalidValue" SG_ 1113 AmbLightIntenTimingBrightReq "null";
BA_ "GenSigSendType" SG_ 1113 AmbLightIntensityTimingT1Req 2;
BA_ "InvalidValue" SG_ 1113 AmbLightIntensityTimingT1Req "null";
BA_ "GenSigSendType" SG_ 1113 AmbLightIntensityTimingT2Req 2;
BA_ "InvalidValue" SG_ 1113 AmbLightIntensityTimingT2Req "null";
BA_ "GenSigSendType" SG_ 1113 AmbLightIntensityTimingT3Req 2;
BA_ "InvalidValue" SG_ 1113 AmbLightIntensityTimingT3Req "null";
BA_ "GenSigSendType" SG_ 1113 AmbLightIntensityTimingT4Req 2;
BA_ "InvalidValue" SG_ 1113 AmbLightIntensityTimingT4Req "null";
BA_ "GenSigSendType" SG_ 1113 AmbLightIntensityTimingN2Req 2;
BA_ "InvalidValue" SG_ 1113 AmbLightIntensityTimingN2Req "null";
BA_ "GenSigSendType" SG_ 1113 AmbLightIntensityTimingN1Req 2;
BA_ "InvalidValue" SG_ 1113 AmbLightIntensityTimingN1Req "null";
BA_ "GenSigTimeoutTime_ALL" SG_ 1124 LDML_LampAssemblySts 500;
BA_ "InvalidValue" SG_ 1124 LDML_LampAssemblySts "3h";
BA_ "GenSigTimeoutTime_ALL" SG_ 1124 LDML_PosLmpSts 500;
BA_ "InvalidValue" SG_ 1124 LDML_PosLmpSts "3h";
BA_ "GenSigTimeoutTime_ALL" SG_ 1124 LDML_ControllerSts 500;
BA_ "InvalidValue" SG_ 1124 LDML_ControllerSts "3h";
BA_ "GenSigTimeoutTime_ALL" SG_ 1124 LDML_TurnIndicatorSts 500;
BA_ "InvalidValue" SG_ 1124 LDML_TurnIndicatorSts "3h";
BA_ "GenSigTimeoutTime_ALL" SG_ 1124 LDML_AuxLBSts 500;
BA_ "InvalidValue" SG_ 1124 LDML_AuxLBSts "3h";
BA_ "GenSigTimeoutTime_ALL" SG_ 1124 LDML_LowBeamSts 500;
BA_ "InvalidValue" SG_ 1124 LDML_LowBeamSts "3h";
BA_ "GenSigTimeoutTime_ALL" SG_ 1124 LDML_HighBeamSts 500;
BA_ "InvalidValue" SG_ 1124 LDML_HighBeamSts "3h";
BA_ "GenSigTimeoutTime_ALL" SG_ 1124 LDML_DayRunningLampSts 500;
BA_ "InvalidValue" SG_ 1124 LDML_DayRunningLampSts "3h";
BA_ "GenSigTimeoutTime_ALL" SG_ 1124 LDML_DayTimeRunningLightFbSts 500;
BA_ "InvalidValue" SG_ 1124 LDML_DayTimeRunningLightFbSts "3h";
BA_ "GenSigTimeoutTime_ALL" SG_ 1124 LDML_AutoLvlFbSts 500;
BA_ "InvalidValue" SG_ 1124 LDML_AutoLvlFbSts "3h";
BA_ "GenSigTimeoutTime_ALL" SG_ 1124 LDML_AdptvDrvBeamFbSts 500;
BA_ "InvalidValue" SG_ 1124 LDML_AdptvDrvBeamFbSts "3h";
BA_ "GenSigTimeoutTime_ALL" SG_ 1124 LDML_AuxHBSts 500;
BA_ "InvalidValue" SG_ 1124 LDML_AuxHBSts "3h";
BA_ "GenSigTimeoutTime_ALL" SG_ 1124 LDML_FollowMeHomeFbSts 500;
BA_ "InvalidValue" SG_ 1124 LDML_FollowMeHomeFbSts "5h";
BA_ "GenSigTimeoutTime_ALL" SG_ 1124 LDML_ExteriorLightFbSts 500;
BA_ "InvalidValue" SG_ 1124 LDML_ExteriorLightFbSts "4h";
BA_ "GenSigStartValue" SG_ 1124 LDML_AHB_ICON_Feed 3;
BA_ "GenSigTimeoutTime_ALL" SG_ 1124 LDML_AHB_ICON_Feed 500;
BA_ "InvalidValue" SG_ 1124 LDML_AHB_ICON_Feed "3h";
BA_ "GenSigTimeoutTime_ALL" SG_ 1125 LDMR_LampAssemblySts 500;
BA_ "InvalidValue" SG_ 1125 LDMR_LampAssemblySts "3h";
BA_ "GenSigTimeoutTime_ALL" SG_ 1125 LDMR_PosLmpSts 500;
BA_ "InvalidValue" SG_ 1125 LDMR_PosLmpSts "3h";
BA_ "GenSigTimeoutTime_ALL" SG_ 1125 LDMR_ControllerSts 500;
BA_ "InvalidValue" SG_ 1125 LDMR_ControllerSts "3h";
BA_ "GenSigTimeoutTime_ALL" SG_ 1125 LDMR_TurnIndicatorSts 500;
BA_ "InvalidValue" SG_ 1125 LDMR_TurnIndicatorSts "3h";
BA_ "GenSigTimeoutTime_ALL" SG_ 1125 LDMR_AuxLBSts 500;
BA_ "InvalidValue" SG_ 1125 LDMR_AuxLBSts "3h";
BA_ "GenSigTimeoutTime_ALL" SG_ 1125 LDMR_LowBeamSts 500;
BA_ "InvalidValue" SG_ 1125 LDMR_LowBeamSts "3h";
BA_ "GenSigTimeoutTime_ALL" SG_ 1125 LDMR_HighBeamSts 500;
BA_ "InvalidValue" SG_ 1125 LDMR_HighBeamSts "3h";
BA_ "GenSigTimeoutTime_ALL" SG_ 1125 LDMR_DayRunningLampSts 500;
BA_ "InvalidValue" SG_ 1125 LDMR_DayRunningLampSts "3h";
BA_ "GenSigTimeoutTime_ALL" SG_ 1125 LDMR_DayTimeRunningLightFbSts 500;
BA_ "InvalidValue" SG_ 1125 LDMR_DayTimeRunningLightFbSts "3h";
BA_ "GenSigTimeoutTime_ALL" SG_ 1125 LDMR_AutoLvlFbSts 500;
BA_ "InvalidValue" SG_ 1125 LDMR_AutoLvlFbSts "3h";
BA_ "GenSigTimeoutTime_ALL" SG_ 1125 LDMR_AdptvDrvBeamFbSts 500;
BA_ "InvalidValue" SG_ 1125 LDMR_AdptvDrvBeamFbSts "3h";
BA_ "GenSigTimeoutTime_ALL" SG_ 1125 LDMR_AuxHBSts 500;
BA_ "InvalidValue" SG_ 1125 LDMR_AuxHBSts "3h";
BA_ "GenSigTimeoutTime_ALL" SG_ 1125 LDMR_FollowMeHomeFbSts 500;
BA_ "InvalidValue" SG_ 1125 LDMR_FollowMeHomeFbSts "5h";
BA_ "GenSigTimeoutTime_ALL" SG_ 1125 LDMR_ExteriorLightFbSts 500;
BA_ "InvalidValue" SG_ 1125 LDMR_ExteriorLightFbSts "4h";
BA_ "GenSigStartValue" SG_ 1125 LDMR_AHB_ICON_Feed 3;
BA_ "GenSigTimeoutTime_ALL" SG_ 1125 LDMR_AHB_ICON_Feed 500;
BA_ "InvalidValue" SG_ 1125 LDMR_AHB_ICON_Feed "3h";
BA_ "GenSigSendType" SG_ 1152 CHKSM_PSM_WARNING_MSG 3;
BA_ "GenSigTimeoutTime_ALL" SG_ 1152 CHKSM_PSM_WARNING_MSG 5000;
BA_ "InvalidValue" SG_ 1152 CHKSM_PSM_WARNING_MSG "null";
BA_ "GenSigSendType" SG_ 1152 ALV_PSM_WARNING_MSG 3;
BA_ "GenSigTimeoutTime_ALL" SG_ 1152 ALV_PSM_WARNING_MSG 5000;
BA_ "InvalidValue" SG_ 1152 ALV_PSM_WARNING_MSG "Fh";
BA_ "GenSigSendType" SG_ 1152 PSM_DrvSeatMissalignment 4;
BA_ "GenSigTimeoutTime_ALL" SG_ 1152 PSM_DrvSeatMissalignment 5000;
BA_ "InvalidValue" SG_ 1152 PSM_DrvSeatMissalignment "null";
BA_ "GenSigSendType" SG_ 1152 PSM_PasSeatMisalignment 4;
BA_ "GenSigTimeoutTime_ALL" SG_ 1152 PSM_PasSeatMisalignment 5000;
BA_ "InvalidValue" SG_ 1152 PSM_PasSeatMisalignment "null";
BA_ "GenSigSendType" SG_ 1152 PSM_WflagRes3 4;
BA_ "GenSigTimeoutTime_ALL" SG_ 1152 PSM_WflagRes3 5000;
BA_ "InvalidValue" SG_ 1152 PSM_WflagRes3 "null";
BA_ "GenSigSendType" SG_ 1152 PSM_WflagRes4 4;
BA_ "GenSigTimeoutTime_ALL" SG_ 1152 PSM_WflagRes4 5000;
BA_ "InvalidValue" SG_ 1152 PSM_WflagRes4 "3h";
BA_ "GenSigSendType" SG_ 1152 PSM_WflagRes5 4;
BA_ "GenSigTimeoutTime_ALL" SG_ 1152 PSM_WflagRes5 5000;
BA_ "InvalidValue" SG_ 1152 PSM_WflagRes5 "null";
BA_ "GenSigSendType" SG_ 1152 PSM_WflagRes6 4;
BA_ "GenSigTimeoutTime_ALL" SG_ 1152 PSM_WflagRes6 5000;
BA_ "InvalidValue" SG_ 1152 PSM_WflagRes6 "null";
BA_ "GenSigSendType" SG_ 1152 PSM_WflagRes7 4;
BA_ "GenSigTimeoutTime_ALL" SG_ 1152 PSM_WflagRes7 5000;
BA_ "InvalidValue" SG_ 1152 PSM_WflagRes7 "null";
BA_ "GenSigSendType" SG_ 1152 PSM_WflagRes8 4;
BA_ "GenSigTimeoutTime_ALL" SG_ 1152 PSM_WflagRes8 5000;
BA_ "InvalidValue" SG_ 1152 PSM_WflagRes8 "null";
BA_ "GenSigSendType" SG_ 1152 PSM_WflagRes9 4;
BA_ "GenSigTimeoutTime_ALL" SG_ 1152 PSM_WflagRes9 5000;
BA_ "InvalidValue" SG_ 1152 PSM_WflagRes9 "null";
BA_ "GenSigSendType" SG_ 1152 PSM_WflagRes10 4;
BA_ "GenSigTimeoutTime_ALL" SG_ 1152 PSM_WflagRes10 5000;
BA_ "InvalidValue" SG_ 1152 PSM_WflagRes10 "null";
BA_ "GenSigSendType" SG_ 1152 PSM_WflagRes11 4;
BA_ "GenSigTimeoutTime_ALL" SG_ 1152 PSM_WflagRes11 5000;
BA_ "InvalidValue" SG_ 1152 PSM_WflagRes11 "null";
BA_ "GenSigSendType" SG_ 1152 PSM_WflagRes12 4;
BA_ "GenSigTimeoutTime_ALL" SG_ 1152 PSM_WflagRes12 5000;
BA_ "InvalidValue" SG_ 1152 PSM_WflagRes12 "null";
BA_ "GenSigSendType" SG_ 1153 CHSKM_BCM_WarnMsg 3;
BA_ "GenSigTimeoutTime_ALL" SG_ 1153 CHSKM_BCM_WarnMsg 5000;
BA_ "InvalidValue" SG_ 1153 CHSKM_BCM_WarnMsg "-";
BA_ "GenSigSendType" SG_ 1153 ALV_BCM_WarnMsg 3;
BA_ "GenSigTimeoutTime_ALL" SG_ 1153 ALV_BCM_WarnMsg 5000;
BA_ "InvalidValue" SG_ 1153 ALV_BCM_WarnMsg "Fh";
BA_ "GenSigSendType" SG_ 1153 BCM_NoValidKey_1 4;
BA_ "GenSigTimeoutTime_ALL" SG_ 1153 BCM_NoValidKey_1 5000;
BA_ "InvalidValue" SG_ 1153 BCM_NoValidKey_1 "-";
BA_ "GenSigSendType" SG_ 1153 BCM_SSB_defect 4;
BA_ "GenSigTimeoutTime_ALL" SG_ 1153 BCM_SSB_defect 5000;
BA_ "InvalidValue" SG_ 1153 BCM_SSB_defect "-";
BA_ "GenSigSendType" SG_ 1153 BCM_WrongGearPosToStart 4;
BA_ "GenSigTimeoutTime_ALL" SG_ 1153 BCM_WrongGearPosToStart 5000;
BA_ "InvalidValue" SG_ 1153 BCM_WrongGearPosToStart "-";
BA_ "GenSigSendType" SG_ 1153 BCM_NoValidKey_2 4;
BA_ "GenSigTimeoutTime_ALL" SG_ 1153 BCM_NoValidKey_2 5000;
BA_ "InvalidValue" SG_ 1153 BCM_NoValidKey_2 "-";
BA_ "GenSigSendType" SG_ 1153 BCM_PressBrakeToStart 4;
BA_ "GenSigTimeoutTime_ALL" SG_ 1153 BCM_PressBrakeToStart 5000;
BA_ "InvalidValue" SG_ 1153 BCM_PressBrakeToStart "-";
BA_ "GenSigSendType" SG_ 1153 BCM_TurnOffPosLightRemindr 4;
BA_ "GenSigTimeoutTime_ALL" SG_ 1153 BCM_TurnOffPosLightRemindr 5000;
BA_ "InvalidValue" SG_ 1153 BCM_TurnOffPosLightRemindr "-";
BA_ "GenSigSendType" SG_ 1153 BCM_KeyFob_LowBattery 4;
BA_ "GenSigTimeoutTime_ALL" SG_ 1153 BCM_KeyFob_LowBattery 5000;
BA_ "InvalidValue" SG_ 1153 BCM_KeyFob_LowBattery "-";
BA_ "GenSigSendType" SG_ 1153 BCM_StopLightDefect 4;
BA_ "GenSigTimeoutTime_ALL" SG_ 1153 BCM_StopLightDefect 5000;
BA_ "InvalidValue" SG_ 1153 BCM_StopLightDefect "-";
BA_ "GenSigSendType" SG_ 1153 BCM_LowBeamDefect 4;
BA_ "GenSigTimeoutTime_ALL" SG_ 1153 BCM_LowBeamDefect 5000;
BA_ "InvalidValue" SG_ 1153 BCM_LowBeamDefect "-";
BA_ "GenSigSendType" SG_ 1153 BCM_HighBeamDefect 4;
BA_ "GenSigTimeoutTime_ALL" SG_ 1153 BCM_HighBeamDefect 5000;
BA_ "InvalidValue" SG_ 1153 BCM_HighBeamDefect "-";
BA_ "GenSigSendType" SG_ 1153 BCM_PositionLightDefect 4;
BA_ "GenSigTimeoutTime_ALL" SG_ 1153 BCM_PositionLightDefect 5000;
BA_ "InvalidValue" SG_ 1153 BCM_PositionLightDefect "-";
BA_ "GenSigSendType" SG_ 1153 BCM_CHMLS_Defect 4;
BA_ "GenSigTimeoutTime_ALL" SG_ 1153 BCM_CHMLS_Defect 5000;
BA_ "InvalidValue" SG_ 1153 BCM_CHMLS_Defect "-";
BA_ "GenSigSendType" SG_ 1153 BCM_LicencePlateLight_Defect 4;
BA_ "GenSigTimeoutTime_ALL" SG_ 1153 BCM_LicencePlateLight_Defect 5000;
BA_ "InvalidValue" SG_ 1153 BCM_LicencePlateLight_Defect "-";
BA_ "GenSigSendType" SG_ 1153 BCM_FrontFog_Defect 4;
BA_ "GenSigTimeoutTime_ALL" SG_ 1153 BCM_FrontFog_Defect 5000;
BA_ "InvalidValue" SG_ 1153 BCM_FrontFog_Defect "-";
BA_ "GenSigSendType" SG_ 1153 BCM_RearFog_Defect 4;
BA_ "GenSigTimeoutTime_ALL" SG_ 1153 BCM_RearFog_Defect 5000;
BA_ "InvalidValue" SG_ 1153 BCM_RearFog_Defect "-";
BA_ "GenSigSendType" SG_ 1153 BCM_ReverseLightDefect 4;
BA_ "GenSigTimeoutTime_ALL" SG_ 1153 BCM_ReverseLightDefect 5000;
BA_ "InvalidValue" SG_ 1153 BCM_ReverseLightDefect "-";
BA_ "GenSigSendType" SG_ 1153 BCM_RLS_Malfunction 4;
BA_ "GenSigTimeoutTime_ALL" SG_ 1153 BCM_RLS_Malfunction 5000;
BA_ "InvalidValue" SG_ 1153 BCM_RLS_Malfunction "-";
BA_ "GenSigSendType" SG_ 1153 BCM_12VBattery_LowLevel 4;
BA_ "GenSigTimeoutTime_ALL" SG_ 1153 BCM_12VBattery_LowLevel 5000;
BA_ "InvalidValue" SG_ 1153 BCM_12VBattery_LowLevel "-";
BA_ "GenSigSendType" SG_ 1153 BCM_ForgetKeyFOBInCar 4;
BA_ "GenSigTimeoutTime_ALL" SG_ 1153 BCM_ForgetKeyFOBInCar 5000;
BA_ "InvalidValue" SG_ 1153 BCM_ForgetKeyFOBInCar "-";
BA_ "GenSigSendType" SG_ 1153 BCM_12VBattery_Discharging 4;
BA_ "GenSigTimeoutTime_ALL" SG_ 1153 BCM_12VBattery_Discharging 5000;
BA_ "InvalidValue" SG_ 1153 BCM_12VBattery_Discharging "-";
BA_ "GenSigSendType" SG_ 1153 BCM_TurnIndicatorDefect 4;
BA_ "GenSigTimeoutTime_ALL" SG_ 1153 BCM_TurnIndicatorDefect 5000;
BA_ "InvalidValue" SG_ 1153 BCM_TurnIndicatorDefect "-";
BA_ "GenSigSendType" SG_ 1153 BCM_dTPMS_Malfunc 4;
BA_ "GenSigTimeoutTime_ALL" SG_ 1153 BCM_dTPMS_Malfunc 5000;
BA_ "InvalidValue" SG_ 1153 BCM_dTPMS_Malfunc "-";
BA_ "GenSigSendType" SG_ 1153 BCM_dTPMS_Malfunc_LostSensor 4;
BA_ "GenSigTimeoutTime_ALL" SG_ 1153 BCM_dTPMS_Malfunc_LostSensor 5000;
BA_ "InvalidValue" SG_ 1153 BCM_dTPMS_Malfunc_LostSensor "-";
BA_ "GenSigSendType" SG_ 1153 BCM_dTPMS_LowPressure 4;
BA_ "GenSigTimeoutTime_ALL" SG_ 1153 BCM_dTPMS_LowPressure 5000;
BA_ "InvalidValue" SG_ 1153 BCM_dTPMS_LowPressure "-";
BA_ "GenSigSendType" SG_ 1153 BCM_dTPMS_RapidLeak 4;
BA_ "GenSigTimeoutTime_ALL" SG_ 1153 BCM_dTPMS_RapidLeak 5000;
BA_ "InvalidValue" SG_ 1153 BCM_dTPMS_RapidLeak "-";
BA_ "GenSigSendType" SG_ 1153 BCM_dTPMS_HighTemperature 4;
BA_ "GenSigTimeoutTime_ALL" SG_ 1153 BCM_dTPMS_HighTemperature 5000;
BA_ "InvalidValue" SG_ 1153 BCM_dTPMS_HighTemperature "-";
BA_ "GenSigSendType" SG_ 1153 BCM_dTPMS_HighPressure 4;
BA_ "GenSigTimeoutTime_ALL" SG_ 1153 BCM_dTPMS_HighPressure 5000;
BA_ "InvalidValue" SG_ 1153 BCM_dTPMS_HighPressure "-";
BA_ "GenSigSendType" SG_ 1153 BCM_dTPMS_LowBattery 4;
BA_ "GenSigTimeoutTime_ALL" SG_ 1153 BCM_dTPMS_LowBattery 5000;
BA_ "InvalidValue" SG_ 1153 BCM_dTPMS_LowBattery "-";
BA_ "GenSigSendType" SG_ 1153 BCM_Keyfob_Leftcar 4;
BA_ "GenSigTimeoutTime_ALL" SG_ 1153 BCM_Keyfob_Leftcar 5000;
BA_ "InvalidValue" SG_ 1153 BCM_Keyfob_Leftcar "-";
BA_ "GenSigSendType" SG_ 1153 BCM_IDB_Brakelight_Malfunction 4;
BA_ "GenSigTimeoutTime_ALL" SG_ 1153 BCM_IDB_Brakelight_Malfunction 5000;
BA_ "InvalidValue" SG_ 1153 BCM_IDB_Brakelight_Malfunction "-";
BA_ "GenSigSendType" SG_ 1153 BCM_VCU_Brakelight_Malfunction 4;
BA_ "GenSigTimeoutTime_ALL" SG_ 1153 BCM_VCU_Brakelight_Malfunction 5000;
BA_ "InvalidValue" SG_ 1153 BCM_VCU_Brakelight_Malfunction "-";
BA_ "GenSigSendType" SG_ 1153 BCM_ADAS_Turnlight_Malfunction 4;
BA_ "GenSigTimeoutTime_ALL" SG_ 1153 BCM_ADAS_Turnlight_Malfunction 5000;
BA_ "InvalidValue" SG_ 1153 BCM_ADAS_Turnlight_Malfunction "-";
BA_ "GenSigSendType" SG_ 1153 BCM_ADAS_Highbeam_Malfunction 4;
BA_ "GenSigTimeoutTime_ALL" SG_ 1153 BCM_ADAS_Highbeam_Malfunction 5000;
BA_ "InvalidValue" SG_ 1153 BCM_ADAS_Highbeam_Malfunction "-";
BA_ "GenSigSendType" SG_ 1153 BCM_ADAS_LowBeam_Malfunction 4;
BA_ "GenSigTimeoutTime_ALL" SG_ 1153 BCM_ADAS_LowBeam_Malfunction 5000;
BA_ "InvalidValue" SG_ 1153 BCM_ADAS_LowBeam_Malfunction "-";
BA_ "GenSigSendType" SG_ 1153 BCM_MHU_Malfunction 4;
BA_ "GenSigTimeoutTime_ALL" SG_ 1153 BCM_MHU_Malfunction 5000;
BA_ "InvalidValue" SG_ 1153 BCM_MHU_Malfunction "-";
BA_ "GenSigSendType" SG_ 1153 BCM_BCM_Malfunction 4;
BA_ "GenSigTimeoutTime_ALL" SG_ 1153 BCM_BCM_Malfunction 5000;
BA_ "InvalidValue" SG_ 1153 BCM_BCM_Malfunction "-";
BA_ "GenSigSendType" SG_ 1153 BCM_SCM_Malfunction 4;
BA_ "GenSigTimeoutTime_ALL" SG_ 1153 BCM_SCM_Malfunction 5000;
BA_ "InvalidValue" SG_ 1153 BCM_SCM_Malfunction "-";
BA_ "GenSigSendType" SG_ 1153 BCM_CrashSignalDefect 4;
BA_ "GenSigTimeoutTime_ALL" SG_ 1153 BCM_CrashSignalDefect 5000;
BA_ "InvalidValue" SG_ 1153 BCM_CrashSignalDefect "-";
BA_ "GenSigSendType" SG_ 1153 BCM_FrontWiperDefect 4;
BA_ "GenSigTimeoutTime_ALL" SG_ 1153 BCM_FrontWiperDefect 5000;
BA_ "InvalidValue" SG_ 1153 BCM_FrontWiperDefect "-";
BA_ "GenSigSendType" SG_ 1153 BCM_Rear_RightDoorLockDefect 4;
BA_ "GenSigTimeoutTime_ALL" SG_ 1153 BCM_Rear_RightDoorLockDefect 5000;
BA_ "InvalidValue" SG_ 1153 BCM_Rear_RightDoorLockDefect "-";
BA_ "GenSigSendType" SG_ 1153 BCM_RearLeftDoorLockDefect 4;
BA_ "GenSigTimeoutTime_ALL" SG_ 1153 BCM_RearLeftDoorLockDefect 5000;
BA_ "InvalidValue" SG_ 1153 BCM_RearLeftDoorLockDefect "-";
BA_ "GenSigSendType" SG_ 1153 BCM_Front_RightDoorLockDefect 4;
BA_ "GenSigTimeoutTime_ALL" SG_ 1153 BCM_Front_RightDoorLockDefect 5000;
BA_ "InvalidValue" SG_ 1153 BCM_Front_RightDoorLockDefect "-";
BA_ "GenSigSendType" SG_ 1153 BCM_FrontLeftDoorLockDefect 4;
BA_ "GenSigTimeoutTime_ALL" SG_ 1153 BCM_FrontLeftDoorLockDefect 5000;
BA_ "InvalidValue" SG_ 1153 BCM_FrontLeftDoorLockDefect "-";
BA_ "GenSigSendType" SG_ 1153 BCM_LDML_Malfunction 4;
BA_ "GenSigTimeoutTime_ALL" SG_ 1153 BCM_LDML_Malfunction 5000;
BA_ "InvalidValue" SG_ 1153 BCM_LDML_Malfunction "-";
BA_ "GenSigSendType" SG_ 1153 BCM_LDMR_Malfunction 4;
BA_ "GenSigTimeoutTime_ALL" SG_ 1153 BCM_LDMR_Malfunction 5000;
BA_ "InvalidValue" SG_ 1153 BCM_LDMR_Malfunction "-";
BA_ "GenSigSendType" SG_ 1153 BCM_RLBL_Malfunction 4;
BA_ "GenSigTimeoutTime_ALL" SG_ 1153 BCM_RLBL_Malfunction 5000;
BA_ "InvalidValue" SG_ 1153 BCM_RLBL_Malfunction "-";
BA_ "GenSigSendType" SG_ 1153 BCM_RLBR_Malfunction 4;
BA_ "GenSigTimeoutTime_ALL" SG_ 1153 BCM_RLBR_Malfunction 5000;
BA_ "InvalidValue" SG_ 1153 BCM_RLBR_Malfunction "-";
BA_ "GenSigSendType" SG_ 1153 BCM_RLT_Malfunction 4;
BA_ "GenSigTimeoutTime_ALL" SG_ 1153 BCM_RLT_Malfunction 5000;
BA_ "InvalidValue" SG_ 1153 BCM_RLT_Malfunction "-";
BA_ "GenSigSendType" SG_ 1153 BCM_BCM_POWER_Malfunction 4;
BA_ "GenSigTimeoutTime_ALL" SG_ 1153 BCM_BCM_POWER_Malfunction 5000;
BA_ "InvalidValue" SG_ 1153 BCM_BCM_POWER_Malfunction "-";
BA_ "GenSigSendType" SG_ 1153 BCM_IDB_AutoHazardBlinking_Malf 4;
BA_ "GenSigTimeoutTime_ALL" SG_ 1153 BCM_IDB_AutoHazardBlinking_Malf 5000;
BA_ "InvalidValue" SG_ 1153 BCM_IDB_AutoHazardBlinking_Malf "-";
BA_ "GenSigTimeoutTime_ALL" SG_ 1155 TPMS_FLTirePress 500;
BA_ "InvalidValue" SG_ 1155 TPMS_FLTirePress "FFh";
BA_ "GenSigTimeoutTime_ALL" SG_ 1155 TPMS_FRTirePress 500;
BA_ "InvalidValue" SG_ 1155 TPMS_FRTirePress "FFh";
BA_ "GenSigTimeoutTime_ALL" SG_ 1155 TPMS_RLTirePress 500;
BA_ "InvalidValue" SG_ 1155 TPMS_RLTirePress "FFh";
BA_ "GenSigTimeoutTime_ALL" SG_ 1155 TPMS_RRTirePress 500;
BA_ "InvalidValue" SG_ 1155 TPMS_RRTirePress "FFh";
BA_ "GenSigTimeoutTime_ALL" SG_ 1155 TPMS_FLTirePressAlarm 500;
BA_ "GenSigTimeoutTime_ALL" SG_ 1155 TPMS_FRTirePressAlarm 500;
BA_ "InvalidValue" SG_ 1155 TPMS_FRTirePressAlarm "null";
BA_ "GenSigTimeoutTime_ALL" SG_ 1155 TPMS_RLTirePressAlarm 500;
BA_ "InvalidValue" SG_ 1155 TPMS_RLTirePressAlarm "0";
BA_ "GenSigTimeoutTime_ALL" SG_ 1155 TPMS_RRTirePressAlarm 500;
BA_ "InvalidValue" SG_ 1155 TPMS_RRTirePressAlarm "null";
BA_ "GenSigTimeoutTime_ALL" SG_ 1155 TPMS_TirePosition 500;
BA_ "InvalidValue" SG_ 1155 TPMS_TirePosition "null";
BA_ "GenSigTimeoutTime_ALL" SG_ 1155 TPMS_ready2learning 500;
BA_ "GenSigTimeoutTime_ALL" SG_ 1155 TPMS_TireTempAlarm 500;
BA_ "InvalidValue" SG_ 1155 TPMS_TireTempAlarm "null";
BA_ "GenSigTimeoutTime_ALL" SG_ 1155 TPMS_LearningStatus 500;
BA_ "GenSigStartValue" SG_ 1155 TPMS_TireTemp 68;
BA_ "GenSigTimeoutTime_ALL" SG_ 1155 TPMS_TireTemp 500;
BA_ "InvalidValue" SG_ 1155 TPMS_TireTemp "FFh";
BA_ "GenSigTimeoutTime_ALL" SG_ 1156 CHKSM_APA_FEEDBACK_MHU 500;
BA_ "GenSigTimeoutTime_ALL" SG_ 1156 ALV_APA_FEEDBACK_MHU 500;
BA_ "InvalidValue" SG_ 1156 ALV_APA_FEEDBACK_MHU "Fh";
BA_ "GenSigTimeoutTime_ALL" SG_ 1156 APA_MHU_Status 500;
BA_ "InvalidValue" SG_ 1156 APA_MHU_Status "7h";
BA_ "GenSigTimeoutTime_ALL" SG_ 1158 CHKSM_TirePressAlarm 500;
BA_ "GenSigTimeoutTime_ALL" SG_ 1158 ALV_TirePressAlarm 500;
BA_ "InvalidValue" SG_ 1158 ALV_TirePressAlarm "Fh";
BA_ "GenSigTimeoutTime_ALL" SG_ 1158 TPMS_FLTirePressAlarm2 500;
BA_ "GenSigTimeoutTime_ALL" SG_ 1158 TPMS_FRTirePressAlarm2 500;
BA_ "GenSigTimeoutTime_ALL" SG_ 1158 TPMS_RLTirePressAlarm2 500;
BA_ "GenSigTimeoutTime_ALL" SG_ 1158 TPMS_RRTirePressAlarm2 500;
BA_ "GenSigSendType" SG_ 1160 CHKSM_ACM_WARNING_MSG 3;
BA_ "GenSigTimeoutTime_ALL" SG_ 1160 CHKSM_ACM_WARNING_MSG 5000;
BA_ "InvalidValue" SG_ 1160 CHKSM_ACM_WARNING_MSG "null";
BA_ "GenSigSendType" SG_ 1160 ALV_ACM_WARNING_MSG 3;
BA_ "GenSigTimeoutTime_ALL" SG_ 1160 ALV_ACM_WARNING_MSG 5000;
BA_ "InvalidValue" SG_ 1160 ALV_ACM_WARNING_MSG "Fh";
BA_ "GenSigSendType" SG_ 1160 ACM_Malfunction 4;
BA_ "GenSigTimeoutTime_ALL" SG_ 1160 ACM_Malfunction 5000;
BA_ "InvalidValue" SG_ 1160 ACM_Malfunction "null";
BA_ "GenSigSendType" SG_ 1160 ACM_Pre_Drive_Check 4;
BA_ "GenSigTimeoutTime_ALL" SG_ 1160 ACM_Pre_Drive_Check 5000;
BA_ "InvalidValue" SG_ 1160 ACM_Pre_Drive_Check "null";
BA_ "GenSigSendType" SG_ 1160 ACM_in_Plant_Mode 4;
BA_ "GenSigTimeoutTime_ALL" SG_ 1160 ACM_in_Plant_Mode 5000;
BA_ "InvalidValue" SG_ 1160 ACM_in_Plant_Mode "null";
BA_ "GenSigSendType" SG_ 1160 ACM_PAB_Suppression 4;
BA_ "GenSigTimeoutTime_ALL" SG_ 1160 ACM_PAB_Suppression 5000;
BA_ "InvalidValue" SG_ 1160 ACM_PAB_Suppression "3h";
BA_ "GenSigSendType" SG_ 1160 ACM_Airbag_Disabled 4;
BA_ "GenSigTimeoutTime_ALL" SG_ 1160 ACM_Airbag_Disabled 5000;
BA_ "InvalidValue" SG_ 1160 ACM_Airbag_Disabled "null";
BA_ "GenSigSendType" SG_ 1160 ACM_Development_Calibration 4;
BA_ "GenSigTimeoutTime_ALL" SG_ 1160 ACM_Development_Calibration 5000;
BA_ "InvalidValue" SG_ 1160 ACM_Development_Calibration "null";
BA_ "GenSigSendType" SG_ 1160 ACM_In_Disposal_Mode 4;
BA_ "GenSigTimeoutTime_ALL" SG_ 1160 ACM_In_Disposal_Mode 5000;
BA_ "InvalidValue" SG_ 1160 ACM_In_Disposal_Mode "null";
BA_ "GenSigSendType" SG_ 1160 ACM_Seatbelt_Reminder_Request 4;
BA_ "GenSigTimeoutTime_ALL" SG_ 1160 ACM_Seatbelt_Reminder_Request 5000;
BA_ "InvalidValue" SG_ 1160 ACM_Seatbelt_Reminder_Request "null";
BA_ "GenSigSendType" SG_ 1160 ACM_SBR_Chime_Req 4;
BA_ "GenSigTimeoutTime_ALL" SG_ 1160 ACM_SBR_Chime_Req 5000;
BA_ "InvalidValue" SG_ 1160 ACM_SBR_Chime_Req "null";
BA_ "GenSigSendType" SG_ 1160 ACM_SBR_Blinking_Req 4;
BA_ "GenSigTimeoutTime_ALL" SG_ 1160 ACM_SBR_Blinking_Req 5000;
BA_ "InvalidValue" SG_ 1160 ACM_SBR_Blinking_Req "null";
VAL_ 897 ACM_Seat_Occupancy_Passenger 0 "Seat_Not_Occupied" 1 "Seat Occupied" 2 "Not_Available" 3 "Failure" ;
VAL_ 897 ACM_Seat_Occupancy_2nd_Row_Dri 0 "Seat_Not_Occupied" 1 "Seat Occupied" 2 "Not_Available" 3 "Failure" ;
VAL_ 897 ACM_Seat_Occupancy_2nd_Row_Pas 0 "Seat_Not_Occupied" 1 "Seat Occupied" 2 "Not_Available" 3 "Failure" ;
VAL_ 897 ACM_Seat_Occupancy_2nd_Row_Mid 0 "Seat_Not_Occupied" 1 "Seat Occupied" 2 "Not_Available" 3 "Failure" ;
VAL_ 897 ACM_Seat_Belt_Status_Passenger 0 "Not_buckled" 1 "Buckled" 2 "Not_Available" 3 "Failure" ;
VAL_ 897 ACM_Seat_Belt_Status_Driver 0 "Not_buckled" 1 "Buckled" 2 "Not_Available" 3 "Failure" ;
VAL_ 897 ACM_Seat_Belt_Status_2nd_Row_Dri 0 "Not_buckled" 1 "Buckled" 2 "Not_Available" 3 "Failure" ;
VAL_ 897 ACM_Seat_Belt_Status_2nd_Row_Mid 0 "Not_buckled" 1 "Buckled" 2 "Not_Available" 3 "Failure" ;
VAL_ 897 ACM_Seat_Belt_Status_2nd_Row_Pas 0 "Not_buckled" 1 "Buckled" 2 "Not_Available" 3 "Failure" ;
VAL_ 905 VCU_IMMO_Sts 0 "init" 1 "pass" 2 "failed" ;
VAL_ 925 BCM_ADAS_AHB_state 0 "OFF State" 1 "HighBeam Passive or Inactive" 2 "HighBeam Active" 3 "Fault" ;
VAL_ 925 BCM_AHB_Override 0 "not used" 1 "Automatic High Beam request" 2 "AHB  Inhibit by Driver" 3 "invalid";
VAL_ 925 BCM_ADAS_AHB_RBPos_feed 0 "Off or low beam" 1 "high beam" 2 "Reserved" 3 "Reserved" 4 "Reserved" 5 "Reserved" 6 "Reserved" 7 "SNA" ;
VAL_ 925 BCM_ADAS_AHB_LBPos_feed 0 "Off or low beam" 1 "high beam" 2 "Reserved" 3 "Reserved" 4 "Reserved" 5 "Reserved" 6 "Reserved" 7 "SNA" ;
VAL_ 925 BCM_AHB_ICON_Feed 0 "Off" 1 "Gray ICON" 2 "Green ICON" 3 "White ICON" 4 "Yellow ICON" 5 "Red ICON" ;
VAL_ 993 VCU_CruiseCtrlSts 0 "OFF" 1 "Standby" 2 "Active" 3 "Override" 4 "Fault" 5 "Reserved" 6 "Reserved" ;
VAL_ 1015 MFS_VoiceRecognitionOn_Off 0 "Button not Pressed" 1 "Short Press" 2 "Long Press" 3 "Reserved" 4 "Signal invalid" ;
VAL_ 1015 MFS_ISAControl 0 "Button not Pressed" 1 "Short Press" 2 "Long Press" 3 "Signal invalid" ;
VAL_ 1015 MFS_CruiseSpeedIncrease 0 "Button not Pressed" 1 "Short Press" 2 "Long Press" 3 "Reserved" 4 "Signal invalid" ;
VAL_ 1015 MFS_TelephoneCall_EndCall 0 "Button not Pressed" 1 "Short Press" 2 "Long Press" 3 "Reserved" 4 "Signal invalid" ;
VAL_ 1015 MFS_LKAControl 0 "Button not Pressed" 1 "Short Press" 2 "Long Press" 3 "Signal invalid" ;
VAL_ 1015 MFS_CruiseGapIncrease 0 "Button not Pressed" 1 "Short Press" 2 "Long Press" 3 "Reserved" 4 "Signal invalid" ;
VAL_ 1015 MFS_CruiseOn_Off 0 "Button not Pressed" 1 "Short Press" 2 "Long Press" 3 "Reserved" 4 "Signal invalid" ;
VAL_ 1015 MFS_CruiseGapDecrease 0 "Button not Pressed" 1 "Short Press" 2 "Long Press" 3 "Reserved" 4 "Signal invalid" ;
VAL_ 1015 MFS_CAN_RESControl 0 "Button not Pressed" 1 "Short Press" 2 "Long Press" 3 "Reserved" ;
VAL_ 1015 MFS_CruiseSpeedDecrease 0 "Button not Pressed" 1 "Short Press" 2 "Long Press" 3 "Reserved" 4 "Signal invalid" ;
VAL_ 1015 MFS_M2Control 0 "Button not Pressed" 1 "Short Press" 2 "Long Press" 3 "Signal invalid" ;
VAL_ 1015 MFS_SourseControl 0 "Button not Pressed" 1 "Short Press" 2 "Long Press" 3 "Reserved" 4 "Signal invalid" ;
VAL_ 1015 MFS_UpControl 0 "Button not Pressed" 1 "Short Press" 2 "Long Press" 3 "Reserved" 4 "Signal invalid" ;
VAL_ 1015 MFS_DownControl 0 "Button not Pressed" 1 "Short Press" 2 "Long Press" 3 "Reserved" 4 "Signal invalid" ;
VAL_ 1015 MFS_LeftControl 0 "Button not Pressed" 1 "Short Press" 2 "Long Press" 3 "Reserved" 4 "Signal invalid" ;
VAL_ 1015 MFS_Failure 0 "No Error" 1 "Error" ;
VAL_ 1015 MFS_RightControl 0 "Button not Pressed" 1 "Short Press" 2 "Long Press" 3 "Reserved" 4 "Signal invalid" ;
VAL_ 1015 MFS_OK_Control 0 "Button not Pressed" 1 "Short Press" 2 "Long Press" 3 "Reserved" 4 "Signal invalid" ;
VAL_ 1025 MHU_SET_SunroofGlassLevel 0 "Closed" 127 "Vent" 150 "Stop" 255 "No Request" ;
VAL_ 1025 MHU_SET_BonnetState 0 "Not pressed" 1 "Pressed" 2 "Reserved" 3 "Signal invalid" ;
VAL_ 1025 MHU_SET_TrunkState 0 "Not pressed" 1 "Pressed" 2 "Reserved" 3 "Signal invalid" ;
VAL_ 1025 MHU_SET_SunroofShaderLevel 0 "Closed" 150 "Stop" 255 "No Request" ;
VAL_ 1025 MHU_SET_DoorSpeedLock 0 "OFF" 1 "5KMH" 2 "10KMH" 3 "15KMH" 4 "20KMH" 5 "25KMH" 6 "Signal invalid" ;
VAL_ 1025 MHU_SET_WelcomeTriggerCondition 0 "Vehicle unLock" 1 "Driver walk toward" 2 "OFF" 3 "Signal invalid" ;
VAL_ 1025 MHU_SET_AutoSunroof 0 "OFF" 1 "Glass Only" 2 "Glass & Shade" 3 "Signal invalid" ;
VAL_ 1025 MHU_SET_RemoteDoorUnlock 0 "Driver door" 1 "All doors" 2 "Reserved" 3 "Signal invalid" ;
VAL_ 1025 MHU_SET_RemoteLockFeedback 0 "Light" 1 "Horn" 2 "Light/Horn" 3 "OFF" 4 "Signal Invalid" ;
VAL_ 1025 MHU_SET_FootkickSensor 0 "OFF" 1 "ON" 2 "Reserved" 3 "Signal invalid" ;
VAL_ 1025 MHU_SET_AutoUnlockDoor 0 "OFF" 1 "On" 2 "Reserved" 3 "Signal Invalid" ;
VAL_ 1025 MHU_SET_RemoteUnlockFeedback 0 "Blinking" 1 "Dimming" 2 "Low Beam ON" 3 "OFF" 4 "Signal Invalid" ;
VAL_ 1025 MHU_SET_Childlock 0 "OFF" 1 "ON" 2 "Reserved" 3 "Signal invalid" ;
VAL_ 1025 MHU_SET_SunroofInitialize 0 "Inactive - Default" 1 "Initialisation" 2 "Manual Open Sunroof" 3 "Manual Close Sunroof" 4 "Manual Open Sunshade" 5 "Manuel Close Sunshade" 6 "Reserved" 7 "Signal invalid" ;
VAL_ 1026 MHU_SET_DayTimeRunningLight 0 "OFF" 1 "ON" 2 "Reserved" 3 "Signal invalid" ;
VAL_ 1025 WalkawayDoorLock 0 "OFF" 1 "ON";
VAL_ 1026 MHU_SET_RearFogLight 0 "OFF" 1 "ON" 2 "Reserved" 3 "Signal invalid" ;
VAL_ 1026 MHU_SET_FrontFogLight 0 "OFF" 1 "ON" 2 "Reserved" 3 "Signal invalid" ;
VAL_ 1026 MHU_SET_WelcomeDimmingHeadlight 0 "OFF" 1 "ON" 2 "Reserved" 3 "Signal invalid" ;
VAL_ 1026 MHU_SET_FootwellLightMode 0 "OFF" 1 "ON" 2 "AUTO" 3 "Signal invalid" ;
VAL_ 1026 MHU_SET_ExteriorLight 0 "OFF" 1 "Parking" 2 "ON" 3 "AUTO" 4 "Signal invalid" ;
VAL_ 1026 MHU_SET_TRWarningSignals 0 "Off BCM warning signals" 1 "On BCM warning signals" 2 "Reserved" 3 "Signal Invalid" ;
VAL_ 1026 MHU_SET_FrontDomeLamp 0 "OFF" 1 "ON" 2 "AUTO" 3 "Signal invalid" ;
VAL_ 1026 MHU_SET_HazardLight 3 "Signal Invalid" 2 "Reserved" 1 "ON" 0 "OFF" ;
VAL_ 1026 MHU_SET_FollowMeHome 0 "OFF" 1 "30 secs" 2 "60 secs" 3 "90 secs" 4 "120 secs" 5 "Signal invalid" ;
VAL_ 1026 MHU_SET_ADB_AHB 0 "OFF" 1 "ON" 2 "Reserved" 3 "Signal Invalid" ;
VAL_ 1026 MHU_SET_WelcomeAnimation 0 "OFF" 1 "Light dance" 2 "Vegas blink" 3 "Pulse and blink" 4 "Reserved" 5 "Signal invalid" ;
VAL_ 1026 MHU_SET_ChargingAnimation 0 "OFF" 1 "ON" 2 "Reserved" 3 "Signal invalid" ;
VAL_ 1026 MHU_SET_Auto_Leveling 0 "OFF" 1 "ON" 2 "Reserved" 3 "Signal Invalid" ;
VAL_ 1027 MHU_VCU_CreepDisable_stt 0 "No request" 1 "Creep Disable request" ;
VAL_ 1027 MHU_BrakeRegenMode 0 "HIGH" 1 "MID" 2 "LOW" 3 "OFF" ;
VAL_ 1027 MHU_ChargeScheduleSet 0 "disable" 1 "Enable" 2 "No effect" 3 "Invalid" ;
VAL_ 1027 MHU_ChargingRequest 0 "Stop charging" 1 "Start charging" 2 "Pause charging" 3 "No effect" ;
VAL_ 1027 MHU_ChgPort_Open_req 0 "No request" 1 "Requesting" 2 "Reserved" 3 "Signal invalid" ;
VAL_ 1027 MHU_SET_DrivingModeSwitch 0 "NORMAL" 1 "ECO" 2 "SPORT" 3 "Signal invalid" ;
VAL_ 1027 MHU_ValetMode_Activation 0 "Inactive" 1 "Active" 2 "No effect" 255 "Invalid" ;
VAL_ 1028 MHU_SET_MirrorAdjustLeft 0 "OFF" 1 "ON" 2 "Reserved" 3 "Signal invalid" ;
VAL_ 1028 MHU_SET_MirrorAdjustRight 0 "OFF" 1 "ON" 2 "Reserved" 3 "Signal invalid" ;
VAL_ 1028 MHU_SET_MirrorManual 0 "Fold" 1 "Unfold" 2 "Reserved" 3 "Signal invalid" ;
VAL_ 1029 MHU_SET_CCUF_AirCondition 0 "Not pressed" 1 "Pressed" 2 "Reserved" 3 "Signal invalid";
VAL_ 1029 MHU_SET_CCUF_AutoAC 0 "Not pressed" 1 "Pressed" 2 "Reserved" 3 "Signal invalid";
VAL_ 1029 MHU_SET_CCUF_MaxAc 0 "Not pressed" 1 "Pressed" 2 "Reserved" 3 "Signal invalid";
VAL_ 1029 MHU_SET_CCUF_FanSpeed 0 "OFF" 1 "Level1" 2 "Level2" 3 "Level3" 4 "Level4" 5 "Level5" 6 "Level6" 7 "Signal invalid" ;
VAL_ 1029 MHU_SET_CCUF_Recirculation 0 "Inside" 1 "Outside" 2 "Auto" 3 "Signal invalid" ;
VAL_ 1029 MHU_SET_CCUF_Ion 0 "Not pressed" 1 "Pressed" 2 "Reserved" 3 "Signal invalid";
VAL_ 1029 MHU_SET_CCUF_FlapPosition 0 "OFF" 1 "Face" 2 "Face and Feet" 3 "Feet" 4 "Feet and Defrost" 5 "Defrost" 6 "Default" 7 "Signal Invalid" ;
VAL_ 1029 MHU_SET_CCUF_SyncClimateZone 0 "Not pressed" 1 "Pressed" 2 "Reserved" 3 "Signal invalid";
VAL_ 1029 MHU_SET_CCUF_TempDriver 32 "16" 33 "16.5" 34 "17" 35 "17.5" 36 "18" 37 "18.5" 38 "19" 39 "19.5" 40 "20" 41 "20.5" 42 "21" 43 "21.5" 44 "22" 45 "22.5" 46 "23" 47 "23.5" 48 "24" 49 "24.5" 50 "25" 51 "25.5" 52 "26" 53 "26.5" 54 "27" 55 "27.5" 56 "28" 57 "28.5" 58 "29" 59 "29.5" 60 "30" 61 "30.5" 62 "31" 63 "31.5" 64 "32" 255 "Invalid Value";
VAL_ 1029 MHU_SET_CCUF_TempPassenger 32 "16" 33 "16.5" 34 "17" 35 "17.5" 36 "18" 37 "18.5" 38 "19" 39 "19.5" 40 "20" 41 "20.5" 42 "21" 43 "21.5" 44 "22" 45 "22.5" 46 "23" 47 "23.5" 48 "24" 49 "24.5" 50 "25" 51 "25.5" 52 "26" 53 "26.5" 54 "27" 55 "27.5" 56 "28" 57 "28.5" 58 "29" 59 "29.5" 60 "30" 61 "30.5" 62 "31" 63 "31.5" 64 "32" 255 "Invalid Value";
VAL_ 1029 MHU_SET_CCUF_FrontDefrost 0 "Not pressed" 1 "Pressed" 2 "Reserved" 3 "Signal invalid";
VAL_ 1030 MHU_SET_SeatHeatingFrontL 0 "OFF" 1 "Level1" 2 "Level2" 3 "Level3" 4 "Signal invalid" ;
VAL_ 1030 MHU_SET_SeatHeatingFrontR 0 "OFF" 1 "Level1" 2 "Level2" 3 "Level3" 4 "Signal invalid" ;
VAL_ 1030 MHU_SET_SeatHeatingReartL 0 "OFF" 1 "Level1" 2 "Level2" 3 "Level3" 4 "Signal invalid" ;
VAL_ 1030 MHU_SET_SeatHeatingRearR 0 "OFF" 1 "Level1" 2 "Level2" 3 "Level3" 4 "Signal invalid" ;
VAL_ 1030 MHU_SET_SeatCoolingFrontL 0 "OFF" 1 "Level1" 2 "Level2" 3 "Level3" 4 "Signal invalid" ;
VAL_ 1030 MHU_SET_SeatCoolingFrontR 0 "OFF" 1 "Level1" 2 "Level2" 3 "Level3" 4 "Signal invalid" ;
VAL_ 1030 MHU_SET_SeatCoolingRearL 0 "OFF" 1 "Level1" 2 "Level2" 3 "Level3" 4 "Signal invalid" ;
VAL_ 1030 MHU_SET_SeatCoolingRearR 0 "OFF" 1 "Level1" 2 "Level2" 3 "Level3" 4 "Signal invalid" ;
VAL_ 1032 MHU_SET_MirrorAuto 0 "OFF" 1 "ON" 2 "Reserved" 3 "Signal invalid" ;
VAL_ 1032 MHU_SET_MirrorAutoUnfold 0 "Vehicle Unlock" 1 "Driver walk toward" 2 "OFF" 3 "Signal invalid" ;
VAL_ 1032 MHU_SET_WLC 0 "OFF" 1 "ON" 2 "Reserved" 3 "Signal invalid" ;
VAL_ 1032 MHU_SET_AutoRearWiper 0 "OFF" 1 "ON" 2 "Reserved" 3 "Signal invalid" ;
VAL_ 1032 MHU_SET_RearHeatedWindow 0 "Not pressed" 1 "Pressed" 2 "Reserved" 3 "Signal invalid" ;
VAL_ 1032 MHU_TPMSReset 0 "Noreset" 1 "Reset" 2 "Reserved" 3 "Signal invalid" ;
VAL_ 1032 MHU_SET_MirrorDefaultSetting 0 "Not pressed" 1 "Pressed" 2 "Reserved" 3 "Signal invalid" ;
VAL_ 1032 MHU_SET_MirrorReverseLink 0 "OFF" 1 "Right Mirror" 2 "Left Mirror" 3 "Both Mirror" ;
VAL_ 1032 MHU_SET_AntiTheftMode 0 "OFF" 1 "Light Only" 2 "Horn Only" 3 "Light and Horn" ;
VAL_ 1032 MHU_SET_WLCReminder 0 "OFF" 1 "ON" 2 "Reserved" 3 "Signal invalid" ;
VAL_ 1032 MHU_SET_ClimateKeepOn 0 "OFF" 1 "PET" 2 "CAMP" 3 "REMOTE CONTROL" ;
VAL_ 1032 MHU_SET_WLC2 0 "OFF" 1 "ON" 2 "Reserved" 3 "Signal invalid" ;
VAL_ 1032 MHU_SET_WLC2Reminder 0 "OFF" 1 "ON" 2 "Reserved" 3 "Signal invalid" ;
VAL_ 1032 MHU_IntrusionAlertStatus 0 "OFF" 1 "ON" 2 "Stop Alarm" 3 "Signal invalid" ;
VAL_ 1036 MHU_DrvSeat_Control_Status 0 "Idle" 1 "Request seat moving" 2 "Reserved" 3 "Invalid value" ;
VAL_ 1042 eCall_state 0 "Off/Inactive" 1 "Faulted/Error" 2 "On/Active - Call Not Triggered Automatically" 3 "On/Active - Call Automatically Triggered" 4 "On/Active - eCall Ongoing" ;
VAL_ 1044 ERR_ST_HOD 0 "NO_ERROR" 1 "HOD_EEPROM_ERROR" 2 "HOD_ROM_ERROR" 3 "HOD_WATCHDOG_ERROR" 4 "HOD_CPU_ERROR" 5 "HOD_GUARD_INTERRUPTION_ERROR" 6 "HOD_SENSE_INTERRUPTION_ERROR" 7 "HOD_CPU_DEFECT_OR_MAT_SHORTAGE" 8 "UNDERVOLTAGE_ERROR" 9 "OVERVOLTAGE_ERROR" 10 "HOD_CODING_ERROR" 11 "HOD_GENERIC_SYSTEM_ERROR" 15 "Not Available" ;
VAL_ 1044 RsErr_HOD 0 "No_error" 1 "error" ;
VAL_ 1044 HOD_status 0 "Init" 1 "Hands OFF" 2 "Hands ON" 3 "Energie_Save_Mode" 4 "HOD error" 5 "Invalid value" 6 "Reserved" 7 "Reserved" 8 "Reserved" 9 "Reserved" 10 "Reserved" 11 "Reserved" 12 "Reserved" 13 "Reserved" 14 "Reserved" 15 "Reserved" ;
VAL_ 1046 BCM_STAT_Mirror 0 "Fold" 1 "Unfold" 2 "Reserved" 3 "Signal Invalid" ;
VAL_ 1046 BCM_STAT_MirrorAdjustLeft 0 "OFF" 1 "ON" 2 "Reserved" 3 "Signal invalid" ;
VAL_ 1046 BCM_STAT_MirrorAdjustRight 0 "OFF" 1 "ON" 2 "Reserved" 3 "Signal invalid" ;
VAL_ 1049 SHVU_STAT_SeatHeatingFrontL 0 "OFF" 1 "Level1" 2 "Level2" 3 "Level3" 4 "Signal invalid" ;
VAL_ 1049 SHVU_STAT_SeatHeatingFrontR 0 "OFF" 1 "Level1" 2 "Level2" 3 "Level3" 4 "Signal invalid" ;
VAL_ 1049 SHVU_STAT_SeatCoolingFrontL 0 "OFF" 1 "Level1" 2 "Level2" 3 "Level3" 4 "Signal invalid" ;
VAL_ 1049 SHVU_STAT_SeatCoolingFrontR 0 "OFF" 1 "Level1" 2 "Level2" 3 "Level3" 4 "Signal invalid" ;
VAL_ 1049 SHVU_STAT_FrontSeatVentSts 0 "Normal Operation" 1 "Failure" 2 "Reserved" 3 "Signal invalid" ;
VAL_ 1050 SHVU_STAT_SeatCoolingRearL 0 "OFF" 1 "Level1" 2 "Level2" 3 "Level3" 4 "Signal invalid" ;
VAL_ 1050 SHVU_STAT_SeatCoolingRearR 0 "OFF" 1 "Level1" 2 "Level2" 3 "Level3" 4 "Signal invalid" ;
VAL_ 1050 SHVU_STAT_SeatHeatingReartL 0 "OFF" 1 "Level1" 2 "Level2" 3 "Level3" 4 "Signal invalid" ;
VAL_ 1050 SHVU_STAT_SeatHeatingRearR 0 "OFF" 1 "Level1" 2 "Level2" 3 "Level3" 4 "Signal invalid" ;
VAL_ 1050 SHVU_STAT_RearSeatVentSts 0 "Normal Operation" 1 "Failure" 2 "Reserved" 3 "Signal invalid" ;
VAL_ 1052 PSM_Seat_track_pos_Dri 0 "Front position" 1 "Not Front position" 2 "Failure" 3 "Invalid Value" ;
VAL_ 1052 PSM_Seat_track_posPas 0 "Front position" 1 "Not Front position" 2 "Failure" 3 "Invalid Value" ;
VAL_ 1053 BCM_STAT_AutoRearWiper 0 "OFF" 1 "ON" 2 "Reserved" 3 "Signal invalid" ;
VAL_ 1053 BCM_STAT_MirrorFoldSetting 0 "Auto Fold OFF" 1 "Auto Fold ON" 2 "Reserved" 3 "Signal invalid" ;
VAL_ 1053 BCM_STAT_IMMO_KeyfobID2 0 "No trigger from MHU" 1 "Fob1" 2 "Fob2" 3 "key illegal" 4 "No key found" 5 "Searching" 6 "Reserved" 7 "Signal invalid" ;
VAL_ 1053 BCM_STAT_MirrorAutoUnfold 0 "Vehicle Unlock" 1 "Driver walk toward" 2 "OFF" 3 "Signal invalid" ;
VAL_ 1053 BCM_STAT_MirrorReverseLink 0 "OFF" 1 "Right Mirror" 2 "Left Mirror" 3 "Both Mirror" ;
VAL_ 1053 BCM_STAT_MirrorDefaultSTATting 0 "Not pressed" 1 "Pressed" 2 "Reserved" 3 "Signal invalid" ;
VAL_ 1053 BCM_STAT_WelcomeTriggerCondition 0 "Vehicle unLock" 1 "Driver walk toward" 2 "OFF" 3 "Signal invalid" ;
VAL_ 1053 BCM_STAT_FrontDomeLamp 0 "OFF" 1 "ON" 2 "AUTO" 3 "Signal invalid" ;
VAL_ 1053 BCM_STAT_FollowMeHome 0 "OFF" 1 "30 secs" 2 "60 secs" 3 "90 secs" 4 "120 secs" 5 "Signal invalid" ;
VAL_ 1053 BCM_STAT_ExteriorLight 0 "OFF" 1 "Parking" 2 "ON" 3 "AUTO" 4 "Signal invalid" ;
VAL_ 1053 BCM_STAT_RemoteLockFeedback 0 "OFF" 1 "Lights and Horn" 2 "Lights Only" 3 "Horn Only" 4 "Reserved" 5 "Reserved" 6 "Reserved" 7 "Signal invalid" ;
VAL_ 1053 BCM_STAT_RemoteDoorUnlock 0 "Reserved" 1 "Driver door" 2 "All doors" 3 "Signal invalid" ;
VAL_ 1053 BCM_STAT_AutoDoorUnlock 0 "OFF" 1 "ON" 2 "Reserved" 3 "Signal invalid" ;
VAL_ 1053 BCM_STAT_WalkawayDoorLock 0 "OFF" 1 "ON";
VAL_ 1053 BCM_STAT_WiperServiceMode 0 "OFF" 1 "ON" 2 "Reserved" 3 "Signal Invalid" ;
VAL_ 1053 BCM_STAT_IMMO_KeyfobID 0 "No Key Found" 1 "ID1" 2 "ID2" 3 "Signal Invalid" ;
VAL_ 1053 BCM_STAT_RearHeatedWindowMirror 0 "OFF" 1 "ON" 2 "Reserved" 3 "Signal invalid" ;
VAL_ 1053 BCM_STAT_AntiTheftMode 0 "OFF" 1 "Light Only" 2 "Horn Only" 3 "Light and Horn" 4 "Signal invalid" ;
VAL_ 1053 BCM_STAT_ClimateKeepOnSts 0 "OFF" 1 "PET" 2 "CAMP" 3 "REMOTE CONTROL" ;
VAL_ 1053 BCM_STAT_FKSfeedback 0 "OFF" 1 "ON" 2 "Reserved" 3 "Signal Invalid" ;
VAL_ 1055 OCS_Passenger_class_stat 1 "Seat Empty or Childseat (Class1)" 2 "Adult (Class2)" 3 "OSC Failure" ;
VAL_ 1058 MHU_STAT_Cluster 0 "OFF" 1 "ON" 2 "Reserved" 3 "Signal invalid" ;
VAL_ 1058 MHU_STAT_Infotainment 0 "OFF" 1 "ON" 2 "Reserved" 3 "Signal invalid" ;
VAL_ 1058 MHU_STAT_MileageUnit 0 "Mile" 1 "KM" 2 "Reserved" 3 "Signal invalid" ;
VAL_ 1058 MHU_STAT_PressureUnit 0 "Bar" 1 "Psi" 2 "Kpa" 3 "Signal invalid" ;
VAL_ 1058 MHU_STAT_TemperatureUnit 0 "Celcius" 1 "Fahrenheit" 2 "Reserved" 3 "Signal invalid" ;
VAL_ 1058 MHU_Operation_State 0 "Sleep - Low power mode" 1 "Standby/Screen OFF" 2 "Booting/Rebooting" 3 "Running" 4 "Standby/Fullscreen" 5 "OTA progess" 6 "Fault" 7 "Signal Invalid" ;
VAL_ 1058 MHU_STAT_Language 0 "Vietnamese" 1 "English" 2 "Spanish" 3 "French" 4 "German" 5 "Dutch" 6 "English (CANADA)" 7 "French (CANADA)" 8 "Russian" 9 "Spanish (Latin America)" 10 "Portuguese" 11 "Portuguese (Brasil)" 12 "Chinese, simplipied" 13 "Chinese, traditional" 14 "Reserved" 15 "Reserved" 16 "Reserved" 17 "Reserved" 18 "Reserved" 19 "Reserved" 20 "Reserved" 21 "Reserved" 22 "Reserved" 23 "Reserved" 24 "Reserved" 25 "Reserved" 26 "Reserved" 27 "Reserved" 28 "Reserved" 29 "Reserved" 30 "Reserved" 31 "Signal invalid" ;
VAL_ 1058 MHU_STAT_EnergyConsumptionUnit 0 "KWH/100KM" 1 "KM/KWH" 2 "Mile per KWH" 3 "KWH/100mil" 4 "Reserved" 5 "Reserved" 6 "Reserved" 7 "Signal invalid" ;
VAL_ 1064 TRMFitted 0 "Unsupported" 1 "Fitted" 2 "Not Fitted" 3 "SNA" ;
VAL_ 1068 PSM_D_DrvSeat_Control_Status 0 "Idle" 1 "Moving by MHU" 2 "Moving by switch" 3 "Failure" 4 "Reserved" 5 "Reserved" 6 "Reserved" 7 "Invalid" ;
VAL_ 1074 MHU_FOTA_State 0 "INIT" 1 "NORMAL" 2 "FOTA FLASHING" 3 "FOTA-SUSPENDED" 4 "FAIL-SAFE-ERROR" 5 "SHUTDOWN" 6 "REMOTE DIAGNOSTICS" 7 "Invalid" ;
VAL_ 1077 BCM_SCM_BC_Button 0 "Button not Pressed" 1 "Short Press" 2 "Long Press" 3 "Signal invalid" ;
VAL_ 1082 VCU_BrakeRegenMode 0 "HIGH" 1 "MID" 2 "LOW" 3 "OFF" ;
VAL_ 1082 VCU_CreepDisable_stt 0 "Enable" 1 "Disable" ;
VAL_ 1082 VCU_Charging_Authen_stt 0 "Not authencating" 1 "Authenticating" 2 "Authen success" 3 "Authen failed" 4 "Forbidden vehicle" 5 "reserved" 6 "reserved" 7 "reserved" ;
VAL_ 1082 VCU_ChgGun_BadConn_stt 0 "No error" 1 "Bad connection" ;
VAL_ 1082 VCU_ChgPort_Open_stt 0 "Closed" 1 "Opening" ;
VAL_ 1082 VCU_Regen_available 0 "Not available" 1 "Available" 2 "Regen limit" 3 "Regen faut" ;
VAL_ 1082 VCU_VehChg_STS 0 "Charging not in progress and gun not plug-in" 1 "Charging in progress" 2 "Charging complete" 3 "Charge fault" 4 "Gun plugged-in, Standby" 5 "Gun plugged-in, Waiting" 6 "Reserved" 7 "Signal Invalid" ;
VAL_ 1082 VCU_ChgGun_Status 0 "Charging gun not plugged" 1 "Locked" 2 "Released" 3 "Error due to plug voltage is higher than 60V." 4 "Error due to electrical failure of lock motor drive pins." 5 "Error due to electrical failure of lock feedback pins" 6 "Error plug lock feedback is received as error from BSW" 7 "Invalid" ;
VAL_ 1082 VCU_ChgPort_Lock_stt 0 "Locked" 1 "Released" ;
VAL_ 1082 VCU_Hvbatt_charging_stt 0 "Not charging" 1 "Charging" ;
VAL_ 1089 RESP_REM_LengthTyp_APM 0 "Functional status" 1 "Active function change" 2 "Reserved" 3 "Signal invalid" ;
VAL_ 1090 WLC_IC_Error 0 "No Error" 1 "Error" ;
VAL_ 1090 WLC_FAN_Error 0 "No Error" 1 "Error" ;
VAL_ 1090 WLC_TempSNSR_Error 0 "No Error" 1 "Error" ;
VAL_ 1090 WLC_Setting_standard 0 "OFF (Disable)" 1 "ON (Enable)" 2 "Default" 3 "Invalid" ;
VAL_ 1090 Transmit_WLC_situation 0 "Power OFF" 1 "Cellphone reminder" 2 "Charging" 3 "Charging complete" 4 "Wakeup" 5 "Error" 6 "Reserved" 7 "Invalid" ;
VAL_ 1090 WLC_VehSpeed_Error 0 "No Error" 1 "Error" ;
VAL_ 1090 WLC_Resp_Error 0 "No Error" 1 "Error" ;
VAL_ 1090 WLC_FOD_Error 0 "No Error" 1 "Error" ;
VAL_ 1090 WLC_Curr_Error 0 "No Error" 1 "Error" ;
VAL_ 1090 WLC_Temp_Error 0 "No Error" 1 "Error" ;
VAL_ 1091 WLC_IC_Error_2 0 "No Error" 1 "Error" ;
VAL_ 1091 WLC_FAN_Error_2 0 "No Error" 1 "Error" ;
VAL_ 1091 WLC_TempSNSR_Error_2 0 "No Error" 1 "Error" ;
VAL_ 1091 WLC_Setting_standard_2 0 "OFF (Disable)" 1 "ON (Enable)" 2 "Default" 3 "Invalid" ;
VAL_ 1091 Transmit_WLC_situation_2 0 "Power OFF" 1 "Cellphone reminder" 2 "Charging" 3 "Charging complete" 4 "Wakeup" 5 "Error" 6 "Reserved" 7 "Invalid" ;
VAL_ 1091 WLC_VehSpeed_Error_2 0 "No Error" 1 "Error" ;
VAL_ 1091 WLC_Resp_Error_2 0 "No Error" 1 "Error" ;
VAL_ 1091 WLC_FOD_Error_2 0 "No Error" 1 "Error" ;
VAL_ 1091 WLC_Curr_Error_2 0 "No Error" 1 "Error" ;
VAL_ 1091 WLC_Temp_Error_2 0 "No Error" 1 "Error" ;
VAL_ 1093 RS_Sol_L 254 "HW failure solar sensor" 255 "Signal invalid" ;
VAL_ 1093 RS_Sol_R 254 "HW failure solar sensor" 255 "Signal invalid" ;
VAL_ 1093 RS_F_LightSensor 0 "No error" 1 "Light sensor error" ;
VAL_ 1093 RS_F_HUD_Sensor 0 "No error" 1 "HUD error" ;
VAL_ 1093 RS_St_LampReq 0 "OFF" 1 "ON" 2 "Reserved" 3 "Invalid" ;
VAL_ 1093 RS_St_CurrentRain 0 "No rain" 1 "level 1(light rain)" 2 "level 2(moderate rain)" 3 "level 3(heavy rain)" 4 "Reserved" 5 "Reserved" 6 "Reserved" 7 "Signal invalid" ;
VAL_ 1093 RS_HUD_illuminance 65535 "Invalid" ;
VAL_ 1095 MHU_SET_TransportMode 0 "No request" 1 "Request ON" 2 "Request OFF" 3 "Signal Invalid" ;
VAL_ 1095 MHU_Request_CarOFF 0 "Not Request" 1 "Request Car goes to OFF" 2 "Reserved" 3 "Signal Invalid" ;
VAL_ 1095 MHU_SET_ChildMode 0 "Child Mode OFF" 1 "Child mode ON" 2 "Reserved" 3 "Signal Invalid" ;
VAL_ 1095 MHU_SET_GameMode 0 "Game mode OFF" 1 "Game mode ON" 2 "Reserved" 3 "Signal Invalid" ;
VAL_ 1095 MHU_SET_KaraokeMode 0 "Karaoke mode OFF" 1 "Karaoke ON" 2 "Reserved" 3 "Signal Invalid" ;
VAL_ 1095 MHU_SET_WashMode 0 "Wash mode OFFt" 1 "Wash mode ON" 2 "Reserved" 3 "Signal Invalid" ;
VAL_ 1095 MHU_SET_StopMode 0 "Creep" 1 "Hold" 2 "Roll" 3 "Signal Invalid" ;
VAL_ 1104 WindowLifterFrontL 0 "No action" 1 "Manual open" 2 "Automatic open" 3 "Manual close" 4 "Automatic close" 5 "Slightly open" 6 "Reserved" 7 "Signal Invalid" ;
VAL_ 1104 WindowLifterFrontR 0 "No action" 1 "Manual open" 2 "Automatic open" 3 "Manual close" 4 "Automatic close" 5 "Slightly open" 6 "Reserved" 7 "Signal Invalid" ;
VAL_ 1104 WindowLifterRearL 0 "No action" 1 "Manual open" 2 "Automatic open" 3 "Manual close" 4 "Automatic close" 5 "Slightly open" 6 "Reserved" 7 "Signal Invalid" ;
VAL_ 1104 WindowLifterRearR 0 "No action" 1 "Manual open" 2 "Automatic open" 3 "Manual close" 4 "Automatic close" 5 "Slightly open" 6 "Reserved" 7 "Signal Invalid" ;
VAL_ 1104 MHU_SET_WindowAutoClose 0 "OFF" 1 "ON" 2 "Reserved" 3 "Signal invalid" ;
VAL_ 1110 OP_WISW_SZL_LIN 0 "No action" 255 "Signal Invalid" ;
VAL_ 1110 COMM_ERR_SZL_LIN 0 "No error" 1 "Error active" ;
VAL_ 1110 BCM_Wiper_Front_Status 0 "OFF" 1 "Mist" 2 "IntermittentAuto" 3 "Low Speed" 4 "High Speed" 5 "Reserved" 6 "Reserved" 7 "Invalid" ;
VAL_ 1110 OP_WIPO_SZL_LIN 0 "Step 1" 1 "Step 2" 2 "Step 3" 4 "Step 4" 7 "Signal Invalid" ;
VAL_ 1110 OP_COLS_SZL_LIN 0 "No action" 255 "Signal Invalid" ;
VAL_ 1110 NOD_ERR_SZL_LIN 0 "NO error" 1 "error active" 2 "error Stat change" 3 "Signal invalid" ;
VAL_ 1110 BCM_Wiper_Rear_Status 0 "OFF" 1 "ON" 2 "Reserved" 3 "Signal Invalid" ;
VAL_ 1111 AmbLight_Error_Z5 0 "No Error" 1 "Error" ;
VAL_ 1111 AmbLight_Error_Z4 0 "No Error" 1 "Error" ;
VAL_ 1111 AmbLight_Error_Z3 0 "No Error" 1 "Error" ;
VAL_ 1111 AmbLight_Error_Z2 0 "No Error" 1 "Error" ;
VAL_ 1111 AmbLight_Error_Z1 0 "No Error" 1 "Error" ;
VAL_ 1112 AmbLightColorZoneReq 0 "no zone" 1 " ALM Zone 1 = CSUV_ALM Cockpit_DSUV_COCKPIT_DRIVER " 2 " ALM Zone 2 = CSUV_ALM Right Front Door_DSUV_COCKPIT_PASSANGER" 3 "ALM Zone 3 = CSUV_ALM Left Front Door_DSUV_FRT_DOOR_LH" 4 "ALM Zone 4 = CSUV_ALM Right Rear Door_DSUV_FRT_DOOR_RH" 5 "ALM Zone 5 = CSUV_ALM Left Rear Door_DSUV_RR_DOOR_RH" 6 "ALM Zone 6 = DSUV_RR_DOOR_RH" 7 "ALM Zone 7 = DSUV_CENTER_CONSOLE_DRIVER" 8 "ALM Zone 8 = DSUV_CENTER_CONSOLE_PASSANGER" 9 "ALM Zone 9 = DSUV_CENTER_CONSOLE_RR_DRIVER" 10 "ALM Zone 10 = DSUV_CENTER_CONSOLE_RR_PASSANGER" ;
VAL_ 1113 AmbLightIntensityTimingTypeReq 0 "None" 1 "Blinking" 2 "Wave" 3 "Morse" 4 "Fading" ;
VAL_ 1124 LDML_LampAssemblySts 0 "Normal" 1 "Fault" 2 "Reserved" 3 "Signal Invalid" ;
VAL_ 1124 LDML_PosLmpSts 0 "OFF" 1 "ON" 2 "Fault" 3 "Signal Invalid" ;
VAL_ 1124 LDML_ControllerSts 0 "Normal" 1 "Fault" 2 "Reserved" 3 "Signal Invalid" ;
VAL_ 1124 LDML_TurnIndicatorSts 0 "OFF" 1 "ON" 2 "Fault" 3 "Signal Invalid" ;
VAL_ 1124 LDML_AuxLBSts 0 "OFF" 1 "ON" 2 "Fault" 3 "Signal Invalid" ;
VAL_ 1124 LDML_LowBeamSts 0 "OFF" 1 "ON" 2 "Fault" 3 "Signal Invalid " ;
VAL_ 1124 LDML_HighBeamSts 0 "OFF" 1 "ON" 2 "Fault" 3 "Signal Invalid" ;
VAL_ 1124 LDML_DayRunningLampSts 0 "OFF" 1 "ON" 2 "Fault" 3 "Signal Invalid" ;
VAL_ 1124 LDML_DayTimeRunningLightFbSts 0 "OFF" 1 "ON" 2 "Reserved" 3 "Signal Invalid" ;
VAL_ 1124 LDML_AutoLvlFbSts 0 "OFF" 1 "ON" 2 "Reserved" 3 "Signal Invalid" ;
VAL_ 1124 LDML_AdptvDrvBeamFbSts 0 "OFF" 1 "ON" 2 "Reserved" 3 "Signal Invalid" ;
VAL_ 1124 LDML_AuxHBSts 0 "OFF" 1 "ON" 2 "Fault" 3 "Signal Invalid" ;
VAL_ 1124 LDML_FollowMeHomeFbSts 0 "OFF" 1 "30 secs" 2 "60 secs" 3 "90 secs" 4 "120 secs" 5 "Signal Invalid" ;
VAL_ 1124 LDML_ExteriorLightFbSts 0 "OFF" 1 "Parking" 2 "Low Beam" 3 "AUTO" 4 "Signal Invalid" ;
VAL_ 1124 LDML_AHB_ICON_Feed 0 "off " 1 "gray icon" 2 "green icon" 3 "SNA" ;
VAL_ 1125 LDMR_LampAssemblySts 0 "Normal" 1 "Fault" 2 "Reserved" 3 "Signal Invalid" ;
VAL_ 1125 LDMR_PosLmpSts 0 "OFF" 1 "ON" 2 "Fault" 3 "Signal Invalid" ;
VAL_ 1125 LDMR_ControllerSts 0 "Normal" 1 "Fault" 2 "Reserved" 3 "Signal Invalid" ;
VAL_ 1125 LDMR_TurnIndicatorSts 0 "OFF" 1 "ON" 2 "Fault" 3 "Signal Invalid" ;
VAL_ 1125 LDMR_AuxLBSts 0 "OFF" 1 "ON" 2 "Fault" 3 "Signal Invalid" ;
VAL_ 1125 LDMR_LowBeamSts 0 "OFF" 1 "ON" 2 "Fault" 3 "Signal Invalid " ;
VAL_ 1125 LDMR_HighBeamSts 0 "OFF" 1 "ON" 2 "Fault" 3 "Signal Invalid" ;
VAL_ 1125 LDMR_DayRunningLampSts 0 "OFF" 1 "ON" 2 "Fault" 3 "Signal Invalid" ;
VAL_ 1125 LDMR_DayTimeRunningLightFbSts 0 "OFF" 1 "ON" 2 "Reserved" 3 "Signal Invalid" ;
VAL_ 1125 LDMR_AutoLvlFbSts 0 "OFF" 1 "ON" 2 "Reserved" 3 "Signal Invalid" ;
VAL_ 1125 LDMR_AdptvDrvBeamFbSts 0 "OFF" 1 "ON" 2 "Reserved" 3 "Signal Invalid" ;
VAL_ 1125 LDMR_AuxHBSts 0 "OFF" 1 "ON" 2 "Fault" 3 "Signal Invalid" ;
VAL_ 1125 LDMR_FollowMeHomeFbSts 0 "OFF" 1 "30 secs" 2 "60 secs" 3 "90 secs" 4 "120 secs" 5 "Signal Invalid" ;
VAL_ 1125 LDMR_ExteriorLightFbSts 0 "OFF" 1 "Parking" 2 "Low Beam" 3 "AUTO" 4 "Signal Invalid" ;
VAL_ 1125 LDMR_AHB_ICON_Feed 0 "off " 1 "gray icon" 2 "green icon" 3 "SNA" ;
VAL_ 1152 PSM_DrvSeatMissalignment 0 "Off" 1 "Driver Power seat malfunction, Seat Initialization required" ;
VAL_ 1152 PSM_PasSeatMisalignment 0 "Off" 1 "Passenger Power seat malfunction, Seat Initialization required" ;
VAL_ 1153 BCM_NoValidKey_1 0 "None" 1 "Alert" ;
VAL_ 1153 BCM_SSB_defect 0 "None" 1 "Alert" ;
VAL_ 1153 BCM_WrongGearPosToStart 0 "None" 1 "Alert" ;
VAL_ 1153 BCM_NoValidKey_2 0 "None" 1 "Alert" ;
VAL_ 1153 BCM_PressBrakeToStart 0 "None" 1 "Alert" ;
VAL_ 1153 BCM_TurnOffPosLightRemindr 0 "None" 1 "Alert" ;
VAL_ 1153 BCM_KeyFob_LowBattery 0 "None" 1 "Alert" ;
VAL_ 1153 BCM_StopLightDefect 0 "None" 1 "Alert" ;
VAL_ 1153 BCM_LowBeamDefect 0 "None" 1 "Alert" ;
VAL_ 1153 BCM_HighBeamDefect 0 "None" 1 "Alert" ;
VAL_ 1153 BCM_PositionLightDefect 0 "None" 1 "Alert" ;
VAL_ 1153 BCM_CHMLS_Defect 0 "None" 1 "Alert" ;
VAL_ 1153 BCM_LicencePlateLight_Defect 0 "None" 1 "Alert" ;
VAL_ 1153 BCM_FrontFog_Defect 0 "None" 1 "Alert" ;
VAL_ 1153 BCM_RearFog_Defect 0 "None" 1 "Alert" ;
VAL_ 1153 BCM_ReverseLightDefect 0 "None" 1 "Alert" ;
VAL_ 1153 BCM_RLS_Malfunction 0 "None" 1 "Alert" ;
VAL_ 1153 BCM_12VBattery_LowLevel 0 "None" 1 "Alert" ;
VAL_ 1153 BCM_ForgetKeyFOBInCar 0 "None" 1 "Alert" ;
VAL_ 1153 BCM_12VBattery_Discharging 0 "None" 1 "Alert" ;
VAL_ 1153 BCM_TurnIndicatorDefect 0 "None" 1 "Alert" ;
VAL_ 1153 BCM_dTPMS_Malfunc 0 "None" 1 "Alert" ;
VAL_ 1153 BCM_dTPMS_Malfunc_LostSensor 0 "None" 1 "Alert" ;
VAL_ 1153 BCM_dTPMS_LowPressure 0 "None" 1 "Alert" ;
VAL_ 1153 BCM_dTPMS_RapidLeak 0 "None" 1 "Alert" ;
VAL_ 1153 BCM_dTPMS_HighTemperature 0 "None" 1 "Alert" ;
VAL_ 1153 BCM_dTPMS_HighPressure 0 "None" 1 "Alert" ;
VAL_ 1153 BCM_dTPMS_LowBattery 0 "None" 1 "Alert" ;
VAL_ 1153 BCM_Keyfob_Leftcar 0 "None" 1 "Alert" ;
VAL_ 1153 BCM_IDB_Brakelight_Malfunction 0 "None" 1 "Alert" ;
VAL_ 1153 BCM_VCU_Brakelight_Malfunction 0 "None" 1 "Alert" ;
VAL_ 1153 BCM_ADAS_Turnlight_Malfunction 0 "None" 1 "Alert" ;
VAL_ 1153 BCM_ADAS_Highbeam_Malfunction 0 "None" 1 "Alert" ;
VAL_ 1153 BCM_ADAS_LowBeam_Malfunction 0 "None" 1 "Alert" ;
VAL_ 1153 BCM_MHU_Malfunction 0 "None" 1 "Alert" ;
VAL_ 1153 BCM_BCM_Malfunction 0 "None" 1 "Alert" ;
VAL_ 1153 BCM_SCM_Malfunction 0 "None" 1 "Alert" ;
VAL_ 1153 BCM_CrashSignalDefect 0 "None" 1 "Alert" ;
VAL_ 1153 BCM_FrontWiperDefect 0 "None" 1 "Alert" ;
VAL_ 1153 BCM_Rear_RightDoorLockDefect 0 "None" 1 "Alert" ;
VAL_ 1153 BCM_RearLeftDoorLockDefect 0 "None" 1 "Alert" ;
VAL_ 1153 BCM_Front_RightDoorLockDefect 0 "None" 1 "Alert" ;
VAL_ 1153 BCM_FrontLeftDoorLockDefect 0 "None" 1 "Alert" ;
VAL_ 1153 BCM_LDML_Malfunction 0 "None" 1 "Alert" ;
VAL_ 1153 BCM_LDMR_Malfunction 0 "None" 1 "Alert" ;
VAL_ 1153 BCM_RLBL_Malfunction 0 "None" 1 "Alert" ;
VAL_ 1153 BCM_RLBR_Malfunction 0 "None" 1 "Alert" ;
VAL_ 1153 BCM_RLT_Malfunction 0 "None" 1 "Alert" ;
VAL_ 1153 BCM_BCM_POWER_Malfunction 0 "None" 1 "Alert" ;
VAL_ 1153 BCM_IDB_AutoHazardBlinking_Malf 0 "None" 1 "Alert" ;
VAL_ 1155 TPMS_FLTirePress 255 "Invalid" ;
VAL_ 1155 TPMS_FRTirePress 255 "Invalid" ;
VAL_ 1155 TPMS_RLTirePress 255 "Invalid" ;
VAL_ 1155 TPMS_RRTirePress 255 "Invalid" ;
VAL_ 1155 TPMS_FLTirePressAlarm 0 "No�warning" 1 "High pressure�warning" 2 "Low pressure�warning" 3 "Quick�leakage" 4 "Lost�Sensor" 5 "Sensor battery�low" 6 "Sensor�failure" 7 "Reserved" ;
VAL_ 1155 TPMS_FRTirePressAlarm 0 "No�warning" 1 "High pressure�warning" 2 "Low pressure�warning" 3 "Quick�leakage" 4 "Lost�Sensor" 5 "Sensor battery�low" 6 "Sensor�failure" 7 "Reserved" ;
VAL_ 1155 TPMS_RLTirePressAlarm 0 "No�warning" 1 "High pressure�warning" 2 "Low pressure�warning" 3 "Quick�leakage" 4 "Lost�Sensor" 5 "Sensor battery�low" 6 "Sensor�failure" 7 "Reserved" ;
VAL_ 1155 TPMS_RRTirePressAlarm 0 "No�warning" 1 "High pressure�warning" 2 "Low pressure�warning" 3 "Quick�leakage" 4 "Lost�Sensor" 5 "Sensor battery�low" 6 "Sensor�failure" 7 "Reserved" ;
VAL_ 1155 TPMS_TirePosition 0 "No any�sensor" 1 "Left Front�tire" 2 "Right Front�tire" 3 "Right Rear�tire" 4 "Left Rear�tire" 5 "reseved" 6 "reseved" 7 "reserved" ;
VAL_ 1155 TPMS_ready2learning 0 "Invalid" 1 "Ready" ;
VAL_ 1155 TPMS_TireTempAlarm 0 "No warning" 1 "High Temperature�Warning" ;
VAL_ 1155 TPMS_LearningStatus 0 "invalid" 1 "Left Front�tire done" 2 "Right Front�tire done" 3 "Right Rear�tire done" 4 "Left Rear�tire done" 5 "All completed" 6 "Failure" 7 "reserved" ;
VAL_ 1155 TPMS_TireTemp 255 "Invalid" ;
VAL_ 1156 APA_MHU_Status 0 "Off" 1 "Standby" 2 "Enable" 3 "Active" 4 "Finished" 5 "Suspend" 6 "abort" 7 "Failed";
VAL_ 1158 TPMS_FLTirePressAlarm2 0 "No warning" 1 "High pressure warning" 2 "Low pressure warning" 3 "Quick leakage" 4 "Lost Sensor" 5 "Sensor battery low" 6 "Sensor failure" 7 "Reserved";
VAL_ 1158 TPMS_FRTirePressAlarm2 0 "No warning" 1 "High pressure warning" 2 "Low pressure warning" 3 "Quick leakage" 4 "Lost Sensor" 5 "Sensor battery low" 6 "Sensor failure" 7 "Reserved";
VAL_ 1158 TPMS_RLTirePressAlarm2 0 "No warning" 1 "High pressure warning" 2 "Low pressure warning" 3 "Quick leakage" 4 "Lost Sensor" 5 "Sensor battery low" 6 "Sensor failure" 7 "Reserved";
VAL_ 1158 TPMS_RRTirePressAlarm2 0 "No warning" 1 "High pressure warning" 2 "Low pressure warning" 3 "Quick leakage" 4 "Lost Sensor" 5 "Sensor battery low" 6 "Sensor failure" 7 "Reserved";
VAL_ 1160 ACM_Malfunction 0 "ACM_Failure" 1 "ACM_Normal_Operation" ;
VAL_ 1160 ACM_Pre_Drive_Check 0 "ACM_Pre_Drive_Check" 1 "ACM_Normal_Operation" ;
VAL_ 1160 ACM_in_Plant_Mode 0 "ACM_in_Plant_Mode" 1 "ACM_in_Normal_Mode" ;
VAL_ 1160 ACM_PAB_Suppression 0 "Not_Suppressed" 1 "Suppressed" 2 "Function Failure" 3 "Invalid_Value" ;
VAL_ 1160 ACM_Airbag_Disabled 0 "ACM_AirBag_Disabled" 1 "ACM_Normal_Operation" ;
VAL_ 1160 ACM_Development_Calibration 0 "ACM_Dev_Calibrated" 1 "ACM_Normal_Operation" ;
VAL_ 1160 ACM_In_Disposal_Mode 0 "ACM_In_Disposal_Mode" 1 "ACM_Normal_Operation" ;
VAL_ 1160 ACM_Seatbelt_Reminder_Request 0 "Seatbelt reminder NOT activated" 1 "Seatbelt reminder activated" ;
VAL_ 1160 ACM_SBR_Chime_Req 0 "No Active Chime" 1 "Active Chime" ;
VAL_ 1160 ACM_SBR_Blinking_Req 0 "No Blinking" 1 "Blinking 1Hz" ;
